VERSION ""

NS_ :

BS_:

BU_: Turbocharger OnBoardDataLogger OffBoardDiagnosticTool2 OffBoardDiagnosticTool1 FileServer ParkingBrakeController SeatControl2 FanDriveController SteeringColumnUnit CommunicationUnitRadio CommunicationUnitSatellite CommunicationUnitCellular PropulsionBatteryCharger ChassisController2 ChassisController1 EngineValveControl AuxiliaryHeater2 AuxiliaryHeater1 ClutchUnit RampControl InformationSystem1 SuspensionSystemController2 OilSensor VehicleDynamicStability ExhaustEmissionController TransmissionDisplay2 TransmissionDisplay1 ClimateControl2 WaterPumpController RearAxleSteeringController LightingOperatorControl SeatController1 IgnitionController2 IgnitionController1 TirePressureController CabController2 CabController1 PneumaticSystemController SuspensionSystemController1 HydraulicPumpController EnduranceBrakingSystem RetarderExhaustEngine2 OnBoardDiagnosticUnit HeadwayController RetarderExhaustEngine1 CabDisplay1 ManagementComputer VirtualTerminal OffVehicleGateway PowerTakeOffFront HitchControl AuxiliaryValveControl BodyController TractorTrailerBridge1 StarterSystem ElectricalSystem VehicleSecurity VehicleNavigation AerodynamicControl ElectricalChargingSystem ClimateControl1 TripRecorder InstrumentCluster SuspensionDriveAxle2 SuspensionDriveAxle1 SuspensionSteerAxle SteeringController FuelSystem CruiseControl RetarderDriveline RetarderEngine BrakesDriveAxle2 BrakesDriveAxle1 BrakesSystemController BrakesSteerAxle AxleDrive2 AxleDrive1 AxleSteering PowerTakeOff ShiftConsoleSecondary ShiftConsolePrimary Transmission2 Transmission1 Engine2 Engine1

BO_ 3221225472 VECTOR__INDEPENDENT_SIG_MSG: 0 Vector__XXX
 SG_ EngIntakeManifold2Press : 24|8@1+ (2,0) [0|500] "kPa" Vector__XXX
 SG_ EngIntakeManifold1AbsPressHiRes : 40|16@1+ (0.1,0) [0|6425.5] "kPa" Vector__XXX
 SG_ RearWasherFunction : 53|3@1+ (1,0) [0|7] "" Vector__XXX
 SG_ FrontOperatorWasherSwitch : 45|3@1+ (1,0) [0|7] "" Vector__XXX
 SG_ FrontNonoperatorWasherSwitch : 42|3@1+ (1,0) [0|7] "" Vector__XXX
 SG_ RearWiperDelayCtrl : 32|8@1+ (0.4,0) [0|100] "%" Vector__XXX
 SG_ FrontNonoperatorWiperDelayCtrl : 24|8@1+ (0.4,0) [0|100] "%" Vector__XXX
 SG_ FrontOperatorWiperDelayCtrl : 16|8@1+ (0.4,0) [0|100] "%" Vector__XXX
 SG_ RearWiperSwitch : 12|4@1+ (1,0) [0|15] "" Vector__XXX
 SG_ FrontOperatorWiperSwitch : 4|4@1+ (1,0) [0|15] "" Vector__XXX
 SG_ FrontNonoperatorWiperSwitch : 0|4@1+ (1,0) [0|15] "" Vector__XXX
 SG_ OprtrsDesiredDelayedLampOffTime : 24|16@1+ (1,0) [0|64255] "s" Vector__XXX
 SG_ OperatorsDesiredBacklight : 16|8@1+ (0.4,0) [0|100] "%" Vector__XXX
 SG_ HighLowBeamSwitch : 14|2@1+ (1,0) [0|3] "" Vector__XXX
 SG_ HazardLightSwitch : 12|2@1+ (1,0) [0|3] "" Vector__XXX
 SG_ TurnSignalSwitch : 8|4@1+ (1,0) [0|15] "" Vector__XXX
 SG_ MainLightSwitch : 4|4@1+ (1,0) [0|15] "" Vector__XXX
 SG_ WorkLightSwitch : 0|4@1+ (1,0) [0|15] "" Vector__XXX
 SG_ EngAltDroopAuxInputSelect : 28|4@1+ (1,0) [0|15] "" Vector__XXX
 SG_ EngAltDroopRemoteAccelSelect : 24|4@1+ (1,0) [0|15] "" Vector__XXX
 SG_ EngAltDroopAccel2Select : 20|4@1+ (1,0) [0|15] "" Vector__XXX
 SG_ EngAltDroopAccel1Select : 16|4@1+ (1,0) [0|15] "" Vector__XXX
 SG_ EngAltRatingSelect : 8|8@1+ (1,0) [0|255] "" Vector__XXX
 SG_ EngAltLowIdleSwitch : 4|2@1+ (1,0) [0|3] "" Vector__XXX
 SG_ EngSynchronizationSwitch : 2|2@1+ (1,0) [0|3] "" Vector__XXX
 SG_ EngAuxGovernorSwitch : 0|2@1+ (1,0) [0|3] "" Vector__XXX
 SG_ EngOprtrPrmryIntrmdtSpeedSelect : 0|4@1+ (1,0) [0|15] "" Vector__XXX
 SG_ TotalCountOfConfigChangesMade : 0|16@1+ (1,0) [0|64255] "counts" Vector__XXX
 SG_ EngOprtrPrmryIntrmdtSpdSlctStte : 0|4@1+ (1,0) [0|15] "" Vector__XXX
 SG_ EngAltDroopAuxInputSelectState : 28|4@1+ (1,0) [0|15] "" Vector__XXX
 SG_ EngAltDrpRemoteAccelSelectState : 24|4@1+ (1,0) [0|15] "" Vector__XXX
 SG_ EngAltDroopAccel2SelectState : 20|4@1+ (1,0) [0|15] "" Vector__XXX
 SG_ EngAltDroopAccel1SelectState : 16|4@1+ (1,0) [0|15] "" Vector__XXX
 SG_ EngAltRatingSelectState : 8|8@1+ (1,0) [0|255] "" Vector__XXX
 SG_ EngAltLowIdleSelectState : 4|2@1+ (1,0) [0|3] "" Vector__XXX
 SG_ EngMultiUnitSyncState : 2|2@1+ (1,0) [0|3] "" Vector__XXX
 SG_ EngAuxGovernorState : 0|2@1+ (1,0) [0|3] "" Vector__XXX
 SG_ EngStartEnableDevice2Config : 12|4@1+ (1,0) [0|15] "" Vector__XXX
 SG_ EngStartEnableDevice1Config : 8|4@1+ (1,0) [0|15] "" Vector__XXX
 SG_ EngStartEnableDevice2 : 2|2@1+ (1,0) [0|3] "" Vector__XXX
 SG_ EngStartEnableDevice1 : 0|2@1+ (1,0) [0|3] "" Vector__XXX
 SG_ ECUType : 24|8@1+ (1,0) [0|255] "" Vector__XXX
 SG_ ECULocation : 16|8@1+ (1,0) [0|255] "" Vector__XXX
 SG_ ECUSerialNumber : 8|8@1+ (1,0) [0|255] "" Vector__XXX
 SG_ ECUPartNumber : 0|8@1+ (1,0) [0|255] "" Vector__XXX
 SG_ BrakeTempWarning : 0|2@1+ (1,0) [0|3] "" Vector__XXX
 SG_ PrkngBrkeActuatorFullyActivated : 24|2@1+ (1,0) [0|3] "" Vector__XXX
 SG_ XBRAccelerationLimit : 16|8@1+ (0.1,-12.5) [-12.5|12.5] "m/s²" Vector__XXX
 SG_ XBRActiveCtrlMode : 12|4@1+ (1,0) [0|15] "" Vector__XXX
 SG_ XBRSystemState : 10|2@1+ (1,0) [0|3] "" Vector__XXX
 SG_ FoundationBrakeUse : 8|2@1+ (1,0) [0|3] "" Vector__XXX
 SG_ HillHolderMode : 5|3@1+ (1,0) [0|7] "" Vector__XXX
 SG_ HaltBrakeMode : 2|3@1+ (1,0) [0|7] "" Vector__XXX
 SG_ EngExhstVlvActtonSystemOilPress : 24|16@1+ (0.00390625,0) [0|251] "MPa" Vector__XXX
 SG_ EngExhstGsRcrcltion1OutletPress : 40|8@1+ (2,0) [0|500] "kPa" Vector__XXX
 SG_ EngExhstGsRcrcltion1IntakePress : 16|8@1+ (2,0) [0|500] "kPa" Vector__XXX
 SG_ EngIntkVlvActtionSystemOilPress : 0|16@1+ (0.00390625,0) [0|251] "MPa" Vector__XXX
 SG_ TransitRunStatus : 20|2@1+ (1,0) [0|3] "" Vector__XXX
 SG_ VehicleUseStatus : 18|2@1+ (1,0) [0|3] "" Vector__XXX
 SG_ SilentAlarmStatus : 16|2@1+ (1,0) [0|3] "" Vector__XXX
 SG_ PatronCount : 8|8@1+ (1,0) [0|250] "" Vector__XXX
 SG_ TypeOfPassengerCount : 0|8@1+ (1,0) [0|255] "" Vector__XXX
 SG_ NmbrOfBytsInMlpstIdentification : 0|8@1+ (1,0) [0|250] "" Vector__XXX
 SG_ Agency : 0|8@1+ (1,0) [0|255] "" Vector__XXX
 SG_ NmbrOfBytsInTrnstAssgndBlckIdntt : 24|8@1+ (1,0) [0|250] "" Vector__XXX
 SG_ NmbrOfBytsInTrnstAssgndRnIdntty : 16|8@1+ (1,0) [0|250] "" Vector__XXX
 SG_ NmbrOfBytsInTrnstAssgndRtIdntty : 8|8@1+ (1,0) [0|250] "" Vector__XXX
 SG_ VehicleID : 16|16@1+ (1,0) [0|65535] "counts" Vector__XXX
 SG_ StrobeActivationCtrlStatus : 14|2@1+ (1,0) [0|3] "" Vector__XXX
 SG_ TransitDoorEnable : 12|2@1+ (1,0) [0|3] "" Vector__XXX
 SG_ PriorityOfRespSentByEmitter : 8|4@1+ (1,0) [0|15] "" Vector__XXX
 SG_ IntersectionPreemptionRq_Resp : 6|2@1+ (1,0) [0|3] "" Vector__XXX
 SG_ TransitRouteIDUsage : 4|2@1+ (1,0) [0|3] "" Vector__XXX
 SG_ RangeCodeEnable : 2|2@1+ (1,0) [0|3] "" Vector__XXX
 SG_ DriversFareboxSecurityCode : 104|16@1+ (1,0) [0|65535] "counts" Vector__XXX
 SG_ AssignedBlock : 88|16@1+ (1,0) [0|65535] "counts" Vector__XXX
 SG_ AssignedRun : 72|16@1+ (1,0) [0|65535] "counts" Vector__XXX
 SG_ AssignedRoute : 56|16@1+ (1,0) [0|65535] "counts" Vector__XXX
 SG_ PatternNumber : 40|16@1+ (1,0) [0|65535] "counts" Vector__XXX
 SG_ TripNumber : 24|16@1+ (1,0) [0|65535] "counts" Vector__XXX
 SG_ FarePresets : 16|8@1+ (1,0) [0|255] "" Vector__XXX
 SG_ TripDirection : 8|4@1+ (1,0) [0|15] "" Vector__XXX
 SG_ TripStatus : 2|3@1+ (1,0) [0|7] "" Vector__XXX
 SG_ FareboxServiceStatus : 0|2@1+ (1,0) [0|3] "" Vector__XXX
 SG_ TransferSold : 56|8@1+ (1,0) [0|255] "" Vector__XXX
 SG_ RouteNumber : 40|12@1+ (1,0) [0|4095] "" Vector__XXX
 SG_ TransferType : 35|5@1+ (1,0) [0|31] "" Vector__XXX
 SG_ TypeOfService : 32|3@1+ (1,0) [0|7] "" Vector__XXX
 SG_ InitialFareAgency : 24|5@1+ (1,0) [0|31] "" Vector__XXX
 SG_ PassCategory : 20|4@1+ (1,0) [0|15] "" Vector__XXX
 SG_ FareValidity : 16|4@1+ (1,0) [0|15] "" Vector__XXX
 SG_ PaymentDetails : 12|4@1+ (1,0) [0|15] "" Vector__XXX
 SG_ TypeOfFare : 8|4@1+ (1,0) [0|15] "" Vector__XXX
 SG_ PassengerType : 4|4@1+ (1,0) [0|15] "" Vector__XXX
 SG_ TransactionType : 0|4@1+ (1,0) [0|15] "" Vector__XXX
 SG_ FareboxAlarmIdentifier : 8|7@1+ (1,0) [0|127] "" Vector__XXX
 SG_ FareboxEmergencyStatus : 0|2@1+ (1,0) [0|3] "" Vector__XXX
 SG_ ReferenceTirePress_33 m51 : 8|8@1+ (8,0) [0|2000] "kPa" Vector__XXX
 SG_ ReferenceTirePress_32 m50 : 8|8@1+ (8,0) [0|2000] "kPa" Vector__XXX
 SG_ ReferenceTirePress_31 m49 : 8|8@1+ (8,0) [0|2000] "kPa" Vector__XXX
 SG_ ReferenceTirePress_30 m48 : 8|8@1+ (8,0) [0|2000] "kPa" Vector__XXX
 SG_ ReferenceTirePress_23 m35 : 8|8@1+ (8,0) [0|2000] "kPa" Vector__XXX
 SG_ ReferenceTirePress_22 m34 : 8|8@1+ (8,0) [0|2000] "kPa" Vector__XXX
 SG_ ReferenceTirePress_21 m33 : 8|8@1+ (8,0) [0|2000] "kPa" Vector__XXX
 SG_ ReferenceTirePress_20 m32 : 8|8@1+ (8,0) [0|2000] "kPa" Vector__XXX
 SG_ ReferenceTirePress_13 m19 : 8|8@1+ (8,0) [0|2000] "kPa" Vector__XXX
 SG_ ReferenceTirePress_12 m18 : 8|8@1+ (8,0) [0|2000] "kPa" Vector__XXX
 SG_ ReferenceTirePress_11 m17 : 8|8@1+ (8,0) [0|2000] "kPa" Vector__XXX
 SG_ ReferenceTirePress_10 m16 : 8|8@1+ (8,0) [0|2000] "kPa" Vector__XXX
 SG_ ReferenceTirePress_01 m1 : 8|8@1+ (8,0) [0|2000] "kPa" Vector__XXX
 SG_ ReferenceTirePress_00 m0 : 8|8@1+ (8,0) [0|2000] "kPa" Vector__XXX
 SG_ NMHCConvertingCatalystCompleted : 60|1@1+ (1,0) [0|1] "" Vector__XXX
 SG_ NMHCConvertingCatalystEnabled : 44|1@1+ (1,0) [0|1] "" Vector__XXX
 SG_ NOxConvertingCatalystAdsorberCom : 59|1@1+ (1,0) [0|1] "" Vector__XXX
 SG_ NOxConvertingCatalystAdsorberEna : 43|1@1+ (1,0) [0|1] "" Vector__XXX
 SG_ DieselParticulateFilterCompleted : 58|1@1+ (1,0) [0|1] "" Vector__XXX
 SG_ DieselParticulateFilterEnabled : 42|1@1+ (1,0) [0|1] "" Vector__XXX
 SG_ BoostPressureControlSystemComple : 57|1@1+ (1,0) [0|1] "" Vector__XXX
 SG_ BoostPressureCtrlSystemEnabled : 41|1@1+ (1,0) [0|1] "" Vector__XXX
 SG_ MisfireMonitoringComplete : 28|1@1+ (1,0) [0|1] "" Vector__XXX
 SG_ MisfireMonitoringEnabled : 24|1@1+ (1,0) [0|0] "" Vector__XXX
 SG_ FuelSystemMonitoringEnabled : 25|1@1+ (1,0) [0|1] "" Vector__XXX
 SG_ ComprehensiveComptMonComplete : 30|1@1+ (1,0) [0|1] "" Vector__XXX
 SG_ ComprehensiveCompMonEnabled : 26|1@1+ (1,0) [0|1] "" Vector__XXX
 SG_ SecondAirSystemMonComplete : 51|1@1+ (1,0) [0|1] "" Vector__XXX
 SG_ SecondAirSystemMonEnabled : 35|1@1+ (1,0) [0|1] "" Vector__XXX
 SG_ OxygenSensorMonComplete : 53|1@1+ (1,0) [0|1] "" Vector__XXX
 SG_ OxygenSensorMonEnabled : 37|1@1+ (1,0) [0|1] "" Vector__XXX
 SG_ OxygenSensorHeaterMonComplete : 54|1@1+ (1,0) [0|1] "" Vector__XXX
 SG_ OxygenSensorHeaterMonEnabled : 38|1@1+ (1,0) [0|1] "" Vector__XXX
 SG_ HeatedCatalystMonComplete : 49|1@1+ (1,0) [0|1] "" Vector__XXX
 SG_ HeatedCatalystMonEnabled : 33|1@1+ (1,0) [0|1] "" Vector__XXX
 SG_ EvaporativeSystemMonComplete : 50|1@1+ (1,0) [0|1] "" Vector__XXX
 SG_ EvaporativeSystemMonEnabled : 34|1@1+ (1,0) [0|1] "" Vector__XXX
 SG_ EGRSystemMonitoringComplete : 55|1@1+ (1,0) [0|1] "" Vector__XXX
 SG_ EGRSystemMonitoringEnabled : 39|1@1+ (1,0) [0|1] "" Vector__XXX
 SG_ ColdStartAidSystemMonComplete : 56|1@1+ (1,0) [0|1] "" Vector__XXX
 SG_ ColdStartAidSystemMonEnabled : 40|1@1+ (1,0) [0|1] "" Vector__XXX
 SG_ CatalystMonComplete : 48|1@1+ (1,0) [0|1] "" Vector__XXX
 SG_ CatalystMonEnabled : 32|1@1+ (1,0) [0|1] "" Vector__XXX
 SG_ ACSystemRefrigerantMonComplete : 52|1@1+ (1,0) [0|1] "" Vector__XXX
 SG_ ACSystemRefrigerantMonEnabled : 36|1@1+ (1,0) [0|1] "" Vector__XXX
 SG_ FuelSystemMonitoringComplete : 29|1@1+ (1,0) [0|1] "" Vector__XXX
 SG_ NumOfWarmUpsSinceDTCsCleared : 16|8@1+ (1,0) [0|250] "" Vector__XXX
 SG_ TimeSinceEngineStart : 0|16@1+ (1,0) [0|64255] "sec" Vector__XXX
 SG_ ExpandedFreezeFrameLength : 0|8@1+ (1,0) [0|255] "Byte" Vector__XXX
 SG_ SPNSupported1High : 21|3@1+ (1,0) [0|7] "" Vector__XXX
 SG_ SPNSupportTypeSTR3 : 82|1@1+ (1,0) [0|1] "" Vector__XXX
 SG_ SPNSupportTypeSTR2 : 81|1@1+ (1,0) [0|1] "" Vector__XXX
 SG_ SPNSupportTypeEFF3 : 80|1@1+ (1,0) [0|1] "" Vector__XXX
 SG_ SPNSupportTypeEFF2 : 48|1@1+ (1,0) [0|1] "" Vector__XXX
 SG_ SPNSupportTypeDS3 : 50|1@1+ (1,0) [0|1] "" Vector__XXX
 SG_ SPNSupportTypeDS2 : 49|1@1+ (1,0) [0|1] "" Vector__XXX
 SG_ SPNSupported3High : 85|3@1+ (1,0) [0|7] "" Vector__XXX
 SG_ SPNSupported2High : 53|3@1+ (1,0) [0|7] "" Vector__XXX
 SG_ SPNSupported3 : 64|16@1+ (1,0) [0|65535] "" Vector__XXX
 SG_ SPNSupported2 : 32|16@1+ (1,0) [0|65535] "" Vector__XXX
 SG_ SPNDataLength3 : 88|8@1+ (1,0) [0|240] "" Vector__XXX
 SG_ SPNSupportTypeSTR1 : 18|1@1+ (1,0) [0|1] "" Vector__XXX
 SG_ SPNSupportTypeDS1 : 17|1@1+ (1,0) [0|1] "" Vector__XXX
 SG_ SPNSupportTypeEFF1 : 16|1@1+ (1,0) [0|1] "" Vector__XXX
 SG_ SPNDataLength2 : 56|8@1+ (1,0) [0|240] "" Vector__XXX
 SG_ SPNDataLength1 : 24|8@1+ (1,0) [0|240] "" Vector__XXX
 SG_ SPNSupported1 : 0|16@1+ (1,0) [0|65535] "" Vector__XXX
 SG_ EngAirStartPress : 0|8@1+ (4,0) [0|1000] "kPa" Vector__XXX
 SG_ EngTurboOilLevelSwitch : 30|2@1+ (1,0) [0|3] "" Vector__XXX
 SG_ EngTurbo1Speed : 8|16@1+ (4,0) [0|257020] "rpm" Vector__XXX
 SG_ EngTurboLubeOilPress1 : 0|8@1+ (4,0) [0|1000] "kPa" Vector__XXX
 SG_ EngTotalIdleHours : 32|32@1+ (0.05,0) [0|210554060.75] "hr" Vector__XXX
 SG_ EngTotalIdleFuelUsed : 0|32@1+ (0.5,0) [0|2105540607.5] "L" Vector__XXX
 SG_ EngInjectorMeteringRail2Press : 48|16@1+ (0.00390625,0) [0|251] "MPa" Vector__XXX
 SG_ EngInjectorTimingRail1Press : 32|16@1+ (0.00390625,0) [0|251] "MPa" Vector__XXX
 SG_ EngInjectorMeteringRail1Press : 16|16@1+ (0.00390625,0) [0|251] "MPa" Vector__XXX
 SG_ EngInjectionCtrlPress : 0|16@1+ (0.00390625,0) [0|251] "MPa" Vector__XXX
 SG_ NmbrOfSftwrIdentificationFields : 0|8@1+ (1,0) [0|250] "steps" Vector__XXX
 SG_ SoftwareID3 : 24|8@1+ (1,0) [0|255] "" Vector__XXX
 SG_ SoftwareID2 : 16|8@1+ (1,0) [0|255] "" Vector__XXX
 SG_ SoftwareID1 : 8|8@1+ (1,0) [0|255] "" Vector__XXX
 SG_ AuxI_O16 : 24|2@1+ (1,0) [0|3] "" Vector__XXX
 SG_ AuxI_O15 : 26|2@1+ (1,0) [0|3] "" Vector__XXX
 SG_ AuxI_O14 : 28|2@1+ (1,0) [0|3] "" Vector__XXX
 SG_ AuxI_O13 : 30|2@1+ (1,0) [0|3] "" Vector__XXX
 SG_ AuxI_O12 : 16|2@1+ (1,0) [0|3] "" Vector__XXX
 SG_ AuxI_O11 : 18|2@1+ (1,0) [0|3] "" Vector__XXX
 SG_ AuxI_O10 : 20|2@1+ (1,0) [0|3] "" Vector__XXX
 SG_ AuxI_O09 : 22|2@1+ (1,0) [0|3] "" Vector__XXX
 SG_ AuxI_O08 : 8|2@1+ (1,0) [0|3] "" Vector__XXX
 SG_ AuxI_O07 : 10|2@1+ (1,0) [0|3] "" Vector__XXX
 SG_ AuxI_O06 : 12|2@1+ (1,0) [0|3] "" Vector__XXX
 SG_ AuxI_O05 : 14|2@1+ (1,0) [0|3] "" Vector__XXX
 SG_ AuxI_O04 : 0|2@1+ (1,0) [0|3] "" Vector__XXX
 SG_ AuxI_O03 : 2|2@1+ (1,0) [0|3] "" Vector__XXX
 SG_ AuxI_O02 : 4|2@1+ (1,0) [0|3] "" Vector__XXX
 SG_ AuxI_O01 : 6|2@1+ (1,0) [0|3] "" Vector__XXX
 SG_ AuxI_OChannel2 : 48|16@1+ (1,0) [0|64255] "counts" Vector__XXX
 SG_ AuxI_OChannel1 : 32|16@1+ (1,0) [0|64255] "counts" Vector__XXX
 SG_ AddressAssignment : 64|8@1+ (1,0) [0|255] "" Vector__XXX
 SG_ Alt4Status : 22|2@1+ (1,0) [0|3] "" Vector__XXX
 SG_ Alt3Status : 20|2@1+ (1,0) [0|3] "" Vector__XXX
 SG_ Alt2Status : 18|2@1+ (1,0) [0|3] "" Vector__XXX
 SG_ Alt1Status : 16|2@1+ (1,0) [0|3] "" Vector__XXX
 SG_ AltSpeed : 0|16@1+ (0.5,0) [0|32127.5] "rpm" Vector__XXX
 SG_ TestIdentifierSupported : 0|64@1+ (1,0) [1|1.8446744074e+19] "" Vector__XXX
 SG_ TestType : 8|8@1+ (1,0) [1|64] "" Vector__XXX
 SG_ BoostPressureControlSystemStatus : 57|1@1- (1,0) [0|0] "" Vector__XXX
 SG_ DieselParticulateFilterStatus : 58|1@1- (1,0) [0|0] "" Vector__XXX
 SG_ NOxConvertingCatalystAdsorberSta : 59|1@1- (1,0) [0|0] "" Vector__XXX
 SG_ NMHCConvertingCatalystStatus : 60|1@1- (1,0) [0|0] "" Vector__XXX
 SG_ BoostPressureControlSystemSuppor : 41|1@1- (1,0) [0|0] "" Vector__XXX
 SG_ DieselParticulateFilterSupport : 42|1@1- (1,0) [0|0] "" Vector__XXX
 SG_ NOxConvertingCatalystAdsorberSup : 43|1@1- (1,0) [0|0] "" Vector__XXX
 SG_ NMHCConvertingCatalystSupport : 44|1@1- (1,0) [0|0] "" Vector__XXX
 SG_ MisfireMonitoringSupport : 24|1@1+ (1,0) [0|0] "" Vector__XXX
 SG_ OBDCompliance : 16|8@1+ (1,0) [0|240] "" Vector__XXX
 SG_ PreviouslyActiveTroubleCodes : 8|8@1+ (1,0) [0|240] "" Vector__XXX
 SG_ ActiveTroubleCodes : 0|8@1+ (1,0) [0|240] "" Vector__XXX
 SG_ SecondAirSystemMonStatus : 51|1@1+ (1,0) [0|1] "" Vector__XXX
 SG_ EvaporativeSystemMonStatus : 50|1@1+ (1,0) [0|1] "" Vector__XXX
 SG_ ACSystemRefrigerantMonStatus : 52|1@1+ (1,0) [0|1] "" Vector__XXX
 SG_ OxygenSensorHeaterMonStatus : 54|1@1+ (1,0) [0|1] "" Vector__XXX
 SG_ OxygenSensorMonStatus : 53|1@1+ (1,0) [0|1] "" Vector__XXX
 SG_ EGRSystemMonitoringStatus : 55|1@1+ (1,0) [0|1] "" Vector__XXX
 SG_ CatalystMonStatus : 48|1@1+ (1,0) [0|1] "" Vector__XXX
 SG_ ColdStartAidSystemMonStatus : 56|1@1+ (1,0) [0|1] "" Vector__XXX
 SG_ HeatedCatalystMonStatus : 49|1@1+ (1,0) [0|0] "" Vector__XXX
 SG_ CatalystMonSupp : 32|1@1+ (1,0) [0|1] "" Vector__XXX
 SG_ ColdStartAidSystemMonSupp : 40|1@1+ (1,0) [0|1] "" Vector__XXX
 SG_ HeatedCatalystMonSupp : 33|1@1+ (1,0) [0|0] "" Vector__XXX
 SG_ EvaporativeSystemMonSupp : 34|1@1+ (1,0) [0|1] "" Vector__XXX
 SG_ SecondAirSystemMonSupp : 35|1@1+ (1,0) [0|1] "" Vector__XXX
 SG_ ACSystemRefrigerantMonSupp : 36|1@1+ (1,0) [0|1] "" Vector__XXX
 SG_ OxygenSensorMonSupp : 37|1@1+ (1,0) [0|1] "" Vector__XXX
 SG_ OxygenSensorHeaterMonSupp : 38|1@1+ (1,0) [0|1] "" Vector__XXX
 SG_ EGRSystemMonitoringSupp : 39|1@1+ (1,0) [0|1] "" Vector__XXX
 SG_ MisfireMonitoringStatus : 28|1@1+ (1,0) [0|0] "" Vector__XXX
 SG_ ComprehensiveCompMonStatus : 30|1@1+ (1,0) [0|1] "" Vector__XXX
 SG_ FuelSystemMonitoringStatus : 29|1@1+ (1,0) [0|1] "" Vector__XXX
 SG_ ComprehensiveComponentMonSupp : 26|1@1+ (1,0) [0|0] "" Vector__XXX
 SG_ FuelSystemMonitoringSupport : 25|1@1+ (1,0) [0|1] "" Vector__XXX
 SG_ EngIntakeManifold1Press : 48|8@1+ (2,0) [0|500] "kPa" Vector__XXX
 SG_ FreezeFrameLength : 0|8@1+ (1,0) [0|255] "Byte" Vector__XXX
 SG_ EngSpeed : 56|16@1+ (0.125,0) [0|8031.875] "rpm" Vector__XXX
 SG_ EngTorqueMode : 40|4@1+ (1,0) [0|15] "" Vector__XXX
 SG_ WheelBasedVehicleSpeed : 88|16@1+ (0.00390625,0) [0|250.996] "km/h" Vector__XXX
 SG_ EngPercentLoadAtCurrentSpeed : 72|8@1+ (1,0) [0|250] "%" Vector__XXX
 SG_ PneumaticControlLine : 20|2@1+ (1,0) [0|1] "" Vector__XXX
 SG_ ABSOffroadRequest : 18|2@1+ (1,0) [0|1] "" Vector__XXX
 SG_ TwoElCircuitsBrakeDemand : 16|2@1+ (1,0) [0|1] "" Vector__XXX
 SG_ BodyPressure : 48|8@1+ (0.1,0) [0|25] "bar" Vector__XXX
 SG_ BodyFluidLevel : 32|16@1+ (2,0) [0|128510] "L" Vector__XXX
 SG_ ThermalBodyTemperature : 24|8@1+ (1,-125) [-125|125] "°C" Vector__XXX
 SG_ RearObstacleDistance : 16|8@1+ (2,0) [0|500] "cm" Vector__XXX
 SG_ AntiTheftDeviceStatus : 2|2@1+ (1,0) [0|1] "" Vector__XXX
 SG_ ODDStatus : 0|2@1+ (1,0) [0|1] "" Vector__XXX
 SG_ TransInertiaBrakeActuator : 46|2@1+ (1,0) [0|3] "" Vector__XXX
 SG_ TransDefuelActuator : 44|2@1+ (1,0) [0|3] "" Vector__XXX
 SG_ TransLockupClutchActuator : 42|2@1+ (1,0) [0|3] "" Vector__XXX
 SG_ TransClutchActuator : 40|2@1+ (1,0) [0|3] "" Vector__XXX
 SG_ TransSplitterIndirectActuator : 38|2@1+ (1,0) [0|3] "" Vector__XXX
 SG_ TransSplitterDirectActuator : 36|2@1+ (1,0) [0|3] "" Vector__XXX
 SG_ TransRangeLowActuator : 34|2@1+ (1,0) [0|3] "" Vector__XXX
 SG_ TransRangeHighActuator : 32|2@1+ (1,0) [0|3] "" Vector__XXX
 SG_ TransShiftFingerGearActuator2 : 30|2@1+ (1,0) [0|3] "" Vector__XXX
 SG_ TransShiftFingerRailActuator2 : 28|2@1+ (1,0) [0|3] "" Vector__XXX
 SG_ TransShiftFingerGearActuator1 : 26|2@1+ (1,0) [0|3] "" Vector__XXX
 SG_ TransShiftFingerRailActuator1 : 24|2@1+ (1,0) [0|3] "" Vector__XXX
 SG_ TrnsShftFngrCenterRailIndicator : 20|2@1+ (1,0) [0|3] "" Vector__XXX
 SG_ TrnsShftFngrEngagementIndicator : 18|2@1+ (1,0) [0|3] "" Vector__XXX
 SG_ TrnsShiftFingerNeutralIndicator : 16|2@1+ (1,0) [0|3] "" Vector__XXX
 SG_ TransShiftFingerRailPos : 8|8@1+ (0.4,0) [0|100] "%" Vector__XXX
 SG_ TransShiftFingerGearPos : 0|8@1+ (0.4,0) [0|100] "%" Vector__XXX
 SG_ PneumaticSupplyPressure : 56|8@1+ (5,0) [0|1250] "kPa" Vector__XXX
 SG_ BrakeTemperature : 48|8@1+ (10,0) [0|2500] "°C" Vector__XXX
 SG_ BrakeLining : 40|8@1+ (0.4,0) [0|100] "%" Vector__XXX
 SG_ TyrePressure : 32|8@1+ (10,0) [0|2500] "kPa" Vector__XXX
 SG_ TyreWheelIdentTemp2 : 28|4@1+ (1,0) [0|15] "" Vector__XXX
 SG_ TyreWheelIdentTemp1 : 24|4@1+ (1,0) [0|15] "" Vector__XXX
 SG_ TyreWheelIdentPressure2 : 12|4@1+ (1,0) [0|15] "" Vector__XXX
 SG_ TyreWheelIdentPressure1 : 8|4@1+ (1,0) [0|15] "" Vector__XXX
 SG_ TyreWheelIdentLining2 : 20|4@1+ (1,0) [0|15] "" Vector__XXX
 SG_ TyreWheelIdentLining1 : 16|4@1+ (1,0) [0|15] "" Vector__XXX
 SG_ VehiclePneumSupplySuff : 6|2@1+ (1,0) [0|1] "" Vector__XXX
 SG_ BrakeTemperatureStatus : 4|2@1+ (1,0) [0|1] "" Vector__XXX
 SG_ BrakeLiningSufficient : 2|2@1+ (1,0) [0|1] "" Vector__XXX
 SG_ TyrePressureSufficient : 0|2@1+ (1,0) [0|1] "" Vector__XXX
 SG_ TransSynchronizerBrakeValue : 8|8@1+ (0.4,0) [0|100] "%" Vector__XXX
 SG_ TransSynchronizerClutchValue : 0|8@1+ (0.4,0) [0|100] "%" Vector__XXX
 SG_ ReferenceRetarderTorque : 48|16@1+ (1,0) [0|64255] "Nm" Vector__XXX
 SG_ AxleLoadSum : 32|16@1+ (2,0) [0|128510] "kg" Vector__XXX
 SG_ LoadingRampApproachAssist : 24|2@1+ (1,0) [0|1] "" Vector__XXX
 SG_ SpringBrakeEngaged : 22|2@1+ (1,0) [0|1] "" Vector__XXX
 SG_ ElectrLoadPropFunc : 18|2@1+ (1,0) [0|1] "" Vector__XXX
 SG_ SpringBrakeInstalled : 16|2@1+ (1,0) [0|1] "" Vector__XXX
 SG_ ElecSupplyOfNonBrakingSys : 14|2@1+ (1,0) [0|1] "" Vector__XXX
 SG_ AmberWarningSignalReq : 12|2@1+ (1,0) [0|1] "" Vector__XXX
 SG_ RedWarningSignalRequest : 10|2@1+ (1,0) [0|1] "" Vector__XXX
 SG_ VehicleElectrSupplySuff : 8|2@1+ (1,0) [0|1] "" Vector__XXX
 SG_ TransForwardDirectionSwitch : 12|2@1+ (1,0) [0|3] "" Vector__XXX
 SG_ TransNeutralSwitch : 10|2@1+ (1,0) [0|3] "" Vector__XXX
 SG_ TransReverseDirectionSwitch : 8|2@1+ (1,0) [0|3] "" Vector__XXX
 SG_ TransLowRangeSenseSwitch : 2|2@1+ (1,0) [0|3] "" Vector__XXX
 SG_ TransHighRangeSenseSwitch : 0|2@1+ (1,0) [0|3] "" Vector__XXX
 SG_ TransOutputRetarder : 0|2@1+ (1,0) [0|3] "" Vector__XXX
 SG_ HighResolutionTripDistance : 32|32@1+ (5,0) [0|21055406] "km" Vector__XXX
 SG_ HghRslutionTotalVehicleDistance : 0|32@1+ (5,0) [0|21055406] "km" Vector__XXX
 SG_ ServiceComponentIdentificationB : 24|8@1+ (1,0) [0|250] "ID" Vector__XXX
 SG_ ServiceComponentIdentificationA : 0|8@1+ (1,0) [0|250] "ID" Vector__XXX
 SG_ SrvceDelay_OperationalTimeBased : 48|16@1+ (1,-32127) [-32127|32128] "hr" Vector__XXX
 SG_ ServiceDelay_CalendarTimeBased : 32|8@1+ (1,-125) [-125|125] "weeks" Vector__XXX
 SG_ ServiceDistance : 8|16@1+ (5,-160635) [-160635|160640] "km" Vector__XXX
 SG_ RlativeSpeedRearAxle2RightWheel : 56|8@1+ (0.0625,-7.8125) [-7.8125|7.8125] "km/h" Vector__XXX
 SG_ RelativeSpeedRearAxle2LeftWheel : 48|8@1+ (0.0625,-7.8125) [-7.8125|7.8125] "km/h" Vector__XXX
 SG_ RlativeSpeedRearAxle1RightWheel : 40|8@1+ (0.0625,-7.8125) [-7.8125|7.8125] "km/h" Vector__XXX
 SG_ RelativeSpeedRearAxle1LeftWheel : 32|8@1+ (0.0625,-7.8125) [-7.8125|7.8125] "km/h" Vector__XXX
 SG_ RlativeSpeedFrontAxleRightWheel : 24|8@1+ (0.0625,-7.8125) [-7.8125|7.8125] "km/h" Vector__XXX
 SG_ RelativeSpeedFrontAxleLeftWheel : 16|8@1+ (0.0625,-7.8125) [-7.8125|7.8125] "km/h" Vector__XXX
 SG_ FrontAxleSpeed : 0|16@1+ (0.00390625,0) [0|250.996] "km/h" Vector__XXX
 SG_ EngRotationDirection : 32|2@1+ (1,0) [0|3] "" Vector__XXX
 SG_ CrnkAttmptCntOnPrsntStrtAttempt : 40|8@1+ (1,0) [0|250] "" Vector__XXX
 SG_ EngIntakeManifoldPressCtrlMode : 34|2@1+ (1,0) [0|3] "" Vector__XXX
 SG_ EngRatedSpeed : 16|16@1+ (0.125,0) [0|8031.875] "rpm" Vector__XXX
 SG_ EngRatedPower : 0|16@1+ (0.5,0) [0|32127.5] "kW" Vector__XXX
 SG_ FanSpeed : 16|16@1+ (0.125,0) [0|8031.875] "rpm" Vector__XXX
 SG_ FanDriveState : 8|4@1+ (1,0) [0|15] "" Vector__XXX
 SG_ EstPercentFanSpeed : 0|8@1+ (0.4,0) [0|100] "%" Vector__XXX
 SG_ HydFanMotorPress : 32|16@1+ (0.5,0) [0|32127.5] "kPa" Vector__XXX
 SG_ FanDriveBypassCmdStatus : 48|8@1+ (0.4,0) [0|100] "%" Vector__XXX
 SG_ TripServiceBrakeApps : 96|32@1+ (1,0) [0|4227858431] "appl" Vector__XXX
 SG_ TripServiceBrakeDistance : 64|32@1+ (0.125,0) [0|526385151.9] "km" Vector__XXX
 SG_ TripCompressionBrakeDistance : 32|32@1+ (0.125,0) [0|526385151.9] "km" Vector__XXX
 SG_ TotalCompressionBrakeDistance : 0|32@1+ (0.125,0) [0|526385151.9] "km" Vector__XXX
 SG_ TripFanOnTimeDueToAManualSwitch : 64|32@1+ (0.05,0) [0|210554060.75] "hr" Vector__XXX
 SG_ TripFanOnTime : 0|32@1+ (0.05,0) [0|210554060.75] "hr" Vector__XXX
 SG_ TripFanOnTimeDueToA_CSystem : 96|32@1+ (0.05,0) [0|210554060.75] "hr" Vector__XXX
 SG_ TripFanOnTimeDueToEngSystem : 32|32@1+ (0.05,0) [0|210554060.75] "hr" Vector__XXX
 SG_ TripDistanceInTopGear : 64|32@1+ (0.125,0) [0|526385151.9] "km" Vector__XXX
 SG_ TripGearDownDistance : 32|32@1+ (0.125,0) [0|526385151.9] "km" Vector__XXX
 SG_ TripDistanceOnVSL : 0|32@1+ (0.125,0) [0|526385151.9] "km" Vector__XXX
 SG_ TripCruiseFuelUsed : 128|32@1+ (0.5,0) [0|2105540607.5] "L" Vector__XXX
 SG_ TripVehicleIdleFuelUsed : 96|32@1+ (0.5,0) [0|2105540607.5] "L" Vector__XXX
 SG_ TripDriveFuelUsed : 0|32@1+ (0.5,0) [0|2105540607.5] "L" Vector__XXX
 SG_ TrpPTOGovernorNonmovingFuelUsed : 64|32@1+ (0.5,0) [0|2105540607.5] "L" Vector__XXX
 SG_ TripPTOGovernorMovingFuelUsed : 32|32@1+ (0.5,0) [0|2105540607.5] "L" Vector__XXX
 SG_ TripDriveFuelEconomy : 160|16@1+ (0.001953125,0) [0|125.5] "km/L" Vector__XXX
 SG_ TripDriveFuelEconomy : 160|16@1+ (0.001953125,0) [0|125.5] "km/kg" Vector__XXX
 SG_ TrpPTOGovernorNonmovingFuelUsed : 64|32@1+ (0.5,0) [0|2105540607.5] "kg" Vector__XXX
 SG_ TripVehicleIdleFuelUsed : 96|32@1+ (0.5,0) [0|2105540607.5] "kg" Vector__XXX
 SG_ TripCruiseFuelUsed : 128|32@1+ (0.5,0) [0|2105540607.5] "kg" Vector__XXX
 SG_ TripDriveFuelUsed : 0|32@1+ (0.5,0) [0|2105540607.5] "kg" Vector__XXX
 SG_ TripPTOGovernorMovingFuelUsed : 32|32@1+ (0.5,0) [0|2105540607.5] "kg" Vector__XXX
 SG_ TotalEngCruiseTime : 48|32@1+ (0.05,0) [0|210554060.75] "hr" Vector__XXX
 SG_ TotalDriveAverageLoadFactor : 40|8@1+ (0.4,0) [0|100] "%" Vector__XXX
 SG_ TripDriveAverageLoadFactor : 32|8@1+ (0.4,0) [0|100] "%" Vector__XXX
 SG_ TripAverageEngSpeed : 16|16@1+ (0.125,0) [0|8031.875] "rpm" Vector__XXX
 SG_ TripMaxEngSpeed : 0|16@1+ (0.125,0) [0|8031.875] "rpm" Vector__XXX
 SG_ TripCruiseDistance : 16|32@1+ (0.125,0) [0|526385151.9] "km" Vector__XXX
 SG_ TripMaxVehicleSpeed : 0|16@1+ (0.00390625,0) [0|250.996] "km/h" Vector__XXX
 SG_ TripSuddenDecelerations : 48|16@1+ (1,0) [0|64255] "counts" Vector__XXX
 SG_ TrpNmberOfIdleShutdownOverrides : 32|16@1+ (1,0) [0|64255] "counts" Vector__XXX
 SG_ TripNumberOfIdleShutdowns : 16|16@1+ (1,0) [0|64255] "counts" Vector__XXX
 SG_ TripNumberOfHotShutdowns : 0|16@1+ (1,0) [0|64255] "counts" Vector__XXX
 SG_ TripTimeInDerateByEng : 96|32@1+ (0.05,0) [0|210554060.75] "hr" Vector__XXX
 SG_ TripTimeInGearDown : 64|32@1+ (0.05,0) [0|210554060.75] "hr" Vector__XXX
 SG_ TripTimeInTopGear : 32|32@1+ (0.05,0) [0|210554060.75] "hr" Vector__XXX
 SG_ TripTimeInVSL : 0|32@1+ (0.05,0) [0|210554060.75] "hr" Vector__XXX
 SG_ TotalEngPTOGovernorFuelUsed : 0|32@1+ (0.5,0) [0|2105540607.5] "L" Vector__XXX
 SG_ TripAverageFuelRate : 32|16@1+ (0.05,0) [0|3212.75] "L/h" Vector__XXX
 SG_ FlexibleFuelPercentage : 48|10@1+ (0.1,0) [0|102] "%" Vector__XXX
 SG_ TotalEngPTOGovernorFuelUsed : 0|32@1+ (0.5,0) [0|2105540607.5] "kg" Vector__XXX
 SG_ TripAverageFuelRate : 32|16@1+ (0.05,0) [0|3212.75] "kg/h" Vector__XXX
 SG_ EngFuelSpecificGravity : 48|16@1+ (0.0001,0) [0|6.4255] "" Vector__XXX
 SG_ TotalECURunTime : 32|32@1+ (0.05,0) [0|210554060.75] "hr" Vector__XXX
 SG_ TotalECUDistance : 0|32@1+ (0.125,0) [0|526385151.9] "km" Vector__XXX
 SG_ TripAirCompressorOnTime : 128|32@1+ (0.05,0) [0|210554060.75] "hr" Vector__XXX
 SG_ TripIdleTime : 96|32@1+ (0.05,0) [0|210554060.75] "hr" Vector__XXX
 SG_ TripEngRunningTime : 64|32@1+ (0.05,0) [0|210554060.75] "hr" Vector__XXX
 SG_ TripCruiseTime : 0|32@1+ (0.05,0) [0|210554060.75] "hr" Vector__XXX
 SG_ TripPTOGovernorTime : 32|32@1+ (0.05,0) [0|210554060.75] "hr" Vector__XXX
 SG_ TotalFuelUsed : 32|32@1+ (0.5,0) [0|2105540607.5] "kg" Vector__XXX
 SG_ TripFuel : 0|32@1+ (0.5,0) [0|2105540607.5] "kg" Vector__XXX
 SG_ ServiceBrakeCircuit2AirPress : 24|8@1+ (8,0) [0|2000] "kPa" Vector__XXX
 SG_ ServiceBrakeCircuit1AirPress : 16|8@1+ (8,0) [0|2000] "kPa" Vector__XXX
 SG_ AirCompressorStatus : 48|2@1+ (1,0) [0|3] "" Vector__XXX
 SG_ AirSuspensionSupplyPress : 40|8@1+ (8,0) [0|2000] "kPa" Vector__XXX
 SG_ AuxEquipmentSupplyPress : 32|8@1+ (8,0) [0|2000] "kPa" Vector__XXX
 SG_ ParkingAnd_OrTrailerAirPress : 8|8@1+ (8,0) [0|2000] "kPa" Vector__XXX
 SG_ PneumaticSupplyPress : 0|8@1+ (8,0) [0|2000] "kPa" Vector__XXX
 SG_ BrkAppPrssHghRngRrAxl3RghtWheel : 56|8@1+ (5,0) [0|1250] "kPa" Vector__XXX
 SG_ BrkAppPrssHghRngRrAxl3LeftWheel : 48|8@1+ (5,0) [0|1250] "kPa" Vector__XXX
 SG_ BrkAppPrssHghRngRrAxl2RghtWheel : 40|8@1+ (5,0) [0|1250] "kPa" Vector__XXX
 SG_ BrkAppPrssHghRngRrAxl2LeftWheel : 32|8@1+ (5,0) [0|1250] "kPa" Vector__XXX
 SG_ BrkAppPrssHghRngRrAxl1RghtWheel : 24|8@1+ (5,0) [0|1250] "kPa" Vector__XXX
 SG_ BrkAppPrssHghRngRrAxl1LeftWheel : 16|8@1+ (5,0) [0|1250] "kPa" Vector__XXX
 SG_ BrkAppPrssHghRngFrntAxlRghtWhel : 8|8@1+ (5,0) [0|1250] "kPa" Vector__XXX
 SG_ BrkAppPrssHghRngFrntAxlLftWheel : 0|8@1+ (5,0) [0|1250] "kPa" Vector__XXX
 SG_ BrkLnngRmnngRearAxle3RightWheel : 56|8@1+ (0.4,0) [0|100] "%" Vector__XXX
 SG_ BrkLnngRmningRearAxle3LeftWheel : 48|8@1+ (0.4,0) [0|100] "%" Vector__XXX
 SG_ BrkLnngRmnngRearAxle2RightWheel : 40|8@1+ (0.4,0) [0|100] "%" Vector__XXX
 SG_ BrkLnngRmningRearAxle2LeftWheel : 32|8@1+ (0.4,0) [0|100] "%" Vector__XXX
 SG_ BrkLnngRmnngRearAxle1RightWheel : 24|8@1+ (0.4,0) [0|100] "%" Vector__XXX
 SG_ BrkLnngRmningRearAxle1LeftWheel : 16|8@1+ (0.4,0) [0|100] "%" Vector__XXX
 SG_ BrkLnngRmnngFrontAxleRightWheel : 8|8@1+ (0.4,0) [0|100] "%" Vector__XXX
 SG_ BrkLnngRmningFrontAxleLeftWheel : 0|8@1+ (0.4,0) [0|100] "%" Vector__XXX
 SG_ ClutchLifeRemaining : 24|8@1+ (0.4,0) [0|100] "%" Vector__XXX
 SG_ LowestPossibleGear : 16|8@1+ (1,-125) [-125|125] "" Vector__XXX
 SG_ HighestPossibleGear : 8|8@1+ (1,-125) [-125|125] "" Vector__XXX
 SG_ RecommendedGear : 0|8@1+ (1,-125) [-125|125] "" Vector__XXX
 SG_ EngTurboWastegateValvePos : 24|8@1+ (0.4,0) [0|100] "%" Vector__XXX
 SG_ EngGsMssFlwSnsrFelingCorrection : 32|8@1+ (1,-125) [-125|125] "%" Vector__XXX
 SG_ EngDsiredAbsIntakeManifoldPress : 8|16@1+ (0.1,0) [0|6425.5] "kPa" Vector__XXX
 SG_ EngGasFuelCorrectionFactor : 0|8@1+ (1,0) [0|250] "%" Vector__XXX
 SG_ EngExhstGsOxygnSnsrClsdLpOprton : 62|2@1+ (1,0) [0|3] "" Vector__XXX
 SG_ EngExhstGsOxygnSnsrFlngCrrction : 48|8@1+ (1,-125) [-125|125] "%" Vector__XXX
 SG_ EngActualExhaustOxygen : 32|16@1+ (0.0025,0) [0|160.6375] "%" Vector__XXX
 SG_ EngDesiredExhaustOxygen : 16|16@1+ (0.0025,0) [0|160.6375] "%" Vector__XXX
 SG_ EngDesiredRatedExhaustOxygen : 0|16@1+ (0.0025,0) [0|160.6375] "%" Vector__XXX
 SG_ ArticulationAngle : 0|8@1+ (1,-125) [-125|125] "deg" Vector__XXX
 SG_ EngAltWinding3Temp : 32|8@1+ (1,-40) [-40|210] "deg C" Vector__XXX
 SG_ EngAltWinding2Temp : 24|8@1+ (1,-40) [-40|210] "deg C" Vector__XXX
 SG_ EngAltWinding1Temp : 16|8@1+ (1,-40) [-40|210] "deg C" Vector__XXX
 SG_ EngAltBearing2Temp : 8|8@1+ (1,-40) [-40|210] "deg C" Vector__XXX
 SG_ EngAltBearing1Temp : 0|8@1+ (1,-40) [-40|210] "deg C" Vector__XXX
 SG_ EngTurbo4BoostPress : 48|16@1+ (0.125,0) [0|8031.875] "kPa" Vector__XXX
 SG_ EngTurbo3BoostPress : 32|16@1+ (0.125,0) [0|8031.875] "kPa" Vector__XXX
 SG_ EngTurbo2BoostPress : 16|16@1+ (0.125,0) [0|8031.875] "kPa" Vector__XXX
 SG_ EngTurbo1BoostPress : 0|16@1+ (0.125,0) [0|8031.875] "kPa" Vector__XXX
 SG_ EngIntakeManifold6Temp : 32|8@1+ (1,-40) [-40|210] "deg C" Vector__XXX
 SG_ EngIntakeManifold5Temp : 24|8@1+ (1,-40) [-40|210] "deg C" Vector__XXX
 SG_ EngIntakeManifold4Temp : 16|8@1+ (1,-40) [-40|210] "deg C" Vector__XXX
 SG_ EngIntakeManifold3Temp : 8|8@1+ (1,-40) [-40|210] "deg C" Vector__XXX
 SG_ EngIntakeManifold2Temp : 0|8@1+ (1,-40) [-40|210] "deg C" Vector__XXX
 SG_ EngExhstGsRcrculation1DiffPress : 32|16@1+ (0.0078125,-250) [-250|251.99] "kPa" Vector__XXX
 SG_ EngExhaustGasRecirculation1Temp : 48|16@1+ (0.03125,-273) [-273|1734.96875] "deg C" Vector__XXX
 SG_ EngECUTemp : 16|16@1+ (0.03125,-273) [-273|1734.96875] "deg C" Vector__XXX
 SG_ EngOilTemp2 : 0|16@1+ (0.03125,-273) [-273|1734.96875] "deg C" Vector__XXX
 SG_ EngExhaustGasPort4Temp : 48|16@1+ (0.03125,-273) [-273|1734.96875] "deg C" Vector__XXX
 SG_ EngExhaustGasPort3Temp : 32|16@1+ (0.03125,-273) [-273|1734.96875] "deg C" Vector__XXX
 SG_ EngExhaustGasPort2Temp : 16|16@1+ (0.03125,-273) [-273|1734.96875] "deg C" Vector__XXX
 SG_ EngExhaustGasPort1Temp : 0|16@1+ (0.03125,-273) [-273|1734.96875] "deg C" Vector__XXX
 SG_ EngExhaustGasPort8Temp : 48|16@1+ (0.03125,-273) [-273|1734.96875] "deg C" Vector__XXX
 SG_ EngExhaustGasPort7Temp : 32|16@1+ (0.03125,-273) [-273|1734.96875] "deg C" Vector__XXX
 SG_ EngExhaustGasPort6Temp : 16|16@1+ (0.03125,-273) [-273|1734.96875] "deg C" Vector__XXX
 SG_ EngExhaustGasPort5Temp : 0|16@1+ (0.03125,-273) [-273|1734.96875] "deg C" Vector__XXX
 SG_ EngExhaustGasPort12Temp : 48|16@1+ (0.03125,-273) [-273|1734.96875] "deg C" Vector__XXX
 SG_ EngExhaustGasPort11Temp : 32|16@1+ (0.03125,-273) [-273|1734.96875] "deg C" Vector__XXX
 SG_ EngExhaustGasPort10Temp : 16|16@1+ (0.03125,-273) [-273|1734.96875] "deg C" Vector__XXX
 SG_ EngExhaustGasPort9Temp : 0|16@1+ (0.03125,-273) [-273|1734.96875] "deg C" Vector__XXX
 SG_ EngExhaustGasPort16Temp : 48|16@1+ (0.03125,-273) [-273|1734.96875] "deg C" Vector__XXX
 SG_ EngExhaustGasPort15Temp : 32|16@1+ (0.03125,-273) [-273|1734.96875] "deg C" Vector__XXX
 SG_ EngExhaustGasPort14Temp : 16|16@1+ (0.03125,-273) [-273|1734.96875] "deg C" Vector__XXX
 SG_ EngExhaustGasPort13Temp : 0|16@1+ (0.03125,-273) [-273|1734.96875] "deg C" Vector__XXX
 SG_ EngExhaustGasPort20Temp : 48|16@1+ (0.03125,-273) [-273|1734.96875] "deg C" Vector__XXX
 SG_ EngExhaustGasPort19Temp : 32|16@1+ (0.03125,-273) [-273|1734.96875] "deg C" Vector__XXX
 SG_ EngExhaustGasPort18Temp : 16|16@1+ (0.03125,-273) [-273|1734.96875] "deg C" Vector__XXX
 SG_ EngExhaustGasPort17Temp : 0|16@1+ (0.03125,-273) [-273|1734.96875] "deg C" Vector__XXX
 SG_ EngMainBearing4Temp : 48|16@1+ (0.03125,-273) [-273|1734.96875] "deg C" Vector__XXX
 SG_ EngMainBearing3Temp : 32|16@1+ (0.03125,-273) [-273|1734.96875] "deg C" Vector__XXX
 SG_ EngMainBearing2Temp : 16|16@1+ (0.03125,-273) [-273|1734.96875] "deg C" Vector__XXX
 SG_ EngMainBearing1Temp : 0|16@1+ (0.03125,-273) [-273|1734.96875] "deg C" Vector__XXX
 SG_ EngMainBearing8Temp : 48|16@1+ (0.03125,-273) [-273|1734.96875] "deg C" Vector__XXX
 SG_ EngMainBearing7Temp : 32|16@1+ (0.03125,-273) [-273|1734.96875] "deg C" Vector__XXX
 SG_ EngMainBearing6Temp : 16|16@1+ (0.03125,-273) [-273|1734.96875] "deg C" Vector__XXX
 SG_ EngMainBearing5Temp : 0|16@1+ (0.03125,-273) [-273|1734.96875] "deg C" Vector__XXX
 SG_ EngMainBearing11Temp : 32|16@1+ (0.03125,-273) [-273|1734.96875] "deg C" Vector__XXX
 SG_ EngMainBearing10Temp : 16|16@1+ (0.03125,-273) [-273|1734.96875] "deg C" Vector__XXX
 SG_ EngMainBearing9Temp : 0|16@1+ (0.03125,-273) [-273|1734.96875] "deg C" Vector__XXX
 SG_ EngTurbo4Speed : 40|16@1+ (4,0) [0|257020] "rpm" Vector__XXX
 SG_ EngTurbo3Speed : 24|16@1+ (4,0) [0|257020] "rpm" Vector__XXX
 SG_ EngTurbo2Speed : 8|16@1+ (4,0) [0|257020] "rpm" Vector__XXX
 SG_ EngTurboLubeOilPress2 : 0|8@1+ (4,0) [0|1000] "kPa" Vector__XXX
 SG_ EngTurbo4CompressorIntakeTemp : 48|16@1+ (0.03125,-273) [-273|1734.96875] "deg C" Vector__XXX
 SG_ EngTurbo3CompressorIntakeTemp : 32|16@1+ (0.03125,-273) [-273|1734.96875] "deg C" Vector__XXX
 SG_ EngTurbo2CompressorIntakeTemp : 16|16@1+ (0.03125,-273) [-273|1734.96875] "deg C" Vector__XXX
 SG_ EngTurbo1CompressorIntakeTemp : 0|16@1+ (0.03125,-273) [-273|1734.96875] "deg C" Vector__XXX
 SG_ EngTurbo4CompressorIntakePress : 48|16@1+ (0.0078125,-250) [-250|251.99] "kPa" Vector__XXX
 SG_ EngTurbo3CompressorIntakePress : 32|16@1+ (0.0078125,-250) [-250|251.99] "kPa" Vector__XXX
 SG_ EngTurbo2CompressorIntakePress : 16|16@1+ (0.0078125,-250) [-250|251.99] "kPa" Vector__XXX
 SG_ EngTurbo1CompressorIntakePress : 0|16@1+ (0.0078125,-250) [-250|251.99] "kPa" Vector__XXX
 SG_ EngTurbo4TurbineIntakeTemp : 48|16@1+ (0.03125,-273) [-273|1734.96875] "deg C" Vector__XXX
 SG_ EngTurbo3TurbineIntakeTemp : 32|16@1+ (0.03125,-273) [-273|1734.96875] "deg C" Vector__XXX
 SG_ EngTurbo2TurbineIntakeTemp : 16|16@1+ (0.03125,-273) [-273|1734.96875] "deg C" Vector__XXX
 SG_ EngTurbo1TurbineIntakeTemp : 0|16@1+ (0.03125,-273) [-273|1734.96875] "deg C" Vector__XXX
 SG_ EngTurbo4TurbineOutletTemp : 48|16@1+ (0.03125,-273) [-273|1734.96875] "deg C" Vector__XXX
 SG_ EngTurbo3TurbineOutletTemp : 32|16@1+ (0.03125,-273) [-273|1734.96875] "deg C" Vector__XXX
 SG_ EngTurbo2TurbineOutletTemp : 16|16@1+ (0.03125,-273) [-273|1734.96875] "deg C" Vector__XXX
 SG_ EngTurbo1TurbineOutletTemp : 0|16@1+ (0.03125,-273) [-273|1734.96875] "deg C" Vector__XXX
 SG_ EngTrbWstgteActuator1TempStatus : 53|3@1+ (1,0) [0|7] "" Vector__XXX
 SG_ EngTrbWstgtActtr1PreliminaryFMI : 48|5@1+ (1,0) [0|31] "" Vector__XXX
 SG_ EngDsrdTrbWastegateActuator2Pos : 56|8@1+ (0.4,0) [0|100] "%" Vector__XXX
 SG_ EngDsrdTrbWastegateActuator1Pos : 40|8@1+ (0.4,0) [0|100] "%" Vector__XXX
 SG_ EngTurboWastegateActuator4Pos : 24|8@1+ (0.4,0) [0|100] "%" Vector__XXX
 SG_ EngTurboWastegateActuator3Pos : 16|8@1+ (0.4,0) [0|100] "%" Vector__XXX
 SG_ EngTurboWastegateActuator2Pos : 8|8@1+ (0.4,0) [0|100] "%" Vector__XXX
 SG_ EngTurboWastegateActuator1Pos : 0|8@1+ (0.4,0) [0|100] "%" Vector__XXX
 SG_ EngTrbWstgtActuatorCtrlAirPress : 32|8@1+ (4,0) [0|1000] "kPa" Vector__XXX
 SG_ EngOperationTimeSinceRebuild : 0|32@1+ (1,0) [0|4211081215] "s" Vector__XXX
 SG_ SeaWaterPumpOutletPress : 16|8@1+ (2,0) [0|500] "kPa" Vector__XXX
 SG_ EngAuxCoolantTemp : 8|8@1+ (1,-40) [-40|210] "deg C" Vector__XXX
 SG_ EngAuxCoolantPress : 0|8@1+ (4,0) [0|1000] "kPa" Vector__XXX
 SG_ TurningGearEngaged : 18|2@1+ (1,0) [0|3] "" Vector__XXX
 SG_ SafetyWireStatus : 16|2@1+ (1,0) [0|3] "" Vector__XXX
 SG_ ElectricalLoad : 0|16@1+ (0.5,0) [0|32127.5] "kW" Vector__XXX
 SG_ TransGearRatio : 16|16@1+ (0.001,0) [0|64.255] "" Vector__XXX
 SG_ NumberOfForwardGearRatios : 8|8@1+ (1,0) [0|250] "" Vector__XXX
 SG_ NumberOfReverseGearRatios : 0|8@1+ (1,0) [0|250] "" Vector__XXX
 SG_ PercentTorqueAtPeakTorquePoint5 : 144|8@1+ (1,-125) [-125|125] "%" Vector__XXX
 SG_ ReferenceRetarderTorque : 128|16@1+ (1,0) [0|64255] "Nm" Vector__XXX
 SG_ RetarderSpeedAtPeakTorquePoint5 : 112|16@1+ (0.125,0) [0|8031.875] "rpm" Vector__XXX
 SG_ PercentTorqueAtPoint4 : 104|8@1+ (1,-125) [-125|125] "%" Vector__XXX
 SG_ RetarderSpeedAtPoint4 : 88|16@1+ (0.125,0) [0|8031.875] "rpm" Vector__XXX
 SG_ PercentTorqueAtPoint3 : 80|8@1+ (1,-125) [-125|125] "%" Vector__XXX
 SG_ RetarderSpeedAtPoint3 : 64|16@1+ (0.125,0) [0|8031.875] "rpm" Vector__XXX
 SG_ PercentTorqueAtMaxSpeedPoint2 : 56|8@1+ (1,-125) [-125|125] "%" Vector__XXX
 SG_ MaxRetarderSpeedPoint2 : 40|16@1+ (0.125,0) [0|8031.875] "rpm" Vector__XXX
 SG_ PercentTorqueAtIdlePoint1 : 32|8@1+ (1,-125) [-125|125] "%" Vector__XXX
 SG_ RetarderSpeedAtIdlePoint1 : 16|16@1+ (0.125,0) [0|8031.875] "rpm" Vector__XXX
 SG_ RetarderCtrlMethod : 8|8@1+ (1,0) [0|250] "steps" Vector__XXX
 SG_ RetarderLocation : 4|4@1+ (1,0) [0|15] "" Vector__XXX
 SG_ RetarderType : 0|4@1+ (1,0) [0|15] "" Vector__XXX
 SG_ TotalVehicleDistance : 32|32@1+ (0.125,0) [0|526385151.9] "km" Vector__XXX
 SG_ TripDistance : 0|32@1+ (0.125,0) [0|526385151.9] "km" Vector__XXX
 SG_ PowerTakeoffSetSpeed : 24|16@1+ (0.125,0) [0|8031.875] "rpm" Vector__XXX
 SG_ PowerTakeoffSpeed : 8|16@1+ (0.125,0) [0|8031.875] "rpm" Vector__XXX
 SG_ PowerTakeoffOilTemp : 0|8@1+ (1,-40) [-40|210] "deg C" Vector__XXX
 SG_ OprtrEngPTOGvrnrMmrySlectSwitch : 56|2@1+ (1,0) [0|3] "" Vector__XXX
 SG_ EngRmtPTOGvrnrVrblSpdCtrlSwitch : 44|2@1+ (1,0) [0|3] "" Vector__XXX
 SG_ EngRmtPTOGvrnrPrprgrmmdSpdCtrlSw : 42|2@1+ (1,0) [0|3] "" Vector__XXX
 SG_ EngPTOGvrnrCst_DecelerateSwitch : 50|2@1+ (1,0) [0|3] "" Vector__XXX
 SG_ EngPTOGovernorSetSwitch : 48|2@1+ (1,0) [0|3] "" Vector__XXX
 SG_ EngPTOGovernorResumeSwitch : 52|2@1+ (1,0) [0|3] "" Vector__XXX
 SG_ EngPTOGovernorEnableSwitch : 40|2@1+ (1,0) [0|3] "" Vector__XXX
 SG_ EngPTOGovernorAccelerateSwitch : 54|2@1+ (1,0) [0|3] "" Vector__XXX
 SG_ RmtPTOPrprgrmmdSpeedCtrlSwitch2 : 58|2@1+ (1,0) [0|3] "" Vector__XXX
 SG_ AuxInputIgnoreSwitch : 60|2@1+ (1,0) [0|3] "" Vector__XXX
 SG_ EngCoolantLevel : 56|8@1+ (0.4,0) [0|100] "%" Vector__XXX
 SG_ EngCoolantPress : 48|8@1+ (2,0) [0|500] "kPa" Vector__XXX
 SG_ EngCrankcasePress : 32|16@1+ (0.0078125,-250) [-250|251.99] "kPa" Vector__XXX
 SG_ EngOilPress : 24|8@1+ (4,0) [0|1000] "kPa" Vector__XXX
 SG_ EngOilLevel : 16|8@1+ (0.4,0) [0|100] "%" Vector__XXX
 SG_ EngExCrankcaseBlowbyPress : 8|8@1+ (0.05,0) [0|12.5] "kPa" Vector__XXX
 SG_ EngFuelDeliveryPress : 0|8@1+ (4,0) [0|1000] "kPa" Vector__XXX
 SG_ EngFuelTemp1 : 8|8@1+ (1,-40) [-40|210] "deg C" Vector__XXX
 SG_ EngIntercoolerThermostatOpening : 56|8@1+ (0.4,0) [0|100] "%" Vector__XXX
 SG_ EngIntercoolerTemp : 48|8@1+ (1,-40) [-40|210] "deg C" Vector__XXX
 SG_ EngTurboOilTemp : 32|16@1+ (0.03125,-273) [-273|1734.96875] "deg C" Vector__XXX
 SG_ EngOilTemp1 : 16|16@1+ (0.03125,-273) [-273|1734.96875] "deg C" Vector__XXX
 SG_ EngCoolantTemp : 0|8@1+ (0.03125,-273) [-273|-265.03125] "deg C" Vector__XXX
 SG_ CruiseCtrlLowSetLimitSpeed : 16|8@1+ (1,0) [0|250] "km/h" Vector__XXX
 SG_ CruiseCtrlHighSetLimitSpeed : 8|8@1+ (1,0) [0|250] "km/h" Vector__XXX
 SG_ VehicleIdentificationNumber : 0|8@1+ (1,0) [0|255] "" Vector__XXX
 SG_ UnitNumber : 24|8@1+ (1,0) [0|255] "" Vector__XXX
 SG_ SerialNumber : 16|8@1+ (1,0) [0|255] "" Vector__XXX
 SG_ Model : 8|8@1+ (1,0) [0|255] "" Vector__XXX
 SG_ Make : 0|8@1+ (1,0) [0|255] "" Vector__XXX
 SG_ CargoWeight_30 m48 : 40|16@1+ (2,0) [0|128510] "kg" Vector__XXX
 SG_ CargoWeight_20 m32 : 40|16@1+ (2,0) [0|128510] "kg" Vector__XXX
 SG_ CargoWeight_10 m16 : 40|16@1+ (2,0) [0|128510] "kg" Vector__XXX
 SG_ CargoWeight_00 m0 : 40|16@1+ (2,0) [0|128510] "kg" Vector__XXX
 SG_ TrailerWeight_30 m48 : 24|16@1+ (2,0) [0|128510] "kg" Vector__XXX
 SG_ TrailerWeight_20 m32 : 24|16@1+ (2,0) [0|128510] "kg" Vector__XXX
 SG_ TrailerWeight_10 m16 : 24|16@1+ (2,0) [0|128510] "kg" Vector__XXX
 SG_ TrailerWeight_00 m0 : 24|16@1+ (2,0) [0|128510] "kg" Vector__XXX
 SG_ AxleWeight_30 m48 : 8|16@1+ (0.5,0) [0|32127.5] "kg" Vector__XXX
 SG_ AxleWeight_20 m32 : 8|16@1+ (0.5,0) [0|32127.5] "kg" Vector__XXX
 SG_ AxleWeight_10 m16 : 8|16@1+ (0.5,0) [0|32127.5] "kg" Vector__XXX
 SG_ AxleWeight_00 m0 : 8|16@1+ (0.5,0) [0|32127.5] "kg" Vector__XXX
 SG_ EngTotalFuelUsed : 32|32@1+ (0.5,0) [0|2105540607.5] "L" Vector__XXX
 SG_ EngTripFuel : 0|32@1+ (0.5,0) [0|2105540607.5] "L" Vector__XXX
 SG_ Altitude : 48|16@1+ (0.125,-2500) [-2500|5531.875] "m" Vector__XXX
 SG_ Pitch : 32|16@1+ (0.0078125,-200) [-200|301.99] "deg" Vector__XXX
 SG_ NavigationBasedVehicleSpeed : 16|16@1+ (0.00390625,0) [0|250.996] "km/h" Vector__XXX
 SG_ CompassBearing : 0|16@1+ (0.0078125,0) [0|501.99] "deg" Vector__XXX
 SG_ TotalPowerTakeoffHours : 32|32@1+ (0.05,0) [0|210554060.75] "hr" Vector__XXX
 SG_ TotalVehicleHours : 0|32@1+ (0.05,0) [0|210554060.75] "hr" Vector__XXX
 SG_ LocalHourOffset : 56|8@1+ (1,-125) [-125|125] "hr" Vector__XXX
 SG_ LocalMinuteOffset : 48|8@1+ (1,-125) [-125|125] "mins" Vector__XXX
 SG_ Year : 40|8@1+ (1,1985) [1985|2235] "years" Vector__XXX
 SG_ Day : 32|8@1+ (0.25,0) [0|62.5] "days" Vector__XXX
 SG_ Month : 24|8@1+ (1,0) [0|250] "months" Vector__XXX
 SG_ Hours : 16|8@1+ (1,0) [0|250] "hr" Vector__XXX
 SG_ Minutes : 8|8@1+ (1,0) [0|250] "mins" Vector__XXX
 SG_ Seconds : 0|8@1+ (0.25,0) [0|62.5] "s" Vector__XXX
 SG_ EngTotalRevolutions : 32|32@1+ (1000,0) [0|2013264920] "r" Vector__XXX
 SG_ EngTotalHoursOfOperation : 0|32@1+ (0.05,0) [0|210554060.75] "hr" Vector__XXX
 SG_ EngOverspeedTest : 54|2@1+ (1,0) [0|3] "" Vector__XXX
 SG_ EngAirShutoffCmdStatus : 52|2@1+ (1,0) [0|3] "" Vector__XXX
 SG_ EngAlarmOutputCmdStatus : 50|2@1+ (1,0) [0|3] "" Vector__XXX
 SG_ EngAlarmAcknowledge : 48|2@1+ (1,0) [0|3] "" Vector__XXX
 SG_ EngProtectionSystemConfig : 46|2@1+ (1,0) [0|3] "" Vector__XXX
 SG_ EngProtectionSystemTimerState : 38|2@1+ (1,0) [0|3] "" Vector__XXX
 SG_ EngPrtectionSystemTimerOverride : 36|2@1+ (1,0) [0|3] "" Vector__XXX
 SG_ EngPrtctnSystmApprchingShutdown : 34|2@1+ (1,0) [0|3] "" Vector__XXX
 SG_ EngWaitToStartLamp : 24|2@1+ (1,0) [0|3] "" Vector__XXX
 SG_ RefrigerantHighPressSwitch : 20|2@1+ (1,0) [0|3] "" Vector__XXX
 SG_ RefrigerantLowPressSwitch : 18|2@1+ (1,0) [0|3] "" Vector__XXX
 SG_ A_CHighPressFanSwitch : 16|2@1+ (1,0) [0|3] "" Vector__XXX
 SG_ EngIdleShutdownTimerFunction : 14|2@1+ (1,0) [0|3] "" Vector__XXX
 SG_ EngIdleShutdownTimerState : 6|2@1+ (1,0) [0|3] "" Vector__XXX
 SG_ EngIdleShutdownTimerOverride : 4|2@1+ (1,0) [0|3] "" Vector__XXX
 SG_ EngIdleShutdownDriverAlertMode : 2|2@1+ (1,0) [0|3] "" Vector__XXX
 SG_ PTOShutdownHasShutdownEng : 58|2@1+ (1,0) [0|3] "" Vector__XXX
 SG_ EngPrtctnSystmHasShutdownEngine : 32|2@1+ (1,0) [0|3] "" Vector__XXX
 SG_ EngIdlShutdownHasShutdownEngine : 0|2@1+ (1,0) [0|3] "" Vector__XXX
 SG_ EngAirShutoffStatus : 56|2@1+ (1,0) [0|3] "" Vector__XXX
 SG_ EngAirIntakeTemp : 40|8@1+ (1,-40) [-40|210] "deg C" Vector__XXX
 SG_ RoadSurfaceTemp : 48|16@1+ (0.03125,-273) [-273|1734.96875] "deg C" Vector__XXX
 SG_ AmbientAirTemp : 24|16@1+ (0.03125,-273) [-273|1734.96875] "deg C" Vector__XXX
 SG_ CabInteriorTemp : 8|16@1+ (0.03125,-273) [-273|1734.96875] "deg C" Vector__XXX
 SG_ BarometricPress : 0|8@1+ (0.5,0) [0|125] "kPa" Vector__XXX
 SG_ TirePressThresholdDetection_13 m19 : 61|3@1+ (1,0) [0|7] "" Vector__XXX
 SG_ TirePressThresholdDetection_12 m18 : 61|3@1+ (1,0) [0|7] "" Vector__XXX
 SG_ TirePressThresholdDetection_11 m17 : 61|3@1+ (1,0) [0|7] "" Vector__XXX
 SG_ TirePressThresholdDetection_10 m16 : 61|3@1+ (1,0) [0|7] "" Vector__XXX
 SG_ TirePressThresholdDetection_01 m1 : 61|3@1+ (1,0) [0|7] "" Vector__XXX
 SG_ TirePress_33 m51 : 8|8@1+ (4,0) [0|1000] "kPa" Vector__XXX
 SG_ TirePress_32 m50 : 8|8@1+ (4,0) [0|1000] "kPa" Vector__XXX
 SG_ TirePress_31 m49 : 8|8@1+ (4,0) [0|1000] "kPa" Vector__XXX
 SG_ TirePress_30 m48 : 8|8@1+ (4,0) [0|1000] "kPa" Vector__XXX
 SG_ TirePress_23 m35 : 8|8@1+ (4,0) [0|1000] "kPa" Vector__XXX
 SG_ TirePress_22 m34 : 8|8@1+ (4,0) [0|1000] "kPa" Vector__XXX
 SG_ TirePress_21 m33 : 8|8@1+ (4,0) [0|1000] "kPa" Vector__XXX
 SG_ TirePress_20 m32 : 8|8@1+ (4,0) [0|1000] "kPa" Vector__XXX
 SG_ TirePress_13 m19 : 8|8@1+ (4,0) [0|1000] "kPa" Vector__XXX
 SG_ TirePress_12 m18 : 8|8@1+ (4,0) [0|1000] "kPa" Vector__XXX
 SG_ TirePress_11 m17 : 8|8@1+ (4,0) [0|1000] "kPa" Vector__XXX
 SG_ TirePress_10 m16 : 8|8@1+ (4,0) [0|1000] "kPa" Vector__XXX
 SG_ TireAirLeakageRate_33 m51 : 40|16@1+ (0.1,0) [0|6425.5] "Pa/s" Vector__XXX
 SG_ TireAirLeakageRate_32 m50 : 40|16@1+ (0.1,0) [0|6425.5] "Pa/s" Vector__XXX
 SG_ TireAirLeakageRate_31 m49 : 40|16@1+ (0.1,0) [0|6425.5] "Pa/s" Vector__XXX
 SG_ TireAirLeakageRate_30 m48 : 40|16@1+ (0.1,0) [0|6425.5] "Pa/s" Vector__XXX
 SG_ TireAirLeakageRate_23 m35 : 40|16@1+ (0.1,0) [0|6425.5] "Pa/s" Vector__XXX
 SG_ TireAirLeakageRate_22 m34 : 40|16@1+ (0.1,0) [0|6425.5] "Pa/s" Vector__XXX
 SG_ TireAirLeakageRate_21 m33 : 40|16@1+ (0.1,0) [0|6425.5] "Pa/s" Vector__XXX
 SG_ TireAirLeakageRate_20 m32 : 40|16@1+ (0.1,0) [0|6425.5] "Pa/s" Vector__XXX
 SG_ TireAirLeakageRate_13 m19 : 40|16@1+ (0.1,0) [0|6425.5] "Pa/s" Vector__XXX
 SG_ TireAirLeakageRate_12 m18 : 40|16@1+ (0.1,0) [0|6425.5] "Pa/s" Vector__XXX
 SG_ TireAirLeakageRate_11 m17 : 40|16@1+ (0.1,0) [0|6425.5] "Pa/s" Vector__XXX
 SG_ TireAirLeakageRate_10 m16 : 40|16@1+ (0.1,0) [0|6425.5] "Pa/s" Vector__XXX
 SG_ TireAirLeakageRate_01 m1 : 40|16@1+ (0.1,0) [0|6425.5] "Pa/s" Vector__XXX
 SG_ TireAirLeakageRate_00 m0 : 40|16@1+ (0.1,0) [0|6425.5] "Pa/s" Vector__XXX
 SG_ CTIWheelSensorStatus_33 m51 : 32|2@1+ (1,0) [0|3] "" Vector__XXX
 SG_ CTIWheelSensorStatus_32 m50 : 32|2@1+ (1,0) [0|3] "" Vector__XXX
 SG_ CTIWheelSensorStatus_31 m49 : 32|2@1+ (1,0) [0|3] "" Vector__XXX
 SG_ CTIWheelSensorStatus_30 m48 : 32|2@1+ (1,0) [0|3] "" Vector__XXX
 SG_ CTIWheelSensorStatus_23 m35 : 32|2@1+ (1,0) [0|3] "" Vector__XXX
 SG_ CTIWheelSensorStatus_22 m34 : 32|2@1+ (1,0) [0|3] "" Vector__XXX
 SG_ CTIWheelSensorStatus_21 m33 : 32|2@1+ (1,0) [0|3] "" Vector__XXX
 SG_ CTIWheelSensorStatus_20 m32 : 32|2@1+ (1,0) [0|3] "" Vector__XXX
 SG_ CTIWheelSensorStatus_13 m19 : 32|2@1+ (1,0) [0|3] "" Vector__XXX
 SG_ CTIWheelSensorStatus_12 m18 : 32|2@1+ (1,0) [0|3] "" Vector__XXX
 SG_ CTIWheelSensorStatus_11 m17 : 32|2@1+ (1,0) [0|3] "" Vector__XXX
 SG_ CTIWheelSensorStatus_10 m16 : 32|2@1+ (1,0) [0|3] "" Vector__XXX
 SG_ CTIWheelSensorStatus_01 m1 : 32|2@1+ (1,0) [0|3] "" Vector__XXX
 SG_ CTIWheelEndElectricalFault_33 m51 : 36|2@1+ (1,0) [0|3] "" Vector__XXX
 SG_ CTIWheelEndElectricalFault_32 m50 : 36|2@1+ (1,0) [0|3] "" Vector__XXX
 SG_ CTIWheelEndElectricalFault_31 m49 : 36|2@1+ (1,0) [0|3] "" Vector__XXX
 SG_ CTIWheelEndElectricalFault_30 m48 : 36|2@1+ (1,0) [0|3] "" Vector__XXX
 SG_ CTIWheelEndElectricalFault_23 m35 : 36|2@1+ (1,0) [0|3] "" Vector__XXX
 SG_ CTIWheelEndElectricalFault_22 m34 : 36|2@1+ (1,0) [0|3] "" Vector__XXX
 SG_ CTIWheelEndElectricalFault_21 m33 : 36|2@1+ (1,0) [0|3] "" Vector__XXX
 SG_ CTIWheelEndElectricalFault_20 m32 : 36|2@1+ (1,0) [0|3] "" Vector__XXX
 SG_ CTIWheelEndElectricalFault_13 m19 : 36|2@1+ (1,0) [0|3] "" Vector__XXX
 SG_ CTIWheelEndElectricalFault_12 m18 : 36|2@1+ (1,0) [0|3] "" Vector__XXX
 SG_ CTIWheelEndElectricalFault_11 m17 : 36|2@1+ (1,0) [0|3] "" Vector__XXX
 SG_ CTIWheelEndElectricalFault_10 m16 : 36|2@1+ (1,0) [0|3] "" Vector__XXX
 SG_ CTIWheelEndElectricalFault_01 m1 : 36|2@1+ (1,0) [0|3] "" Vector__XXX
 SG_ CTITireStatus_33 m51 : 34|2@1+ (1,0) [0|3] "" Vector__XXX
 SG_ CTITireStatus_32 m50 : 34|2@1+ (1,0) [0|3] "" Vector__XXX
 SG_ CTITireStatus_31 m49 : 34|2@1+ (1,0) [0|3] "" Vector__XXX
 SG_ CTITireStatus_30 m48 : 34|2@1+ (1,0) [0|3] "" Vector__XXX
 SG_ CTITireStatus_23 m35 : 34|2@1+ (1,0) [0|3] "" Vector__XXX
 SG_ CTITireStatus_22 m34 : 34|2@1+ (1,0) [0|3] "" Vector__XXX
 SG_ CTITireStatus_21 m33 : 34|2@1+ (1,0) [0|3] "" Vector__XXX
 SG_ CTITireStatus_20 m32 : 34|2@1+ (1,0) [0|3] "" Vector__XXX
 SG_ CTITireStatus_13 m19 : 34|2@1+ (1,0) [0|3] "" Vector__XXX
 SG_ CTITireStatus_12 m18 : 34|2@1+ (1,0) [0|3] "" Vector__XXX
 SG_ CTITireStatus_11 m17 : 34|2@1+ (1,0) [0|3] "" Vector__XXX
 SG_ CTITireStatus_10 m16 : 34|2@1+ (1,0) [0|3] "" Vector__XXX
 SG_ CTITireStatus_01 m1 : 34|2@1+ (1,0) [0|3] "" Vector__XXX
 SG_ TireTemp_11 m17 : 16|16@1+ (0.03125,-273) [-273|1735] "°C" Vector__XXX
 SG_ TireTemp_33 m51 : 16|16@1+ (0.03125,-273) [-273|1735] "°C" Vector__XXX
 SG_ TireTemp_32 m50 : 16|16@1+ (0.03125,-273) [-273|1735] "°C" Vector__XXX
 SG_ TireTemp_31 m49 : 16|16@1+ (0.03125,-273) [-273|1735] "°C" Vector__XXX
 SG_ TireTemp_30 m48 : 16|16@1+ (0.03125,-273) [-273|1735] "°C" Vector__XXX
 SG_ TireTemp_23 m35 : 16|16@1+ (0.03125,-273) [-273|1735] "°C" Vector__XXX
 SG_ TireTemp_22 m34 : 16|16@1+ (0.03125,-273) [-273|1735] "°C" Vector__XXX
 SG_ TireTemp_21 m33 : 16|16@1+ (0.03125,-273) [-273|1735] "°C" Vector__XXX
 SG_ TireTemp_20 m32 : 16|16@1+ (0.03125,-273) [-273|1735] "°C" Vector__XXX
 SG_ TireTemp_13 m19 : 16|16@1+ (0.03125,-273) [-273|1735] "°C" Vector__XXX
 SG_ TireTemp_12 m18 : 16|16@1+ (0.03125,-273) [-273|1735] "°C" Vector__XXX
 SG_ TireTemp_10 m16 : 16|16@1+ (0.03125,-273) [-273|1735] "°C" Vector__XXX
 SG_ TireTemp_01 m1 : 16|16@1+ (0.03125,-273) [-273|1735] "°C" Vector__XXX
 SG_ TireTemp_00 m0 : 16|16@1+ (0.03125,-273) [-273|1735] "°C" Vector__XXX
 SG_ TirePressThresholdDetection_33 m51 : 61|3@1+ (1,0) [0|7] "" Vector__XXX
 SG_ TirePressThresholdDetection_32 m50 : 61|3@1+ (1,0) [0|7] "" Vector__XXX
 SG_ TirePressThresholdDetection_31 m49 : 61|3@1+ (1,0) [0|7] "" Vector__XXX
 SG_ TirePressThresholdDetection_30 m48 : 61|3@1+ (1,0) [0|7] "" Vector__XXX
 SG_ TirePressThresholdDetection_23 m35 : 61|3@1+ (1,0) [0|7] "" Vector__XXX
 SG_ TirePressThresholdDetection_22 m34 : 61|3@1+ (1,0) [0|7] "" Vector__XXX
 SG_ TirePressThresholdDetection_21 m33 : 61|3@1+ (1,0) [0|7] "" Vector__XXX
 SG_ TirePressThresholdDetection_20 m32 : 61|3@1+ (1,0) [0|7] "" Vector__XXX
 SG_ TirePressThresholdDetection_00 m0 : 61|3@1+ (1,0) [0|7] "" Vector__XXX
 SG_ TirePress_01 m1 : 8|8@1+ (4,0) [0|1000] "kPa" Vector__XXX
 SG_ TirePress_00 m0 : 8|8@1+ (4,0) [0|1000] "kPa" Vector__XXX
 SG_ CTIWheelSensorStatus_00 m0 : 32|2@1+ (1,0) [0|3] "" Vector__XXX
 SG_ CTIWheelEndElectricalFault_00 m0 : 36|2@1+ (1,0) [0|3] "" Vector__XXX
 SG_ CTITireStatus_00 m0 : 34|2@1+ (1,0) [0|3] "" Vector__XXX
 SG_ Longitude : 32|32@1+ (10,-210) [-210|211.1008122] "deg" Vector__XXX
 SG_ Latitude : 0|32@1+ (10,-210) [-210|211.1008122] "deg" Vector__XXX
 SG_ WaterInFuelIndicator : 0|2@1+ (1,0) [0|3] "" Vector__XXX
 SG_ AuxPumpPress : 0|8@1+ (16,0) [0|4000] "kPa" Vector__XXX
 SG_ EngBlowerBypassValvePos : 0|8@1+ (0.4,0) [0|100] "%" Vector__XXX
 SG_ EngGasSupplyPress : 8|16@1+ (0.5,0) [0|32127.5] "kPa" Vector__XXX
 SG_ FuelLevel2 : 48|8@1+ (0.4,0) [0|100] "%" Vector__XXX
 SG_ FuelLevel1 : 8|8@1+ (0.4,0) [0|100] "%" Vector__XXX
 SG_ CargoAmbientTemp : 32|16@1+ (0.03125,-273) [-273|1734.96875] "deg C" Vector__XXX
 SG_ EngOilFilterDiffPress : 24|8@1+ (0.5,0) [0|125] "kPa" Vector__XXX
 SG_ WasherFluidLevel : 0|8@1+ (0.4,0) [0|100] "%" Vector__XXX
 SG_ DrvlneRetarderOverheatIndicator : 16|2@1+ (1,0) [0|3] "" Vector__XXX
 SG_ HydRetarderOilTemp : 8|8@1+ (1,-40) [-40|210] "deg C" Vector__XXX
 SG_ HydRetarderPress : 0|8@1+ (16,0) [0|4000] "kPa" Vector__XXX
 SG_ ParkingBrakeRedWarningSignal : 26|2@1+ (1,0) [0|3] "" Vector__XXX
 SG_ ParkBrakeReleaseInhibitStatus : 28|2@1+ (1,0) [0|3] "" Vector__XXX
 SG_ ParkingBrakeActuator : 24|2@1+ (1,0) [0|3] "" Vector__XXX
 SG_ BrakeSecondPress : 16|8@1+ (4,0) [0|1000] "kPa" Vector__XXX
 SG_ BrakePrimaryPress : 8|8@1+ (4,0) [0|1000] "kPa" Vector__XXX
 SG_ BrakeAppPress : 0|8@1+ (4,0) [0|1000] "kPa" Vector__XXX
 SG_ SteerAxleLubePress : 56|8@1+ (4,0) [0|1000] "kPa" Vector__XXX
 SG_ SteerAxleTemp : 0|8@1+ (1,-40) [-40|210] "deg C" Vector__XXX
 SG_ DriveAxleLubePress : 32|8@1+ (4,0) [0|1000] "kPa" Vector__XXX
 SG_ DriveAxleTemp : 24|8@1+ (1,-40) [-40|210] "deg C" Vector__XXX
 SG_ DriveAxleLiftAirPress : 16|8@1+ (4,0) [0|1000] "kPa" Vector__XXX
 SG_ DriveAxleLocation : 8|8@1+ (1,0) [0|255] "" Vector__XXX
 SG_ TransOilLevelMeasurementStatus : 60|4@1+ (1,0) [0|15] "" Vector__XXX
 SG_ TransOilLevelCountdownTimer : 56|4@1+ (1,0) [0|15] "" Vector__XXX
 SG_ TransOilLevelHigh_Low : 48|8@1+ (0.5,-62.5) [-62.5|62.5] "L" Vector__XXX
 SG_ TransOilTemp : 32|16@1+ (0.03125,-273) [-273|1734.96875] "deg C" Vector__XXX
 SG_ TransOilPress : 24|8@1+ (16,0) [0|4000] "kPa" Vector__XXX
 SG_ TransFilterDiffPress : 16|8@1+ (2,0) [0|500] "kPa" Vector__XXX
 SG_ TransOilLevel : 8|8@1+ (0.4,0) [0|100] "%" Vector__XXX
 SG_ ClutchPress : 0|8@1+ (16,0) [0|4000] "kPa" Vector__XXX
 SG_ ChargingSystemPotential : 16|16@1+ (0.05,0) [0|3212.75] "V" Vector__XXX
 SG_ AltCurrent : 8|8@1+ (1,0) [0|250] "A" Vector__XXX
 SG_ NetBatteryCurrent : 0|8@1+ (1,-125) [-125|125] "A" Vector__XXX
 SG_ KeyswitchBatteryPotential : 48|16@1+ (0.05,0) [0|3212.75] "V" Vector__XXX
 SG_ BatteryPotential_PowerInput1 : 32|16@1+ (0.05,0) [0|3212.75] "V" Vector__XXX

BO_ 2566749438 DPFC1: 8 Vector__XXX
 SG_ DslPrtcltFltrActvRgnrtnFrcdStts : 53|3@1+ (1,0) [0|7] "" Vector__XXX
 SG_ ExhaustSystemHighTempLampCmd : 50|3@1+ (1,0) [0|7] "" Vector__XXX
 SG_ DslPrtcltFltrAtmtcActvRgnrtnIntt : 48|2@1+ (1,0) [0|3] "" Vector__XXX
 SG_ DslPrtcltFltrActvRgnrtnInhbtdDTV : 46|2@1+ (1,0) [0|3] "" Vector__XXX
 SG_ DslPrtcltFltrActvRgnrtnInhbtdDTE : 44|2@1+ (1,0) [0|3] "" Vector__XXX
 SG_ DslPrtcltFltrActvRgnrtnInhbtdDTP : 42|2@1+ (1,0) [0|3] "" Vector__XXX
 SG_ DslPrtcltFltrActvRgnrtnInhbtdDTT : 40|2@1+ (1,0) [0|3] "" Vector__XXX
 SG_ DslPrtcltFltrActvRgnrtnInhbtdDTS : 38|2@1+ (1,0) [0|3] "" Vector__XXX
 SG_ DslPrtcltFltrActvRgnrtnInhb_0000 : 36|2@1+ (1,0) [0|3] "" Vector__XXX
 SG_ DslPrtcltFltrActvRgnrtnInhbtdDTL : 34|2@1+ (1,0) [0|3] "" Vector__XXX
 SG_ DslPrtcltFltrActvRgnrtnInhb_0001 : 32|2@1+ (1,0) [0|3] "" Vector__XXX
 SG_ DslPrtcltFltrActvRgnrtnInhb_0002 : 30|2@1+ (1,0) [0|3] "" Vector__XXX
 SG_ DslPrtcltFltrActvRgnrtnInhbtdDTO : 28|2@1+ (1,0) [0|3] "" Vector__XXX
 SG_ DslPrtcltFltrActvRgnrtnInhbtdDTA : 26|2@1+ (1,0) [0|3] "" Vector__XXX
 SG_ DslPrtcltFltrActvRgnrtnInhb_0003 : 24|2@1+ (1,0) [0|3] "" Vector__XXX
 SG_ DslPrtcltFltrActvRgnrtnInhb_0004 : 22|2@1+ (1,0) [0|3] "" Vector__XXX
 SG_ DslPrtcltFltrActvRgnrtnInhbtdDTC : 20|2@1+ (1,0) [0|3] "" Vector__XXX
 SG_ DslPrtcltFltrActvRgnrtnInhbtdDTI : 18|2@1+ (1,0) [0|3] "" Vector__XXX
 SG_ DslPrtcltFltrActvRgnrtnInhbtdStt : 16|2@1+ (1,0) [0|3] "" Vector__XXX
 SG_ DieselParticulateFilterStatus : 12|3@1+ (1,0) [0|7] "" Vector__XXX
 SG_ DslPrtcltFltrActvRgnrtionStatus : 10|2@1+ (1,0) [0|3] "" Vector__XXX
 SG_ DslPrtcltFltrPssvRgnrtionStatus : 8|2@1+ (1,0) [0|3] "" Vector__XXX
 SG_ DieselParticulateFilterLampCmd : 0|3@1+ (1,0) [0|7] "" Vector__XXX

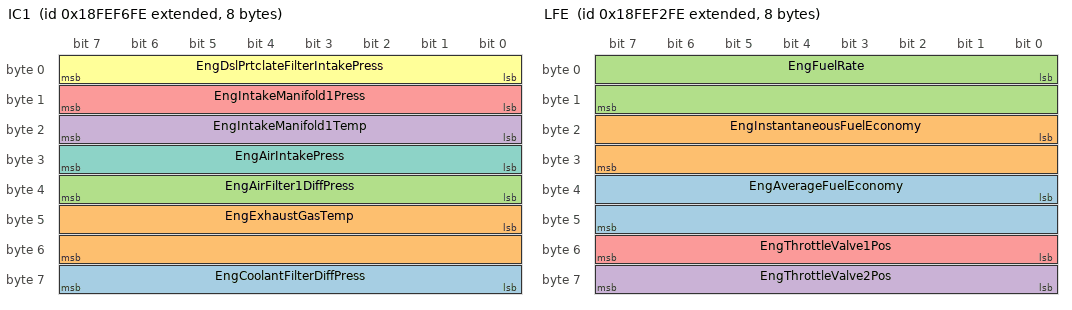
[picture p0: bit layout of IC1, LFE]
BO_ 2566846206 IC1: 8 Vector__XXX
 SG_ EngCoolantFilterDiffPress : 56|8@1+ (0.5,0) [0|125] "kPa" Vector__XXX
 SG_ EngExhaustGasTemp : 40|16@1+ (0.03125,-273) [-273|1734.96875] "deg C" Vector__XXX
 SG_ EngAirFilter1DiffPress : 32|8@1+ (0.05,0) [0|12.5] "kPa" Vector__XXX
 SG_ EngIntakeManifold1Temp : 16|8@1+ (1,-40) [-40|210] "deg C" Vector__XXX
 SG_ EngIntakeManifold1Press : 8|8@1+ (2,0) [0|500] "kPa" Vector__XXX
 SG_ EngDslPrtclateFilterIntakePress : 0|8@1+ (0.5,0) [0|125] "kPa" Vector__XXX
 SG_ EngAirIntakePress : 24|8@1+ (2,0) [0|500] "kPa" Vector__XXX

BO_ 2566845182 LFE: 8 Vector__XXX
 SG_ EngAverageFuelEconomy : 32|16@1+ (0.001953125,0) [0|125.5] "km/L" Vector__XXX
 SG_ EngInstantaneousFuelEconomy : 16|16@1+ (0.001953125,0) [0|125.5] "km/L" Vector__XXX
 SG_ EngFuelRate : 0|16@1+ (0.05,0) [0|3212.75] "L/h" Vector__XXX
 SG_ EngThrottleValve2Pos : 56|8@1+ (0.4,0) [0|100] "%" Vector__XXX
 SG_ EngThrottleValve1Pos : 48|8@1+ (0.4,0) [0|100] "%" Vector__XXX

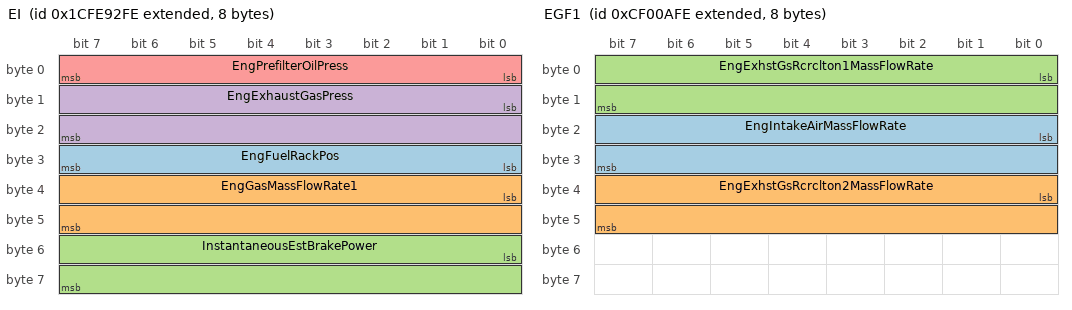
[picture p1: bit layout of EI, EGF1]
BO_ 2633929470 EI: 8 Vector__XXX
 SG_ EngFuelRackPos : 24|8@1+ (0.4,0) [0|100] "%" Vector__XXX
 SG_ EngGasMassFlowRate1 : 32|16@1+ (0.05,0) [0|3212.75] "kg/h" Vector__XXX
 SG_ InstantaneousEstBrakePower : 48|16@1+ (0.5,0) [0|32127.5] "kW" Vector__XXX
 SG_ EngExhaustGasPress : 8|16@1+ (0.0078125,-250) [-250|251.99] "kPa" Vector__XXX
 SG_ EngPrefilterOilPress : 0|8@1+ (4,0) [0|1000] "kPa" Vector__XXX

BO_ 2364541694 EGF1: 8 Vector__XXX
 SG_ EngIntakeAirMassFlowRate : 16|16@1+ (0.05,0) [0|3212.75] "kg/h" Vector__XXX
 SG_ EngExhstGsRcrclton2MassFlowRate : 32|16@1+ (0.05,0) [0|3212.75] "kg/h" Vector__XXX
 SG_ EngExhstGsRcrclton1MassFlowRate : 0|16@1+ (0.05,0) [0|3212.75] "kg/h" Vector__XXX

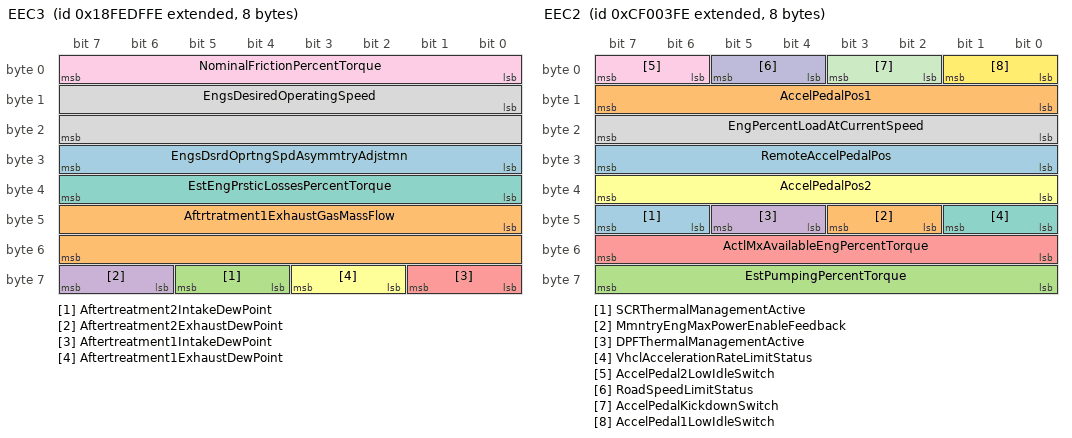
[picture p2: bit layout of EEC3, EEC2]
BO_ 2566840318 EEC3: 8 Vector__XXX
 SG_ EngsDsrdOprtngSpdAsymmtryAdjstmn : 24|8@1+ (1,0) [0|250] "" Vector__XXX
 SG_ Aftrtratment1ExhaustGasMassFlow : 40|16@1+ (0.2,0) [0|12851] "kg/h" Vector__XXX
 SG_ Aftertreatment2IntakeDewPoint : 60|2@1+ (1,0) [0|3] "" Vector__XXX
 SG_ Aftertreatment2ExhaustDewPoint : 62|2@1+ (1,0) [0|3] "" Vector__XXX
 SG_ Aftertreatment1IntakeDewPoint : 56|2@1+ (1,0) [0|3] "" Vector__XXX
 SG_ Aftertreatment1ExhaustDewPoint : 58|2@1+ (1,0) [0|3] "" Vector__XXX
 SG_ EstEngPrsticLossesPercentTorque : 32|8@1+ (1,-125) [-125|125] "%" Vector__XXX
 SG_ EngsDesiredOperatingSpeed : 8|16@1+ (0.125,0) [0|8031.875] "rpm" Vector__XXX
 SG_ NominalFrictionPercentTorque : 0|8@1+ (1,-125) [-125|125] "%" Vector__XXX

BO_ 2364539902 EEC2: 8 Vector__XXX
 SG_ SCRThermalManagementActive : 46|2@1+ (1,0) [0|3] "" Vector__XXX
 SG_ MmntryEngMaxPowerEnableFeedback : 42|2@1+ (1,0) [0|3] "" Vector__XXX
 SG_ EstPumpingPercentTorque : 56|8@1+ (1,-125) [-125|125] "%" Vector__XXX
 SG_ DPFThermalManagementActive : 44|2@1+ (1,0) [0|3] "" Vector__XXX
 SG_ ActlMxAvailableEngPercentTorque : 48|8@1+ (0.4,0) [0|100] "%" Vector__XXX
 SG_ AccelPedalPos2 : 32|8@1+ (0.4,0) [0|100] "%" Vector__XXX
 SG_ VhclAccelerationRateLimitStatus : 40|2@1+ (1,0) [0|3] "" Vector__XXX
 SG_ EngPercentLoadAtCurrentSpeed : 16|8@1+ (1,0) [0|250] "%" Vector__XXX
 SG_ AccelPedal2LowIdleSwitch : 6|2@1+ (1,0) [0|3] "" Vector__XXX
 SG_ RoadSpeedLimitStatus : 4|2@1+ (1,0) [0|3] "" Vector__XXX
 SG_ AccelPedalKickdownSwitch : 2|2@1+ (1,0) [0|3] "" Vector__XXX
 SG_ AccelPedal1LowIdleSwitch : 0|2@1+ (1,0) [0|3] "" Vector__XXX
 SG_ RemoteAccelPedalPos : 24|8@1+ (0.4,0) [0|100] "%" Vector__XXX
 SG_ AccelPedalPos1 : 8|8@1+ (0.4,0) [0|100] "%" Vector__XXX

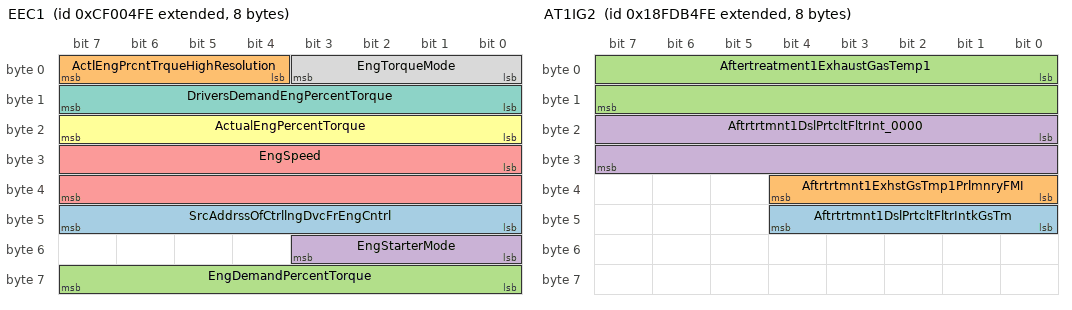
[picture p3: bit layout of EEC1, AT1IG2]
BO_ 2364540158 EEC1: 8 Vector__XXX
 SG_ SrcAddrssOfCtrllngDvcFrEngCntrl : 40|8@1+ (1,0) [0|255] "" Vector__XXX
 SG_ ActlEngPrcntTrqueHighResolution : 4|4@1+ (0.125,0) [0|0.875] "%" Vector__XXX
 SG_ EngDemandPercentTorque : 56|8@1+ (1,-125) [-125|125] "%" Vector__XXX
 SG_ EngStarterMode : 48|4@1+ (1,0) [0|15] "" Vector__XXX
 SG_ EngSpeed : 24|16@1+ (0.125,0) [0|8031.875] "rpm" Vector__XXX
 SG_ ActualEngPercentTorque : 16|8@1+ (1,-125) [-125|125] "%" Vector__XXX
 SG_ DriversDemandEngPercentTorque : 8|8@1+ (1,-125) [-125|125] "%" Vector__XXX
 SG_ EngTorqueMode : 0|4@1+ (1,0) [0|15] "" Vector__XXX

BO_ 2566841342 EC1: 39 Vector__XXX
 SG_ SupportTSC1CtrlPurposeGroup4 : 304|8@1+ (1,0) [0|255] "" Vector__XXX
 SG_ SupportTSC1CtrlPurposeGroup3 : 296|8@1+ (1,0) [0|255] "" Vector__XXX
 SG_ SupportTSC1CtrlPurposeGroup2 : 288|8@1+ (1,0) [0|255] "" Vector__XXX
 SG_ SupportTSC1CtrlPurposeGroup1 : 280|8@1+ (1,0) [0|255] "" Vector__XXX
 SG_ SupportVariableRateTSC1Message : 272|8@1+ (1,0) [0|255] "" Vector__XXX
 SG_ EngDefaultTorqueLimit : 256|16@1+ (1,0) [0|64255] "Nm" Vector__XXX
 SG_ EngMomentOfInertia : 240|16@1+ (0.004,0) [0|257.02] "kg-m²" Vector__XXX
 SG_ EngExRngRqdSpdCtrlRngUpperLimit : 224|16@1+ (0.125,0) [0|8031.875] "rpm" Vector__XXX
 SG_ EngRqdTorqueCtrlRangeUpperLimit : 216|8@1+ (1,-125) [-125|125] "%" Vector__XXX
 SG_ EngRqdTorqueCtrlRangeLowerLimit : 208|8@1+ (1,-125) [-125|125] "%" Vector__XXX
 SG_ EngRqedSpeedCtrlRangeUpperLimit : 200|8@1+ (10,0) [0|2500] "rpm" Vector__XXX
 SG_ EngRqedSpeedCtrlRangeLowerLimit : 192|8@1+ (10,0) [0|2500] "rpm" Vector__XXX
 SG_ EngMxMomentaryOverrideTimeLimit : 184|8@1+ (0.1,0) [0|25] "s" Vector__XXX
 SG_ EngMxMmntaryOverrideSpeedPoint7 : 168|16@1+ (0.125,0) [0|8031.875] "rpm" Vector__XXX
 SG_ EngReferenceTorque : 152|16@1+ (1,0) [0|64255] "Nm" Vector__XXX
 SG_ EngSpeedAtHighIdlePoint6 : 120|16@1+ (0.125,0) [0|8031.875] "rpm" Vector__XXX
 SG_ EngGainOfEndspeedGovernor : 136|16@1+ (0.00078125,0) [0|50.2] "%/rpm" Vector__XXX
 SG_ EngPercentTorqueAtPoint5 : 112|8@1+ (1,-125) [-125|125] "%" Vector__XXX
 SG_ EngSpeedAtPoint5 : 96|16@1+ (0.125,0) [0|8031.875] "rpm" Vector__XXX
 SG_ EngPercentTorqueAtPoint4 : 88|8@1+ (1,-125) [-125|125] "%" Vector__XXX
 SG_ EngSpeedAtPoint4 : 72|16@1+ (0.125,0) [0|8031.875] "rpm" Vector__XXX
 SG_ EngPercentTorqueAtPoint3 : 64|8@1+ (1,-125) [-125|125] "%" Vector__XXX
 SG_ EngSpeedAtPoint3 : 48|16@1+ (0.125,0) [0|8031.875] "rpm" Vector__XXX
 SG_ EngPercentTorqueAtPoint2 : 40|8@1+ (1,-125) [-125|125] "%" Vector__XXX
 SG_ EngSpeedAtPoint2 : 24|16@1+ (0.125,0) [0|8031.875] "rpm" Vector__XXX
 SG_ EngPercentTorqueAtIdlePoint1 : 16|8@1+ (1,-125) [-125|125] "%" Vector__XXX
 SG_ EngSpeedAtIdlePoint1 : 0|16@1+ (0.125,0) [0|8031.875] "rpm" Vector__XXX

BO_ 2566844926 CCVS: 8 Vector__XXX
 SG_ ParkBrakeReleaseInhibitRq : 6|2@1+ (1,0) [0|3] "" Vector__XXX
 SG_ PTOGovernorState : 48|5@1+ (1,0) [0|31] "" Vector__XXX
 SG_ EngShutdownOverrideSwitch : 62|2@1+ (1,0) [0|3] "" Vector__XXX
 SG_ EngTestModeSwitch : 60|2@1+ (1,0) [0|3] "" Vector__XXX
 SG_ EngIdleDecrementSwitch : 58|2@1+ (1,0) [0|3] "" Vector__XXX
 SG_ EngIdleIncrementSwitch : 56|2@1+ (1,0) [0|3] "" Vector__XXX
 SG_ CruiseCtrlStates : 53|3@1+ (1,0) [0|7] "" Vector__XXX
 SG_ CruiseCtrlSetSpeed : 40|8@1+ (1,0) [0|250] "km/h" Vector__XXX
 SG_ CruiseCtrlAccelerateSwitch : 38|2@1+ (1,0) [0|3] "" Vector__XXX
 SG_ CruiseCtrlResumeSwitch : 36|2@1+ (1,0) [0|3] "" Vector__XXX
 SG_ CruiseCtrlCoastSwitch : 34|2@1+ (1,0) [0|3] "" Vector__XXX
 SG_ CruiseCtrlSetSwitch : 32|2@1+ (1,0) [0|3] "" Vector__XXX
 SG_ ClutchSwitch : 30|2@1+ (1,0) [0|3] "" Vector__XXX
 SG_ BrakeSwitch : 28|2@1+ (1,0) [0|3] "" Vector__XXX
 SG_ CruiseCtrlEnableSwitch : 26|2@1+ (1,0) [0|3] "" Vector__XXX
 SG_ CruiseCtrlActive : 24|2@1+ (1,0) [0|3] "" Vector__XXX
 SG_ WheelBasedVehicleSpeed : 8|16@1+ (0.00390625,0) [0|250.996] "km/h" Vector__XXX
 SG_ CruiseCtrlPauseSwitch : 4|2@1+ (1,0) [0|3] "" Vector__XXX
 SG_ ParkingBrakeSwitch : 2|2@1+ (1,0) [0|3] "" Vector__XXX
 SG_ TwoSpeedAxleSwitch : 0|2@1+ (1,0) [0|3] "" Vector__XXX

BO_ 2566763774 AT1IG2: 8 Vector__XXX
 SG_ Aftrtrtmnt1DslPrtcltFltrIntkGsTm : 40|5@1+ (1,0) [0|31] "" Vector__XXX
 SG_ Aftrtrtmnt1ExhstGsTmp1PrlmnryFMI : 32|5@1+ (1,0) [0|31] "" Vector__XXX
 SG_ Aftertreatment1ExhaustGasTemp1 : 0|16@1+ (0.03125,-273) [-273|1734.96875] "deg C" Vector__XXX
 SG_ Aftrtrtmnt1DslPrtcltFltrInt_0000 : 16|16@1+ (0.03125,-273) [-273|1734.96875] "deg C" Vector__XXX

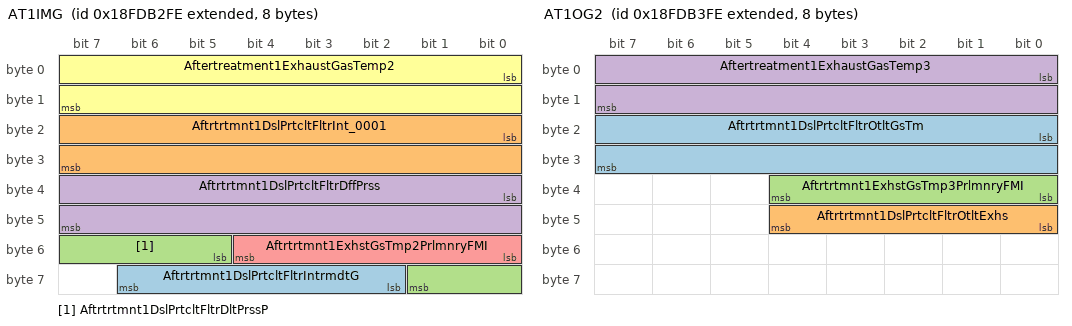
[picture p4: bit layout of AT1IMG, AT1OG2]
BO_ 2566763262 AT1IMG: 8 Vector__XXX
 SG_ Aftrtrtmnt1DslPrtcltFltrIntrmdtG : 58|5@1+ (1,0) [0|31] "" Vector__XXX
 SG_ Aftrtrtmnt1DslPrtcltFltrInt_0001 : 16|16@1+ (0.03125,-273) [-273|1734.96875] "deg C" Vector__XXX
 SG_ Aftrtrtmnt1DslPrtcltFltrDltPrssP : 53|5@1+ (1,0) [0|31] "" Vector__XXX
 SG_ Aftrtrtmnt1DslPrtcltFltrDffPrss : 32|16@1+ (0.1,0) [0|6425.5] "kPa" Vector__XXX
 SG_ Aftrtrtmnt1ExhstGsTmp2PrlmnryFMI : 48|5@1+ (1,0) [0|31] "" Vector__XXX
 SG_ Aftertreatment1ExhaustGasTemp2 : 0|16@1+ (0.03125,-273) [-273|1734.96875] "deg C" Vector__XXX

BO_ 2566763518 AT1OG2: 8 Vector__XXX
 SG_ Aftrtrtmnt1DslPrtcltFltrOtltGsTm : 16|16@1+ (0.03125,-273) [-273|1734.96875] "deg C" Vector__XXX
 SG_ Aftrtrtmnt1DslPrtcltFltrOtltExhs : 40|5@1+ (1,0) [0|31] "" Vector__XXX
 SG_ Aftrtrtmnt1ExhstGsTmp3PrlmnryFMI : 32|5@1+ (1,0) [0|31] "" Vector__XXX
 SG_ Aftertreatment1ExhaustGasTemp3 : 0|16@1+ (0.03125,-273) [-273|1734.96875] "deg C" Vector__XXX

BO_ 256 TMPBB1: 8 Vector__XXX
 SG_ Themocouple1Temperature : 23|16@0+ (0.01,0) [0|0] "C" Vector__XXX
 SG_ Themocouple2Temperature : 55|16@0+ (0.01,0) [0|0] "C" Vector__XXX

CM_ SG_ 3221225472 EngIntakeManifold2Press "The gage pressure measurement of the air intake manifold for bank #2 or the second air intake manifold.";
CM_ SG_ 3221225472 EngIntakeManifold1AbsPressHiRes "The absolute pressure measurement of the air intake manifold.The absolute pressure measurement of the air intake manifold.";
CM_ SG_ 3221225472 RearWasherFunction "State of operation selected by operator switch for the rear washer.";
CM_ SG_ 3221225472 FrontOperatorWasherSwitch "State of operation selected by operator switch for the washer in front of the operator position.";
CM_ SG_ 3221225472 FrontNonoperatorWasherSwitch "State of operation selected by operator switch for the front washer not in front of the operator position.";
CM_ SG_ 3221225472 RearWiperDelayCtrl "Time between cycles of the rear wiper (i.";
CM_ SG_ 3221225472 FrontNonoperatorWiperDelayCtrl "Time between cycles of the front non-operator side wiper (i.";
CM_ SG_ 3221225472 FrontOperatorWiperDelayCtrl "Time between cycles of the front operator side wiper (i.";
CM_ SG_ 3221225472 RearWiperSwitch "State of operation selected by operator switch for the rear wiper.";
CM_ SG_ 3221225472 FrontOperatorWiperSwitch "State of operation selected by operator switch for the Wiper in front of the operator position.";
CM_ SG_ 3221225472 FrontNonoperatorWiperSwitch "State of operation selected by operator switch for the front wiper not in front of the operator position.";
CM_ SG_ 3221225472 OprtrsDesiredDelayedLampOffTime "A 16 bit parameter to be associated with Delayed Off position (1000 binary) of the Main Light Switch.";
CM_ SG_ 3221225472 OperatorsDesiredBacklight "A 8 bit parameter to indicate the level of back lighting the operator has selected for displays.";
CM_ SG_ 3221225472 HighLowBeamSwitch "A 2 bit parameter to indicate the selected position of the operator's high/low beam select switch.";
CM_ SG_ 3221225472 HazardLightSwitch "A 2 bit parameter to indicate the selected position of the operator's hazard light switch.";
CM_ SG_ 3221225472 TurnSignalSwitch "A 4 bit parameter to indicate the selected position of the operator's turn signal switch.";
CM_ SG_ 3221225472 MainLightSwitch "A 4 bit parameter to indicate the selected position of the operator's main light switch.";
CM_ SG_ 3221225472 WorkLightSwitch "A 4 bit parameter to indicate the selected position of the operator's work light switch.";
CM_ SG_ 3221225472 EngAltDroopAuxInputSelect "In some off-highway applications it may be desirable to have multiple droop settings available across the range of engine";
CM_ SG_ 3221225472 EngAltDroopRemoteAccelSelect "In some off-highway applications it may be desirable to have multiple droop settings available across the range of engine";
CM_ SG_ 3221225472 EngAltDroopAccel2Select "Same description as Engine Alternate Droop Accelerator 1 Select (SPN 2881) except that the selections may apply to";
CM_ SG_ 3221225472 EngAltDroopAccel1Select "In some off-highway applications it may be desirable to have multiple droop settings available across the range of engine";
CM_ SG_ 3221225472 EngAltRatingSelect "In some off-highway applications it may be desirable to have multiple engine ratings available for selection by the operator.";
CM_ SG_ 3221225472 EngAltLowIdleSwitch "Operator switch which selects between two low idle speeds, default and alternate.";
CM_ SG_ 3221225472 EngSynchronizationSwitch "This is the On/Off operation of the Multiple Unit Synchronization functionality.";
CM_ SG_ 3221225472 EngAuxGovernorSwitch "This is the On/Off operation of the Auxiliary Governor feature switch.";
CM_ SG_ 3221225472 EngOprtrPrmryIntrmdtSpeedSelect "Allows the operator to select one of 13 preprogrammed Intermediate Speed Control settings.";
CM_ SG_ 3221225472 TotalCountOfConfigChangesMade "Total number of times changes have been made to any of the configurable parameters.";
CM_ SG_ 3221225472 EngOprtrPrmryIntrmdtSpdSlctStte "13 preprogrammed intermediate speed control settings are available for the controlling ECM to select.";
CM_ SG_ 3221225472 EngAltDroopAuxInputSelectState "In some off-highway applications it may be desirable to have multiple droop settings available across the range of engine";
CM_ SG_ 3221225472 EngAltDrpRemoteAccelSelectState "In some off-highway applications it may be desirable to have multiple droop settings available across the range of engine";
CM_ SG_ 3221225472 EngAltDroopAccel2SelectState "In some off-highway applications it may be desirable to have multiple droop settings available across the range of engine";
CM_ SG_ 3221225472 EngAltDroopAccel1SelectState "In some off-highway applications it may be desirable to have multiple droop settings available across the range of engine";
CM_ SG_ 3221225472 EngAltRatingSelectState "In some off-highway applications it may be desirable to have multiple engine ratings available for selection by the operator.";
CM_ SG_ 3221225472 EngAltLowIdleSelectState "In many applications, it is desirable that an alternate low idle speed setting be made available via switch input.";
CM_ SG_ 3221225472 EngMultiUnitSyncState "This feature is widely used in Industry to operate multiple engines from a single command source.";
CM_ SG_ 3221225472 EngAuxGovernorState "This is the Engine Auxiliary Governor feature.";
CM_ SG_ 3221225472 EngStartEnableDevice2Config "The start enable device installed for start enable device 2.";
CM_ SG_ 3221225472 EngStartEnableDevice1Config "The start enable device installed for start enable device 1.";
CM_ SG_ 3221225472 EngStartEnableDevice2 "Devices that assist an engine in starting, e.";
CM_ SG_ 3221225472 EngStartEnableDevice1 "Devices that assist an Engine in starting, e.";
CM_ SG_ 3221225472 BrakeTempWarning "This parameter indicates if the temperature in the service brakes exceeds a certain value.";
CM_ SG_ 3221225472 PrkngBrkeActuatorFullyActivated "Signal which indicates when the parking brake actuator is fully activated.";
CM_ SG_ 3221225472 XBRAccelerationLimit "The brake system may temporarily or generally limit the maximum brake performance available for external systems.";
CM_ SG_ 3221225472 XBRActiveCtrlMode "This parameter indicates which XBR Control Mode is executed by the brake system.";
CM_ SG_ 3221225472 XBRSystemState "This parameter indicates which external brake control is allowed.";
CM_ SG_ 3221225472 FoundationBrakeUse "This parameter indicates if the brake system presently uses the foundation brakes.";
CM_ SG_ 3221225472 HillHolderMode "Signal which indicates the current mode of the hill holder function.";
CM_ SG_ 3221225472 HaltBrakeMode "Signal which indicates the current mode of the halt brake function.";
CM_ SG_ 3221225472 EngExhstVlvActtonSystemOilPress "The absolute pressure of the oil in the hydraulic system that powers the engine exhaust valve actuation system";
CM_ SG_ 3221225472 EngExhstGsRcrcltion1OutletPress "EGR outlet pressure is measured immediately after the EGR valve.";
CM_ SG_ 3221225472 EngExhstGsRcrcltion1IntakePress "EGR intake gage pressure is measured after the EGR cooler and before the EGR valve.";
CM_ SG_ 3221225472 EngIntkVlvActtionSystemOilPress "The gage pressure of the oil in the hydraulic system that powers the engine intake valve actuation system";
CM_ SG_ 3221225472 TransitRunStatus "Status of the run switch for the vehicle.";
CM_ SG_ 3221225472 VehicleUseStatus "Used to indicate the proper or unauthorized use of the vehicle.";
CM_ SG_ 3221225472 SilentAlarmStatus "Used to report silent alarm push button status.";
CM_ SG_ 3221225472 PatronCount "Count of the number of passengers on a transit vehicle.";
CM_ SG_ 3221225472 TypeOfPassengerCount "Used to notify transit link devices of the type of passenger counting system used in the vehicle.";
CM_ SG_ 3221225472 NmbrOfBytsInMlpstIdentification "Number of bytes in the Milepost Identification.";
CM_ SG_ 3221225472 Agency "The identity of the agency involved in this transaction";
CM_ SG_ 3221225472 NmbrOfBytsInTrnstAssgndBlckIdntt "Number of bytes in the Transit Assigned Block Identity.";
CM_ SG_ 3221225472 NmbrOfBytsInTrnstAssgndRnIdntty "Number of bytes in the Transit Assigned Run Identity.";
CM_ SG_ 3221225472 NmbrOfBytsInTrnstAssgndRtIdntty "Number of bytes in the Transit Assigned Route Identity.";
CM_ SG_ 3221225472 VehicleID "Numerical designation of the vehicle.";
CM_ SG_ 3221225472 StrobeActivationCtrlStatus "Strobe activation control status";
CM_ SG_ 3221225472 TransitDoorEnable "Transit door enable";
CM_ SG_ 3221225472 PriorityOfRespSentByEmitter "Priority of response sent by emitter";
CM_ SG_ 3221225472 IntersectionPreemptionRq_Resp "Status of the intersection signal preemption";
CM_ SG_ 3221225472 TransitRouteIDUsage "Transit route ID usage";
CM_ SG_ 3221225472 RangeCodeEnable "Range code enable";
CM_ SG_ 3221225472 DriversFareboxSecurityCode "Security code for the farebox, numerical only.";
CM_ SG_ 3221225472 AssignedBlock "The agency defined block number for this trip";
CM_ SG_ 3221225472 AssignedRun "The agency defined run number for this trip";
CM_ SG_ 3221225472 AssignedRoute "The identity number assigned to this route.";
CM_ SG_ 3221225472 PatternNumber "The agency defined pattern number for this trip";
CM_ SG_ 3221225472 TripNumber "The identity number assigned to this trip.";
CM_ SG_ 3221225472 FarePresets "Fare Presets";
CM_ SG_ 3221225472 TripDirection "The general direction of travel for this trip.";
CM_ SG_ 3221225472 TripStatus "Trip Status";
CM_ SG_ 3221225472 FareboxServiceStatus "Indicates if the farebox is in or out of service.";
CM_ SG_ 3221225472 TransferSold "Indicates that a transfer was sold or issued on this transaction including its type and/or restrictions.";
CM_ SG_ 3221225472 RouteNumber "The route number issuing the transfer.";
CM_ SG_ 3221225472 TransferType "The kind of transfer used";
CM_ SG_ 3221225472 TypeOfService "The type of service provided";
CM_ SG_ 3221225472 InitialFareAgency "Identifies where the initial fare is paid";
CM_ SG_ 3221225472 PassCategory "Agency defined value indicating the category of the passenger associated with this fare";
CM_ SG_ 3221225472 FareValidity "Agency defined value indicating validity of this fare";
CM_ SG_ 3221225472 PaymentDetails "Payment details.";
CM_ SG_ 3221225472 TypeOfFare "Type of Fare";
CM_ SG_ 3221225472 PassengerType "Enumerated value representing the type/class of passenger, as defined by the agency.";
CM_ SG_ 3221225472 TransactionType "Enumerated value representing the type of transaction completed";
CM_ SG_ 3221225472 FareboxAlarmIdentifier "Indicates the nature of the farebox alarm condition.";
CM_ SG_ 3221225472 FareboxEmergencyStatus "Indicates if a farebox emergency condition exists.";
CM_ SG_ 3221225472 ExpandedFreezeFrameLength "The freeze frame length shall be equal to the number of bytes in the required parameters plus the number of bytes in the
manufacturer specific parameters.";
CM_ SG_ 3221225472 SPNSupported1High "This parameter defines the SPN(s) that is/are supported for the freeze frame and/or data stream information.";
CM_ SG_ 3221225472 SPNSupportTypeSTR3 "This parameter defines whether the applicable parameter (that is the SPN) is supported in the freeze frame, the data stream or both the freeze frame and data stream.";
CM_ SG_ 3221225472 SPNSupportTypeSTR2 "This parameter defines whether the applicable parameter (that is the SPN) is supported in the freeze frame, the data stream or both the freeze frame and data stream.";
CM_ SG_ 3221225472 SPNSupportTypeEFF3 "This parameter defines whether the applicable parameter (that is the SPN) is supported in the freeze frame, the data stream or both the freeze frame and data stream.";
CM_ SG_ 3221225472 SPNSupportTypeEFF2 "This parameter defines whether the applicable parameter (that is the SPN) is supported in the freeze frame, the data stream or both the freeze frame and data stream.";
CM_ SG_ 3221225472 SPNSupportTypeDS3 "This parameter defines whether the applicable parameter (that is the SPN) is supported in the freeze frame, the data stream or both the freeze frame and data stream.";
CM_ SG_ 3221225472 SPNSupportTypeDS2 "This parameter defines whether the applicable parameter (that is the SPN) is supported in the freeze frame, the data stream or both the freeze frame and data stream.";
CM_ SG_ 3221225472 SPNSupported3High "This parameter defines the SPN(s) that is/are supported for the freeze frame and/or data stream information.";
CM_ SG_ 3221225472 SPNSupported2High "This parameter defines the SPN(s) that is/are supported for the freeze frame and/or data stream information.";
CM_ SG_ 3221225472 SPNSupported3 "This parameter defines the SPN(s) that is/are supported for the freeze frame and/or data stream information.";
CM_ SG_ 3221225472 SPNSupported2 "This parameter defines the SPN(s) that is/are supported for the freeze frame and/or data stream information.";
CM_ SG_ 3221225472 SPNDataLength3 "The number of data bytes associated with the SPN in the Freeze Frame.";
CM_ SG_ 3221225472 SPNSupportTypeSTR1 "This parameter defines whether the applicable parameter (that is the SPN) is supported in the freeze frame, the data stream or both the freeze frame and data stream.";
CM_ SG_ 3221225472 SPNSupportTypeDS1 "This parameter defines whether the applicable parameter (that is the SPN) is supported in the freeze frame, the data stream or both the freeze frame and data stream.";
CM_ SG_ 3221225472 SPNSupportTypeEFF1 "This parameter defines whether the applicable parameter (that is the SPN) is supported in the freeze frame, the data stream or both the freeze frame and data stream.";
CM_ SG_ 3221225472 SPNDataLength2 "The number of data bytes associated with the SPN in the Freeze Frame.";
CM_ SG_ 3221225472 SPNDataLength1 "The number of data bytes associated with the SPN in the Freeze Frame.";
CM_ SG_ 3221225472 SPNSupported1 "This parameter defines the SPN(s) that is/are supported for the freeze frame and/or data stream information.";
CM_ SG_ 3221225472 EngAirStartPress "Gage pressure of air in an engine starting system that utilizes compressed air to provide the force required to rotate the";
CM_ SG_ 3221225472 EngTurboOilLevelSwitch "Switch signal which indicates the presence of oil at the turbocharger";
CM_ SG_ 3221225472 EngTurbo1Speed "Rotational velocity of rotor in the turbocharger.";
CM_ SG_ 3221225472 EngTurboLubeOilPress1 "Gage pressure of oil in turbocharger lubrication system.";
CM_ SG_ 3221225472 EngTotalIdleHours "Accumulated time of operation of the engine while under idle conditions.";
CM_ SG_ 3221225472 EngTotalIdleFuelUsed "Accumulated amount of fuel used during vehicle operation while under idle conditions.";
CM_ SG_ 3221225472 EngInjectorMeteringRail2Press "The gage pressure of fuel in the metering rail #2 as delivered from the supply pump to the injector metering intake.";
CM_ SG_ 3221225472 EngInjectorTimingRail1Press "The gage pressure of fuel in the timing rail delivered from the supply pump to the injector timing intake.";
CM_ SG_ 3221225472 EngInjectorMeteringRail1Press "The gage pressure of fuel in the primary, or first, metering rail as delivered from the supply pump to the injector metering";
CM_ SG_ 3221225472 EngInjectionCtrlPress "The gage pressure of the engine oil in the hydraulic accumulator that powers an intensifier used for fuel injection.";
CM_ SG_ 3221225472 NmbrOfSftwrIdentificationFields "Number of software identification designators represented in the software identification parameter group.";
CM_ SG_ 3221225472 SoftwareID3 "Software ID";
CM_ SG_ 3221225472 SoftwareID2 "Software ID";
CM_ SG_ 3221225472 SoftwareID1 "Software ID";
CM_ SG_ 3221225472 AuxI_O16 "Identifies the current status of auxiliary input/output functions that are configured uniquely per application.";
CM_ SG_ 3221225472 AuxI_O15 "Identifies the current status of auxiliary input/output functions that are configured uniquely per application.";
CM_ SG_ 3221225472 AuxI_O14 "Identifies the current status of auxiliary input/output functions that are configured uniquely per application.";
CM_ SG_ 3221225472 AuxI_O13 "Identifies the current status of auxiliary input/output functions that are configured uniquely per application.";
CM_ SG_ 3221225472 AuxI_O12 "Identifies the current status of auxiliary input/output functions that are configured uniquely per application.";
CM_ SG_ 3221225472 AuxI_O11 "Identifies the current status of auxiliary input/output functions that are configured uniquely per application.";
CM_ SG_ 3221225472 AuxI_O10 "Identifies the current status of auxiliary input/output functions that are configured uniquely per application.";
CM_ SG_ 3221225472 AuxI_O09 "Identifies the current status of auxiliary input/output functions that are configured uniquely per application.";
CM_ SG_ 3221225472 AuxI_O08 "Identifies the current status of auxiliary input/output functions that are configured uniquely per application.";
CM_ SG_ 3221225472 AuxI_O07 "Identifies the current status of auxiliary input/output functions that are configured uniquely per application.";
CM_ SG_ 3221225472 AuxI_O06 "Identifies the current status of auxiliary input/output functions that are configured uniquely per application.";
CM_ SG_ 3221225472 AuxI_O05 "Identifies the current status of auxiliary input/output functions that are configured uniquely per application.";
CM_ SG_ 3221225472 AuxI_O04 "Identifies the current status of auxiliary input/output functions that are configured uniquely per application.";
CM_ SG_ 3221225472 AuxI_O03 "Identifies the current status of auxiliary input/output functions that are configured uniquely per application.";
CM_ SG_ 3221225472 AuxI_O02 "Identifies the current status of auxiliary input/output functions that are configured uniquely per application.";
CM_ SG_ 3221225472 AuxI_O01 "Identifies the current status of auxiliary input/output functions that are configured uniquely per application.";
CM_ SG_ 3221225472 AuxI_OChannel2 "Auxiliary channel of data (16 bit) read by the ECU.";
CM_ SG_ 3221225472 AuxI_OChannel1 "Auxiliary channel of data (16 bit) read by the ECU.";
CM_ SG_ 3221225472 AddressAssignment "The source address that is to be assigned to the CA that has the NAME corresponding to the one conveyed in the first eight bytes of this Commanded Address message.";
CM_ SG_ 3221225472 Alt4Status "Alternator 4 operating status.";
CM_ SG_ 3221225472 Alt3Status "Alternator 3 operating status.";
CM_ SG_ 3221225472 Alt2Status "Alternator 2 operating status.";
CM_ SG_ 3221225472 Alt1Status "Alternator 1 operating status.";
CM_ SG_ 3221225472 AltSpeed "Actual rotation speed of the alternator.";
CM_ SG_ 3221225472 TestIdentifierSupported "Indicates the test identifiers that the controller supports.";
CM_ SG_ 3221225472 TestType "Identifies the non-continously monitored component identifier that was tested.";
CM_ SG_ 3221225472 OBDCompliance "Identifies the OBD compliance capabilityof the responding controller.";
CM_ SG_ 3221225472 PreviouslyActiveTroubleCodes "Identifies the number of previously active trouble codes that are present in a specific controller.";
CM_ SG_ 3221225472 ActiveTroubleCodes "Identifies the number of active trouble codes that are present in a specific controller.";
CM_ SG_ 3221225472 EngIntakeManifold1Press "The gage pressure measurement of the air intake manifold.";
CM_ SG_ 3221225472 FreezeFrameLength "The freeze frame length shall be equal to the number of bytes in the required parameters plus the number of bytes in the
manufacturer specific parameters.";
CM_ SG_ 3221225472 EngSpeed "Actual engine speed which is calculated over a minimum crankshaft angle of 720 degrees divided by the number of cylinders.";
CM_ SG_ 3221225472 EngTorqueMode "State signal which indicates which engine torque mode is currently generating, limiting, or controlling the torque.";
CM_ SG_ 3221225472 WheelBasedVehicleSpeed "Speed of the vehicle as calculated from wheel or tailshaft speed.";
CM_ SG_ 3221225472 EngPercentLoadAtCurrentSpeed "The ratio of actual engine percent torque (indicated) to maximum indicated torque available at the current engine speed,";
CM_ SG_ 3221225472 PneumaticControlLine "Signal which indicates that the towing vehicle has a pneumatic control line for the towed vehicle service braking system";
CM_ SG_ 3221225472 ABSOffroadRequest "Request to activate the ABS off-road function. The switch signal is independent of an actual ABS control situation.";
CM_ SG_ 3221225472 TwoElCircuitsBrakeDemand "Signal which indicates that the service brake demand value sent by the towing vehicle can be generated by one or two independent electrical braking circuit(s).";
CM_ SG_ 3221225472 BodyPressure "The actual pressure in a body on the towed vehicle.";
CM_ SG_ 3221225472 BodyFluidLevel "The actual fluid level in a body on the towed vehicle.";
CM_ SG_ 3221225472 ThermalBodyTemperature "The actual temperature in a thermal body on the towed vehicle.";
CM_ SG_ 3221225472 RearObstacleDistance "The actual distance between the back of the towed vehicle and any obstacle.";
CM_ SG_ 3221225472 AntiTheftDeviceStatus "Signal which indicates that the anti-theft device is switched on or off.";
CM_ SG_ 3221225472 ODDStatus "Signal which indicates that an obstacle detection device (ODD) is active/inactive.";
CM_ SG_ 3221225472 TransInertiaBrakeActuator "Identifies the status of the actuator that controls the inertia brake.";
CM_ SG_ 3221225472 TransDefuelActuator "Identifies the status of the actuator that controls the engine defuel mechanism.";
CM_ SG_ 3221225472 TransLockupClutchActuator "Identifies the status of the actuator that controls the lockup clutch.";
CM_ SG_ 3221225472 TransClutchActuator "Identifies the status of the actuator that controls the clutch.";
CM_ SG_ 3221225472 TransSplitterIndirectActuator "Identifies the status of the splitter indirect actuator in the auxiliary unit.";
CM_ SG_ 3221225472 TransSplitterDirectActuator "Identifies the status of the splitter direct actuator in the auxiliary unit.";
CM_ SG_ 3221225472 TransRangeLowActuator "Identifies the status of the range low actuator in the auxiliary unit.";
CM_ SG_ 3221225472 TransRangeHighActuator "Identifies the status of the range high actuator in the auxiliary unit.";
CM_ SG_ 3221225472 TransShiftFingerGearActuator2 "Identifies the status of the actuator that moves the shift finger identified as gear actuator #2.";
CM_ SG_ 3221225472 TransShiftFingerRailActuator2 "Identifies the status of the actuator that moves the shift finger identified as rail actuator #2.";
CM_ SG_ 3221225472 TransShiftFingerGearActuator1 "Identifies the status of the actuator that moves the shift finger identified as gear actuator #1.";
CM_ SG_ 3221225472 TransShiftFingerRailActuator1 "Identifies the status of the actuator that moves the shift finger identified as rail actuator #1.";
CM_ SG_ 3221225472 TrnsShftFngrCenterRailIndicator "Identifies the status of the shift finger in the center rail position.";
CM_ SG_ 3221225472 TrnsShftFngrEngagementIndicator "Identifies the status of the shift finger in the engagement position.";
CM_ SG_ 3221225472 TrnsShiftFingerNeutralIndicator "Indicates the status of the shift finger in the neutral position.";
CM_ SG_ 3221225472 TransShiftFingerRailPos "The current position of the shift finger in the rail direction.";
CM_ SG_ 3221225472 TransShiftFingerGearPos "The current position of the shift finger in the gear direction.";
CM_ SG_ 3221225472 PneumaticSupplyPressure "Actual supply pressure of the reservoir of the braking system.";
CM_ SG_ 3221225472 BrakeTemperature "Actual brake temperature.";
CM_ SG_ 3221225472 BrakeLining "Actual relative value of brake lining of a specific brake.";
CM_ SG_ 3221225472 TyrePressure "Actual tyre pressure without corrections.";
CM_ SG_ 3221225472 TyreWheelIdentTemp2 "Second part of identification number of the tyre or wheel (the number of axles).";
CM_ SG_ 3221225472 TyreWheelIdentTemp1 "First part of identification number of the tyre or wheel (position on each axle).";
CM_ SG_ 3221225472 TyreWheelIdentPressure2 "Second part of identification number of the tyre or wheel (the number of axles).";
CM_ SG_ 3221225472 TyreWheelIdentPressure1 "First part of identification number of the tyre or wheel (position on each axle).";
CM_ SG_ 3221225472 TyreWheelIdentLining2 "Second part of identification number of the tyre or wheel (the number of axles).";
CM_ SG_ 3221225472 TyreWheelIdentLining1 "First part of identification number of the tyre or wheel (position on each axle).";
CM_ SG_ 3221225472 VehiclePneumSupplySuff "Signal indicating the actual supply pressure of the reservoir of the braking system is insufficient or sufficient.";
CM_ SG_ 3221225472 BrakeTemperatureStatus "Signal which indicates that the brake temperature is higher than a specific level.";
CM_ SG_ 3221225472 BrakeLiningSufficient "Signal which indicates that the brake lining is sufficient/insufficient.";
CM_ SG_ 3221225472 TyrePressureSufficient "Signal which indicates that the tyre pressure is insufficient";
CM_ SG_ 3221225472 TransSynchronizerBrakeValue "The current modulated value for the air supply to the synchronizer brake.";
CM_ SG_ 3221225472 TransSynchronizerClutchValue "The current modulated value for the air supply to the synchronizer clutch.";
CM_ SG_ 3221225472 ReferenceRetarderTorque "This parameter is the 100% reference value for all defined indicated retarder torque parameters.";
CM_ SG_ 3221225472 AxleLoadSum "Sum of the static vertical loads of the vehicle axles.";
CM_ SG_ 3221225472 LoadingRampApproachAssist "The parameter indicates whether the loading ramp approach assistance is activated.";
CM_ SG_ 3221225472 SpringBrakeEngaged "Signal indicating the vehicle spring brake is engaged.";
CM_ SG_ 3221225472 ElectrLoadPropFunc "Signal indicating the vehicle is equipped with an electrical load proportional function.";
CM_ SG_ 3221225472 SpringBrakeInstalled "Signal indicating the vehicle has one or more axle(s) fitted with spring brakes.";
CM_ SG_ 3221225472 ElecSupplyOfNonBrakingSys "Signal which indicates the status of the supply of non-braking systems.";
CM_ SG_ 3221225472 AmberWarningSignalReq "Request from the towed vehicle to the commercial vehicle to activate the amber warning signal on the commercial vehicle.";
CM_ SG_ 3221225472 RedWarningSignalRequest "Request from the towed vehicle to the commercial vehicle to activate the red warning signal on the commercial vehicle, which indicates certain specified failures within the braking equipment of the towed vehicles.";
CM_ SG_ 3221225472 VehicleElectrSupplySuff "Signal indicating the actual supply voltage is sufficient/insufficient for proper brake function (including over voltage).";
CM_ SG_ 3221225472 TransForwardDirectionSwitch "Identifies the status of the switch that indicates forward direction.";
CM_ SG_ 3221225472 TransNeutralSwitch "Identifies the status of the switch that indicates neutral.";
CM_ SG_ 3221225472 TransReverseDirectionSwitch "Identifies the status of the switch that indicates reverse direction.";
CM_ SG_ 3221225472 TransLowRangeSenseSwitch "Identifies the status of the switch that represents low range.";
CM_ SG_ 3221225472 TransHighRangeSenseSwitch "Identifies the status of the switch that represents high range.";
CM_ SG_ 3221225472 TransOutputRetarder "Identifies the status of the transmission output retarder.";
CM_ SG_ 3221225472 HighResolutionTripDistance "Distance traveled during all or part of a journey.";
CM_ SG_ 3221225472 HghRslutionTotalVehicleDistance "Accumulated distance traveled by the vehicle during its operation.";
CM_ SG_ 3221225472 ServiceComponentIdentificationB "Identification of component needing service.";
CM_ SG_ 3221225472 ServiceComponentIdentificationA "Identification of component needing service.";
CM_ SG_ 3221225472 SrvceDelay_OperationalTimeBased "The time in vehicle operational time until the next vehicle service inspection is required.";
CM_ SG_ 3221225472 ServiceDelay_CalendarTimeBased "The time in weeks until the next vehicle service inspection is required.";
CM_ SG_ 3221225472 ServiceDistance "The distance which can be traveled by the vehicle before the next service inspection is required.";
CM_ SG_ 3221225472 RlativeSpeedRearAxle2RightWheel "The speed of the rear axle #2, right wheel relative to the front axle speed, SPN 904.";
CM_ SG_ 3221225472 RelativeSpeedRearAxle2LeftWheel "The speed of the rear axle #2, left wheel relative to the front axle speed, SPN 904.";
CM_ SG_ 3221225472 RlativeSpeedRearAxle1RightWheel "The speed of the rear axle #1, right wheel relative to the front axle speed, SPN 904.";
CM_ SG_ 3221225472 RelativeSpeedRearAxle1LeftWheel "The speed of the rear axle #1, left wheel relative to the front axle speed, SPN 904.";
CM_ SG_ 3221225472 RlativeSpeedFrontAxleRightWheel "The speed of the front axle, right wheel relative to the front axle speed, SPN 904.";
CM_ SG_ 3221225472 RelativeSpeedFrontAxleLeftWheel "The speed of the front axle, left wheel relative to the front axle speed, SPN 904.";
CM_ SG_ 3221225472 FrontAxleSpeed "The average speed of the two front wheels.";
CM_ SG_ 3221225472 EngRotationDirection "Direction of engine rotation, as reported by the engine.";
CM_ SG_ 3221225472 CrnkAttmptCntOnPrsntStrtAttempt "Reports the number of cranking cycles undergone during the present start attempt.";
CM_ SG_ 3221225472 EngIntakeManifoldPressCtrlMode "Indicates that the Boost Pressure Closed Loop Control status either open loop or closed loop.";
CM_ SG_ 3221225472 EngRatedSpeed "The maximum governed rotational velocity of the engine crankshaft under full load conditions.";
CM_ SG_ 3221225472 EngRatedPower "Net brake power that the engine will deliver continuously, specified for a given application at a rated speed.";
CM_ SG_ 3221225472 FanSpeed "The speed of the fan associated with engine coolant system.";
CM_ SG_ 3221225472 FanDriveState "This parameter is used to indicate the current state or mode of operation by the fan drive.";
CM_ SG_ 3221225472 EstPercentFanSpeed "Estimated fan speed as a ratio of the fan drive (current speed) to the fully engaged fan drive (maximum fan speed).";
CM_ SG_ 3221225472 HydFanMotorPress "The hydraulic pressure used to drive the fan system, sensed before the hydraulic fan motor.";
CM_ SG_ 3221225472 FanDriveBypassCmdStatus "Status of the Fan Drive Bypass Command as being commanded by the ECU.";
CM_ SG_ 3221225472 TripServiceBrakeApps "Total number of times the service brakes have been activated since the last trip reset.";
CM_ SG_ 3221225472 TripServiceBrakeDistance "Total distance over which the service brakes have been active since the last trip reset.";
CM_ SG_ 3221225472 TripCompressionBrakeDistance "Total distance over which the compression brakes have been active since the last trip reset.";
CM_ SG_ 3221225472 TotalCompressionBrakeDistance "Total distance over which the compression brakes have been active for the life of the engine.";
CM_ SG_ 3221225472 TripFanOnTimeDueToAManualSwitch "Total time the fan has been on due to manual activation by the operator (i.";
CM_ SG_ 3221225472 TripFanOnTime "Total time the fan has been on (due to an automatic trigger or manual trigger) since the last trip reset.";
CM_ SG_ 3221225472 TripFanOnTimeDueToA_CSystem "Total time the fan has been on due to the A/C system since the last trip reset.";
CM_ SG_ 3221225472 TripFanOnTimeDueToEngSystem "Total time the fan has been on due to engine triggers (i.";
CM_ SG_ 3221225472 TripDistanceInTopGear "Total distance accumulated while the vehicle has operated in top gear for a calibrated minimum time since the last trip reset.";
CM_ SG_ 3221225472 TripGearDownDistance "Total distance accumulated while the vehicle has operated in the gear which is one gear down from top gear and exceeds";
CM_ SG_ 3221225472 TripDistanceOnVSL "Total distance accumulated while the engine torque mode is road speed governing since the last trip reset.";
CM_ SG_ 3221225472 TripCruiseFuelUsed "Total fuel consumed while the engine is in the cruise hold state since the last trip reset.";
CM_ SG_ 3221225472 TripVehicleIdleFuelUsed "Total fuel consumed while neither the PTO or remote PTO governor is in the hold state, the engine speed is greater than";
CM_ SG_ 3221225472 TripDriveFuelUsed "Total fuel consumed while the engine speed is greater than zero, vehicle speed is greater than or equal to 2 km/h, and";
CM_ SG_ 3221225472 TrpPTOGovernorNonmovingFuelUsed "Total fuel consumed while either the PTO or remote PTO governors are in the hold state, the engine speed is greater";
CM_ SG_ 3221225472 TripPTOGovernorMovingFuelUsed "Total fuel consumed while either the PTO or remote PTO governors are in the hold state, the engine speed is greater";
CM_ SG_ 3221225472 TripDriveFuelEconomy "Trip drive fuel economy is equal to the distance traveled by vehicle in the drive state (engine speed greater than zero,";
CM_ SG_ 3221225472 TripDriveFuelEconomy "Trip drive fuel economy is equal to the distance traveled by vehicle in the drive state (engine speed greater than zero,";
CM_ SG_ 3221225472 TrpPTOGovernorNonmovingFuelUsed "Total fuel consumed while the PTO or remote PTO governors are in the hold state, the engine speed is greater than zero,";
CM_ SG_ 3221225472 TripVehicleIdleFuelUsed "Total fuel consumed while neither the PTO or remote PTO governors are active, the engine speed is greater than zero,";
CM_ SG_ 3221225472 TripCruiseFuelUsed "Total fuel consumed while the engine is in the cruise hold state since the last trip reset.";
CM_ SG_ 3221225472 TripDriveFuelUsed "Total fuel consumed while the engine speed is greater than zero, vehicle speed is greater than or equal to 2 km/h, and";
CM_ SG_ 3221225472 TripPTOGovernorMovingFuelUsed "Total fuel consumed while either the PTO or remote PTO governors are in the hold state, the engine speed is greater";
CM_ SG_ 3221225472 TotalEngCruiseTime "Total time that the engine has operated in the cruise hold state, excluding time in accelerator override, over the life of the engine.";
CM_ SG_ 3221225472 TotalDriveAverageLoadFactor "Average engine load factor while engine speed is greater than zero, vehicle speed is greater than or equal to 2 km/h, and";
CM_ SG_ 3221225472 TripDriveAverageLoadFactor "Average engine load factor while engine speed is greater than zero, vehicle speed is greater than or equal to 2 km/h, and";
CM_ SG_ 3221225472 TripAverageEngSpeed "Average speed of the engine since the last trip reset.";
CM_ SG_ 3221225472 TripMaxEngSpeed "Maximum engine speed achieved since the last trip reset.";
CM_ SG_ 3221225472 TripCruiseDistance "Total distance that the engine has operated in the cruise hold state, excluding time in accelerator override, since the last";
CM_ SG_ 3221225472 TripMaxVehicleSpeed "Maximum vehicle speed achieved while the engine speed is greater than zero and the accelerator pedal position (APS) is";
CM_ SG_ 3221225472 TripSuddenDecelerations "Total number of decelerations whenever the vehicle deceleration is more than XYZ km/h/sec (where XYZ is a calibratible";
CM_ SG_ 3221225472 TrpNmberOfIdleShutdownOverrides "Total number of times an operator disables idle shutdown to prevent an engine shutdown, since the last trip reset.";
CM_ SG_ 3221225472 TripNumberOfIdleShutdowns "Total number of times the engine has been shutdown due to idling too long (at normal idle or fast idle) since the last trip reset.";
CM_ SG_ 3221225472 TripNumberOfHotShutdowns "Total number of hot shutdowns since the last trip reset.";
CM_ SG_ 3221225472 TripTimeInDerateByEng "Total time accumulated when the engine final fueling has been derated due to an engine protection algorithm, since the last reset.";
CM_ SG_ 3221225472 TripTimeInGearDown "Total time accumulated when the vehicle has operated in one gear down from the top gear for a calibrated minimum time,";
CM_ SG_ 3221225472 TripTimeInTopGear "Total time accumulated when the vehicle has operated in top gear for a calibrated minimum time, since the last trip reset.";
CM_ SG_ 3221225472 TripTimeInVSL "Total time accumulated when the engine has operated on the vehicle speed limiter (VSL) while not in the cruise hold";
CM_ SG_ 3221225472 TotalEngPTOGovernorFuelUsed "Total fuel used while the PTO or remote PTO governors are in the hold state and engine speed is above zero, over the";
CM_ SG_ 3221225472 TripAverageFuelRate "Average fuel rate, equal to trip fuel divided by trip time while the engine speed is above zero, since the last trip reset.";
CM_ SG_ 3221225472 FlexibleFuelPercentage "Measured signal that indicates the percentage of alcohol in the fuel currently being used.";
CM_ SG_ 3221225472 TotalEngPTOGovernorFuelUsed "Total fuel used while the PTO or remote PTO governors are in the hold state and engine speed is above zero, over the";
CM_ SG_ 3221225472 TripAverageFuelRate "Average fuel rate, equal to trip fuel divided by trip time while the engine speed is above zero, since the last trip reset.";
CM_ SG_ 3221225472 EngFuelSpecificGravity "This parameter conveys the specific gravity of the gaseous fuel being used by the engine.";
CM_ SG_ 3221225472 TotalECURunTime "Total time accumulated over the life of the ECU, from ignition switch ON to ignition switch OFF.";
CM_ SG_ 3221225472 TotalECUDistance "Total distance accumulated over the life of the ECU.";
CM_ SG_ 3221225472 TripAirCompressorOnTime "Total time that the air compressor is on and compressing air since the last trip reset.";
CM_ SG_ 3221225472 TripIdleTime "Total time accumulated while the engine speed is greater than zero, both the PTO and remote PTO governors are";
CM_ SG_ 3221225472 TripEngRunningTime "Total time accumulated while the engine speed is greater than zero since the last trip reset.";
CM_ SG_ 3221225472 TripCruiseTime "Total time accumulated while the engine is in the cruise hold state, excluding time in accelerator override, since the last trip reset.";
CM_ SG_ 3221225472 TripPTOGovernorTime "Total time accumulated while the engine is in the PTO or remote PTO governor hold state since the last trip reset.";
CM_ SG_ 3221225472 TotalFuelUsed "Total fuel consumed (trip drive fuel + trip PTO moving fuel + trip PTO non-moving fuel + trip idle fuel) over the life of the engine.";
CM_ SG_ 3221225472 TripFuel "Total fuel consumed (trip drive fuel + trip PTO moving fuel + trip PTO non-moving fuel + trip idle fuel) since the last trip reset.";
CM_ SG_ 3221225472 ServiceBrakeCircuit2AirPress "The pneumatic pressure in the secondary service brake circuit or reservoir, supplying the front axle.";
CM_ SG_ 3221225472 ServiceBrakeCircuit1AirPress "The pneumatic pressure in the primary service brake circuit or reservoir, supplying the rear axle.";
CM_ SG_ 3221225472 AirCompressorStatus "Indicates whether the air compressor is actively compressing air.";
CM_ SG_ 3221225472 AirSuspensionSupplyPress "The pneumatic pressure in the circuit for the electronically controlled air suspension system.";
CM_ SG_ 3221225472 AuxEquipmentSupplyPress "The pneumatic pressure in the auxiliary circuit.";
CM_ SG_ 3221225472 ParkingAnd_OrTrailerAirPress "The pneumatic pressure in the circuit or reservoir for the parking brake and/or the trailer supply.";
CM_ SG_ 3221225472 PneumaticSupplyPress "The pneumatic pressure in the main reservoir, sometimes referred to as the wet tank.";
CM_ SG_ 3221225472 BrkAppPrssHghRngRrAxl3RghtWheel "The brake application pressure for the right wheel on the rear axle #3.";
CM_ SG_ 3221225472 BrkAppPrssHghRngRrAxl3LeftWheel "The brake application pressure for the left wheel on the rear axle #3.";
CM_ SG_ 3221225472 BrkAppPrssHghRngRrAxl2RghtWheel "The brake application pressure for the right wheel on the rear axle #2.";
CM_ SG_ 3221225472 BrkAppPrssHghRngRrAxl2LeftWheel "The brake application pressure for the left wheel on the rear axle #2.";
CM_ SG_ 3221225472 BrkAppPrssHghRngRrAxl1RghtWheel "The brake application pressure for the right wheel on the rear axle #1.";
CM_ SG_ 3221225472 BrkAppPrssHghRngRrAxl1LeftWheel "The brake application pressure for the left wheel on the rear axle #1.";
CM_ SG_ 3221225472 BrkAppPrssHghRngFrntAxlRghtWhel "The brake application pressure for the right wheel on the front axle.";
CM_ SG_ 3221225472 BrkAppPrssHghRngFrntAxlLftWheel "The brake application pressure for the left wheel on the front axle.";
CM_ SG_ 3221225472 BrkLnngRmnngRearAxle3RightWheel "The percentage of brake lining which can still be measured for the right wheel on the rear axle #3.";
CM_ SG_ 3221225472 BrkLnngRmningRearAxle3LeftWheel "The percentage of brake lining which can still be measured for the left wheel on the rear axle #3.";
CM_ SG_ 3221225472 BrkLnngRmnngRearAxle2RightWheel "The percentage of brake lining which can still be measured for the right wheel on the rear axle #2.";
CM_ SG_ 3221225472 BrkLnngRmningRearAxle2LeftWheel "The percentage of brake lining which can still be measured for the left wheel on the rear axle #2.";
CM_ SG_ 3221225472 BrkLnngRmnngRearAxle1RightWheel "The percentage of brake lining which can still be measured for the right wheel on the rear axle #1.";
CM_ SG_ 3221225472 BrkLnngRmningRearAxle1LeftWheel "The percentage of brake lining which can still be measured for the left wheel on the rear axle #1.";
CM_ SG_ 3221225472 BrkLnngRmnngFrontAxleRightWheel "The percentage of brake lining which can still be measured for the right wheel on the front axle.";
CM_ SG_ 3221225472 BrkLnngRmningFrontAxleLeftWheel "The percentage of brake lining which can still be measured for the left wheel on the front axle.";
CM_ SG_ 3221225472 ClutchLifeRemaining "Signal which indicates the actual clutch life remaining in percent.";
CM_ SG_ 3221225472 LowestPossibleGear "The transmission calculates this gear continuously.";
CM_ SG_ 3221225472 HighestPossibleGear "The transmission calculates this gear continuously.";
CM_ SG_ 3221225472 RecommendedGear "The transmission calculates this gear continuously.";
CM_ SG_ 3221225472 EngTurboWastegateValvePos "The position of the turbocharger wastegate valve (not the electronic wastegate control valve).";
CM_ SG_ 3221225472 EngGsMssFlwSnsrFelingCorrection "The amount of fuel the Gas Mass Flow Sensor is sensing should be added or subtracted compared to the maximum";
CM_ SG_ 3221225472 EngDsiredAbsIntakeManifoldPress "The desired absolute intake manifold pressure of the engine.";
CM_ SG_ 3221225472 EngGasFuelCorrectionFactor "A correction to a predefined gaseous fuel energy (expressed in energy per unit volume) represented as a percentage.";
CM_ SG_ 3221225472 EngExhstGsOxygnSnsrClsdLpOprton "Indicates whether the engine is using the Exhaust Gas Oxygen sensor to control the air/fuel ratio.";
CM_ SG_ 3221225472 EngExhstGsOxygnSnsrFlngCrrction "The amount of fueling change required by the system based on the measured Exhaust Oxygen value compared to the";
CM_ SG_ 3221225472 EngActualExhaustOxygen "The actual amount of oxygen in the exhaust represented as a percentage by volume with respect to the total volume of";
CM_ SG_ 3221225472 EngDesiredExhaustOxygen "The desired amount of oxygen in the exhaust represented as a percentage by volume with respect to the total volume of";
CM_ SG_ 3221225472 EngDesiredRatedExhaustOxygen "The desired amount of oxygen in the exhaust at rated conditions represented as a percentage by volume with respect to";
CM_ SG_ 3221225472 ArticulationAngle "Angle of deflection of an articulated transit vehicle.";
CM_ SG_ 3221225472 EngAltWinding3Temp "Temperature of the windings inside the alternator.";
CM_ SG_ 3221225472 EngAltWinding2Temp "Temperature of the windings inside the alternator.";
CM_ SG_ 3221225472 EngAltWinding1Temp "Temperature of the windings inside the alternator.";
CM_ SG_ 3221225472 EngAltBearing2Temp "Temperature of the bearing inside the alternator.";
CM_ SG_ 3221225472 EngAltBearing1Temp "Temperature of the bearing inside the alternator.";
CM_ SG_ 3221225472 EngTurbo4BoostPress "Gage pressure of air measured downstream of the compressor discharge side of the turbocharger.";
CM_ SG_ 3221225472 EngTurbo3BoostPress "Gage pressure of air measured downstream of the compressor discharge side of the turbocharger.";
CM_ SG_ 3221225472 EngTurbo2BoostPress "Gage pressure of air measured downstream of the compressor discharge side of the turbocharger.";
CM_ SG_ 3221225472 EngTurbo1BoostPress "Gage pressure of air measured downstream of the compressor discharge side of the turbocharger.";
CM_ SG_ 3221225472 EngIntakeManifold6Temp "Temperature of pre-combustion air found in intake manifold number 6 of engine air supply system.";
CM_ SG_ 3221225472 EngIntakeManifold5Temp "Temperature of pre-combustion air found in intake manifold number 5 of engine air supply system.";
CM_ SG_ 3221225472 EngIntakeManifold4Temp "Temperature of pre-combustion air found in intake manifold of engine air supply system.";
CM_ SG_ 3221225472 EngIntakeManifold3Temp "Temperature of pre-combustion air found in intake manifold of engine air supply system.";
CM_ SG_ 3221225472 EngIntakeManifold2Temp "Temperature of pre-combustion air found in intake manifold of engine air supply system.";
CM_ SG_ 3221225472 EngExhstGsRcrculation1DiffPress "Differential pressure across the Exhaust Gas Recirculation (EGR) system";
CM_ SG_ 3221225472 EngExhaustGasRecirculation1Temp "Temperature of Recirculated Exhaust Gas.";
CM_ SG_ 3221225472 EngECUTemp "Temperature of the engine electronic control unit.";
CM_ SG_ 3221225472 EngOilTemp2 "Temperature of the engine lubricant.";
CM_ SG_ 3221225472 EngExhaustGasPort4Temp "Temperature at the cylinder exhaust port of the engine.";
CM_ SG_ 3221225472 EngExhaustGasPort3Temp "Temperature at the cylinder exhaust port of the engine.";
CM_ SG_ 3221225472 EngExhaustGasPort2Temp "Temperature at the cylinder exhaust port of the engine.";
CM_ SG_ 3221225472 EngExhaustGasPort1Temp "Temperature at the cylinder exhaust port of the engine.";
CM_ SG_ 3221225472 EngExhaustGasPort8Temp "Temperature at the cylinder exhaust port of the engine.";
CM_ SG_ 3221225472 EngExhaustGasPort7Temp "Temperature at the cylinder exhaust port of the engine.";
CM_ SG_ 3221225472 EngExhaustGasPort6Temp "Temperature at the cylinder exhaust port of the engine.";
CM_ SG_ 3221225472 EngExhaustGasPort5Temp "Temperature at the cylinder exhaust port of the engine.";
CM_ SG_ 3221225472 EngExhaustGasPort12Temp "Temperature at the cylinder exhaust port of the engine.";
CM_ SG_ 3221225472 EngExhaustGasPort11Temp "Temperature at the cylinder exhaust port of the engine.";
CM_ SG_ 3221225472 EngExhaustGasPort10Temp "Temperature at the cylinder exhaust port of the engine.";
CM_ SG_ 3221225472 EngExhaustGasPort9Temp "Temperature at the cylinder exhaust port of the engine.";
CM_ SG_ 3221225472 EngExhaustGasPort16Temp "Temperature at the cylinder exhaust port of the engine.";
CM_ SG_ 3221225472 EngExhaustGasPort15Temp "Temperature at the cylinder exhaust port of the engine.";
CM_ SG_ 3221225472 EngExhaustGasPort14Temp "Temperature at the cylinder exhaust port of the engine.";
CM_ SG_ 3221225472 EngExhaustGasPort13Temp "Temperature at the cylinder exhaust port of the engine.";
CM_ SG_ 3221225472 EngExhaustGasPort20Temp "Temperature at the cylinder exhaust port of the engine.";
CM_ SG_ 3221225472 EngExhaustGasPort19Temp "Temperature at the cylinder exhaust port of the engine.";
CM_ SG_ 3221225472 EngExhaustGasPort18Temp "Temperature at the cylinder exhaust port of the engine.";
CM_ SG_ 3221225472 EngExhaustGasPort17Temp "Temperature at the cylinder exhaust port of the engine.";
CM_ SG_ 3221225472 EngMainBearing4Temp "Temperature of the main bearing which supports the crankshaft of the engine.";
CM_ SG_ 3221225472 EngMainBearing3Temp "Temperature of the main bearing which supports the crankshaft of the engine.";
CM_ SG_ 3221225472 EngMainBearing2Temp "Temperature of the main bearing which supports the crankshaft of the engine.";
CM_ SG_ 3221225472 EngMainBearing1Temp "Temperature of the main bearing which supports the crankshaft of the engine.";
CM_ SG_ 3221225472 EngMainBearing8Temp "Temperature of the main bearing which supports the crankshaft of the engine.";
CM_ SG_ 3221225472 EngMainBearing7Temp "Temperature of the main bearing which supports the crankshaft of the engine.";
CM_ SG_ 3221225472 EngMainBearing6Temp "Temperature of the main bearing which supports the crankshaft of the engine.";
CM_ SG_ 3221225472 EngMainBearing5Temp "Temperature of the main bearing which supports the crankshaft of the engine.";
CM_ SG_ 3221225472 EngMainBearing11Temp "Temperature of the main bearing which supports the crankshaft of the engine.";
CM_ SG_ 3221225472 EngMainBearing10Temp "Temperature of the main bearing which supports the crankshaft of the engine.";
CM_ SG_ 3221225472 EngMainBearing9Temp "Temperature of the main bearing which supports the crankshaft of the engine.";
CM_ SG_ 3221225472 EngTurbo4Speed "Rotational velocity of rotor in the turbocharger.";
CM_ SG_ 3221225472 EngTurbo3Speed "Rotational velocity of rotor in the turbocharger.";
CM_ SG_ 3221225472 EngTurbo2Speed "Rotational velocity of rotor in the turbocharger.";
CM_ SG_ 3221225472 EngTurboLubeOilPress2 "Gage pressure of oil in turbocharger lubrication system.";
CM_ SG_ 3221225472 EngTurbo4CompressorIntakeTemp "Temperature of the air entering the compressor side of the turbocharger.";
CM_ SG_ 3221225472 EngTurbo3CompressorIntakeTemp "Temperature of the air entering the compressor side of the turbocharger.";
CM_ SG_ 3221225472 EngTurbo2CompressorIntakeTemp "Temperature of the air entering the compressor side of the turbocharger.";
CM_ SG_ 3221225472 EngTurbo1CompressorIntakeTemp "Temperature of the air entering the compressor side of the turbocharger.";
CM_ SG_ 3221225472 EngTurbo4CompressorIntakePress "Gage pressure of the air entering the compressor side of the turbocharger.";
CM_ SG_ 3221225472 EngTurbo3CompressorIntakePress "Gage pressure of the air entering the compressor side of the turbocharger.";
CM_ SG_ 3221225472 EngTurbo2CompressorIntakePress "Gage pressure of the air entering the compressor side of the turbocharger.";
CM_ SG_ 3221225472 EngTurbo1CompressorIntakePress "Gage pressure of the air entering the compressor side of the turbocharger.";
CM_ SG_ 3221225472 EngTurbo4TurbineIntakeTemp "Temperature of the combustion by-products entering the turbine side of the turbocharger.";
CM_ SG_ 3221225472 EngTurbo3TurbineIntakeTemp "Temperature of the combustion by-products entering the turbine side of the turbocharger.";
CM_ SG_ 3221225472 EngTurbo2TurbineIntakeTemp "Temperature of the combustion by-products entering the turbine side of the turbocharger.";
CM_ SG_ 3221225472 EngTurbo1TurbineIntakeTemp "Temperature of the combustion by-products entering the turbine side of the turbocharger.";
CM_ SG_ 3221225472 EngTurbo4TurbineOutletTemp "Temperature of the combustion by-products exiting the turbine side of the turbocharger.";
CM_ SG_ 3221225472 EngTurbo3TurbineOutletTemp "Temperature of the combustion by-products exiting the turbine side of the turbocharger.";
CM_ SG_ 3221225472 EngTurbo2TurbineOutletTemp "Temperature of the combustion by-products exiting the turbine side of the turbocharger.";
CM_ SG_ 3221225472 EngTurbo1TurbineOutletTemp "Temperature of the combustion by-products exiting the turbine side of the turbocharger.";
CM_ SG_ 3221225472 EngTrbWstgteActuator1TempStatus "Used to identify the status of the Engine Turbocharger Wastegate Actuator 1 drive circuitry temperature.";
CM_ SG_ 3221225472 EngTrbWstgtActtr1PreliminaryFMI "Used to identify the applicable J1939-73 FMI detected in the Engine Turbocharger Wastegate Actuator 1 by the";
CM_ SG_ 3221225472 EngDsrdTrbWastegateActuator2Pos "The Requested Valve position of the Turbocharger Wastegate Valve 2, commanded by the engine ECM.";
CM_ SG_ 3221225472 EngDsrdTrbWastegateActuator1Pos "The Requested Valve position of the Turbocharger Wastegate Valve 1, commanded by the engine ECM.";
CM_ SG_ 3221225472 EngTurboWastegateActuator4Pos "Position of the wastegate drive.";
CM_ SG_ 3221225472 EngTurboWastegateActuator3Pos "Position of the wastegate drive.";
CM_ SG_ 3221225472 EngTurboWastegateActuator2Pos "Position of the wastegate drive.";
CM_ SG_ 3221225472 EngTurboWastegateActuator1Pos "Position of the wastegate drive.";
CM_ SG_ 3221225472 EngTrbWstgtActuatorCtrlAirPress "Gage pressure of the air used to control the actuator which opens and closes the wastegate valve.";
CM_ SG_ 3221225472 EngOperationTimeSinceRebuild "The time in engine operation since the last engine rebuild.";
CM_ SG_ 3221225472 SeaWaterPumpOutletPress "Gauge pressure of liquid found at outlet of sea water pump in sea water cooling system.";
CM_ SG_ 3221225472 EngAuxCoolantTemp "Temperature of coolant found in the intercooler which is located after the turbocharger.";
CM_ SG_ 3221225472 EngAuxCoolantPress "Gage pressure of coolant found in the intercooler which is located after the turbocharger.";
CM_ SG_ 3221225472 TurningGearEngaged "Status signal which indicates that the turning gear is engaged.";
CM_ SG_ 3221225472 SafetyWireStatus "Status signal which indicates that the safety wire has been activated.";
CM_ SG_ 3221225472 ElectricalLoad "Electrical power delivered by the engine to the electrical system connected to the generator.";
CM_ SG_ 3221225472 TransGearRatio "The transmission configuration describes the number of forward gears, the number of reverse gears, and the ratio of each";
CM_ SG_ 3221225472 NumberOfForwardGearRatios "Number of forward gear ratios in the transmission, provided as part of the configuration.";
CM_ SG_ 3221225472 NumberOfReverseGearRatios "Number of reverse gear ratios in the transmission, provided as part of the transmission configuration.";
CM_ SG_ 3221225472 PercentTorqueAtPeakTorquePoint5 "The torque limit that indicates the available retarder torque which can be provided by the retarder at point 5 of the retarder";
CM_ SG_ 3221225472 ReferenceRetarderTorque "This parameter is the 100% reference value for all defined indicated retarder torque parameters.";
CM_ SG_ 3221225472 RetarderSpeedAtPeakTorquePoint5 "Please reference PGN 65249";
CM_ SG_ 3221225472 PercentTorqueAtPoint4 "The torque limit that indicates the available retarder torque which can be provided by the retarder at points 3 and 4 of the";
CM_ SG_ 3221225472 RetarderSpeedAtPoint4 "Retarder speed of point 4 of the engine retarder torque map.";
CM_ SG_ 3221225472 PercentTorqueAtPoint3 "The torque limit that indicates the available retarder torque which can be provided by the retarder at points 3 and 4 of the";
CM_ SG_ 3221225472 RetarderSpeedAtPoint3 "Retarder speed of point 3 of the engine retarder torque map.";
CM_ SG_ 3221225472 PercentTorqueAtMaxSpeedPoint2 "The torque limit that indicates the available retarder torque which can be provided by the retarder at its maximum speed.";
CM_ SG_ 3221225472 MaxRetarderSpeedPoint2 "Maximum speed of retarder (Please reference PGN 65249).";
CM_ SG_ 3221225472 PercentTorqueAtIdlePoint1 "The torque limit that indicates the available retarder torque which can be provided by the retarder at idle speed.";
CM_ SG_ 3221225472 RetarderSpeedAtIdlePoint1 "Please reference PGN 65249";
CM_ SG_ 3221225472 RetarderCtrlMethod "This parameter identifies the number of steps used by the retarder.";
CM_ SG_ 3221225472 RetarderLocation "This parameter defines whether the [torque/speed curve] defined by the retarder configuration message (PGN 65249) is";
CM_ SG_ 3221225472 RetarderType "A vehicle retarder is a supplementary device to the wheel brakes for the driver to better control the vehicle.";
CM_ SG_ 3221225472 TotalVehicleDistance "Accumulated distance traveled by vehicle during its operation.";
CM_ SG_ 3221225472 TripDistance "Distance traveled during all or part of a journey.";
CM_ SG_ 3221225472 PowerTakeoffSetSpeed "Rotational velocity selected by operator for device used to transmit engine power to auxiliary equipment.";
CM_ SG_ 3221225472 PowerTakeoffSpeed "Rotational velocity of device used to transmit engine power to auxiliary equipment.";
CM_ SG_ 3221225472 PowerTakeoffOilTemp "Temperature of lubricant in device used to transmit engine power to auxiliary equipment.";
CM_ SG_ 3221225472 OprtrEngPTOGvrnrMmrySlectSwitch "Measured state of the operator's engine PTO governor memory select switch.";
CM_ SG_ 3221225472 EngRmtPTOGvrnrVrblSpdCtrlSwitch "Switch signal which indicates that the remote PTO governor toggle switch is in the enabled (ON) position.";
CM_ SG_ 3221225472 EngRmtPTOGvrnrPrprgrmmdSpdCtrlSw "Switch signal which indicates that the remote PTO governor toggle switch is in the enabled (ON) position.";
CM_ SG_ 3221225472 EngPTOGvrnrCst_DecelerateSwitch "Switch signal of the PTO control activator which indicates that the activator is in the position to \"coast/decelerate\" the PTO";
CM_ SG_ 3221225472 EngPTOGovernorSetSwitch "Switch signal of the PTO control activator which indicates that the activator is in the position to \"set\" the engine PTO";
CM_ SG_ 3221225472 EngPTOGovernorResumeSwitch "Switch signal of the PTO control activator which indicates that the activator is in the position to \"resume\" a previously";
CM_ SG_ 3221225472 EngPTOGovernorEnableSwitch "Switch signal which indicates that the PTO governor toggle switch is in the enabled (ON) position and therefore it is";
CM_ SG_ 3221225472 EngPTOGovernorAccelerateSwitch "Switch signal of the PTO control activator which indicates that the activator is in the position to \"accelerate\" the PTO";
CM_ SG_ 3221225472 RmtPTOPrprgrmmdSpeedCtrlSwitch2 "Switch signal which indicates that the remote PTO toggle switch #2 is in the enabled (ON) position.";
CM_ SG_ 3221225472 AuxInputIgnoreSwitch "Switch signal which overrides other switch input's ability to kick out of an engine's operating condition.";
CM_ SG_ 3221225472 EngCoolantLevel "Ratio of volume of liquid found in engine cooling system to total cooling system volume.";
CM_ SG_ 3221225472 EngCoolantPress "Gage pressure of liquid found in engine cooling system.";
CM_ SG_ 3221225472 EngCrankcasePress "Gage pressure inside engine crankcase.";
CM_ SG_ 3221225472 EngOilPress "Gage pressure of oil in engine lubrication system as provided by oil pump.";
CM_ SG_ 3221225472 EngOilLevel "Ratio of current volume of engine sump oil to maximum required volume.";
CM_ SG_ 3221225472 EngExCrankcaseBlowbyPress "Differential crankcase blow-by pressure as measured through a tube with a venturi.";
CM_ SG_ 3221225472 EngFuelDeliveryPress "Gage pressure of fuel in system as delivered from supply pump to the injection pump.";
CM_ SG_ 3221225472 EngFuelTemp1 "Temperature of fuel (or gas) passing through the first fuel control system.";
CM_ SG_ 3221225472 EngIntercoolerThermostatOpening "The current position of the thermostat used to regulate the temperature of the engine intercooler.";
CM_ SG_ 3221225472 EngIntercoolerTemp "Temperature of liquid found in the intercooler located after the turbocharger.";
CM_ SG_ 3221225472 EngTurboOilTemp "Temperature of the turbocharger lubricant.";
CM_ SG_ 3221225472 EngOilTemp1 "Temperature of the engine lubricant.";
CM_ SG_ 3221225472 EngCoolantTemp "Temperature of liquid found in engine cooling system.";
CM_ SG_ 3221225472 CruiseCtrlLowSetLimitSpeed "Minimum vehicle velocity at which cruise can be set or minimum vehicle velocity for cruise operation before it will exit";
CM_ SG_ 3221225472 CruiseCtrlHighSetLimitSpeed "Maximum vehicle velocity at which cruise can be set.";
CM_ SG_ 3221225472 VehicleIdentificationNumber "Vehicle Identification Number";
CM_ SG_ 3221225472 CargoWeight_30 "The mass of freight carried.";
CM_ SG_ 3221225472 CargoWeight_20 "The mass of freight carried.";
CM_ SG_ 3221225472 CargoWeight_10 "The mass of freight carried.";
CM_ SG_ 3221225472 CargoWeight_00 "The mass of freight carried.";
CM_ SG_ 3221225472 TrailerWeight_30 "Total mass of freight-carrying vehicle designed to be pulled by truck, including the weight of the contents.";
CM_ SG_ 3221225472 TrailerWeight_20 "Total mass of freight-carrying vehicle designed to be pulled by truck, including the weight of the contents.";
CM_ SG_ 3221225472 TrailerWeight_10 "Total mass of freight-carrying vehicle designed to be pulled by truck, including the weight of the contents.";
CM_ SG_ 3221225472 TrailerWeight_00 "Total mass of freight-carrying vehicle designed to be pulled by truck, including the weight of the contents.";
CM_ SG_ 3221225472 AxleWeight_30 "Total mass imposed by the tires on the road surface at the specified axle.";
CM_ SG_ 3221225472 AxleWeight_20 "Total mass imposed by the tires on the road surface at the specified axle.";
CM_ SG_ 3221225472 AxleWeight_10 "Total mass imposed by the tires on the road surface at the specified axle.";
CM_ SG_ 3221225472 AxleWeight_00 "Total mass imposed by the tires on the road surface at the specified axle.";
CM_ SG_ 3221225472 EngTotalFuelUsed "Accumulated amount of fuel used during vehicle operation.";
CM_ SG_ 3221225472 EngTripFuel "Fuel consumed during all or part of a journey.";
CM_ SG_ 3221225472 Altitude "Altitude of the vehicle referenced to sea level at standard atmospheric pressure and temperature.";
CM_ SG_ 3221225472 Pitch "Pitch of the vehicle as calculated by the navigation device(s).";
CM_ SG_ 3221225472 NavigationBasedVehicleSpeed "Speed of the vehicle as calculated from a device such as a Global Positioning System (GPS).";
CM_ SG_ 3221225472 CompassBearing "Present compass bearing of vehicle.";
CM_ SG_ 3221225472 TotalPowerTakeoffHours "Accumulated time of operation of power takeoff device.";
CM_ SG_ 3221225472 TotalVehicleHours "Accumulated time of operation of vehicle.";
CM_ SG_ 3221225472 LocalHourOffset "The hour component of the offset between the UTC (Universal Time Coordinate) time and date and a local time zone time";
CM_ SG_ 3221225472 LocalMinuteOffset "The minute component of the offset between the UTC time and date and a local time zone time and date.";
CM_ SG_ 3221225472 Year "The year component of the current calendar date.";
CM_ SG_ 3221225472 Day "The day component of the current calendar date.";
CM_ SG_ 3221225472 Month "The month component of the current calendar date.";
CM_ SG_ 3221225472 Hours "The hour component of the current time of day.";
CM_ SG_ 3221225472 Minutes "The minutes component of the current time of day.";
CM_ SG_ 3221225472 Seconds "The seconds component of the current time of day.";
CM_ SG_ 3221225472 EngTotalRevolutions "Accumulated number of revolutions of engine crankshaft during its operation.";
CM_ SG_ 3221225472 EngTotalHoursOfOperation "Accumulated time of operation of engine.";
CM_ SG_ 3221225472 EngOverspeedTest "The engine overspeed test signal as measured by the reporting ECM.";
CM_ SG_ 3221225472 EngAirShutoffCmdStatus "State signal which indicates when the Air Shutoff driver output is being driven.";
CM_ SG_ 3221225472 EngAlarmOutputCmdStatus "State signal which indicates when the Alarm driver output is being driven.";
CM_ SG_ 3221225472 EngAlarmAcknowledge "The Engine Alarm Acknowledge Input signal as measured by the reporting ECM.";
CM_ SG_ 3221225472 EngProtectionSystemConfig "Parameter which indicates the configuration of the engine shutdown system.";
CM_ SG_ 3221225472 EngProtectionSystemTimerState "Status signal which indicates the current mode of the engine protection system timer system.";
CM_ SG_ 3221225472 EngPrtectionSystemTimerOverride "Status signal which indicates the status of the override feature of the engine protection system timer.";
CM_ SG_ 3221225472 EngPrtctnSystmApprchingShutdown "Status signal which indicates that engine shutdown is imminent.";
CM_ SG_ 3221225472 EngWaitToStartLamp "Lamp signal which indicates that the engine is too cold to start and the operator should wait until the signal becomes";
CM_ SG_ 3221225472 RefrigerantHighPressSwitch "Switch signal which indicates the position of the high pressure switch in the coolant circuit of an air conditioning system.";
CM_ SG_ 3221225472 RefrigerantLowPressSwitch "Switch signal which indicates the position of the low pressure switch in the coolant circuit of an air conditioning system.";
CM_ SG_ 3221225472 A_CHighPressFanSwitch "Switch signal which indicates that the pressure in the coolant circuit of an air conditioning system is high and the fan may";
CM_ SG_ 3221225472 EngIdleShutdownTimerFunction "Parameter which indicates the configuration of the idle shutdown timer system.";
CM_ SG_ 3221225472 EngIdleShutdownTimerState "Status signal which indicates the current mode of operation of the idle shutdown timer system.";
CM_ SG_ 3221225472 EngIdleShutdownTimerOverride "Status signal which indicates the status of the override feature of the idle shutdown timer system.";
CM_ SG_ 3221225472 EngIdleShutdownDriverAlertMode "Status signal which indicates the status of the driver alert mode of the idle shutdown timer system.";
CM_ SG_ 3221225472 PTOShutdownHasShutdownEng "Status signal which identifies whether or not the engine has been shutdown by the PTO shutdown system.";
CM_ SG_ 3221225472 EngPrtctnSystmHasShutdownEngine "Status signal which indicates whether or not the engine protection system has shutdown the engine.";
CM_ SG_ 3221225472 EngIdlShutdownHasShutdownEngine "Status signal which identifies whether or not the engine has been shutdown by the idle shutdown timer system.";
CM_ SG_ 3221225472 EngAirShutoffStatus "State signal which indicates the actual measured position of the Air Shutoff.";
CM_ SG_ 3221225472 EngAirIntakeTemp "Temperature of air entering vehicle air induction system.";
CM_ SG_ 3221225472 RoadSurfaceTemp "Indicated temperature of road surface over which vehicle is operating.";
CM_ SG_ 3221225472 AmbientAirTemp "Temperature of air surrounding vehicle.";
CM_ SG_ 3221225472 CabInteriorTemp "Temperature of air inside the part of the vehicle that encloses the driver and vehicle operating controls.";
CM_ SG_ 3221225472 BarometricPress "Absolute air pressure of the atmosphere.";
CM_ SG_ 3221225472 TirePressThresholdDetection_13 "Signal indicating the pressure level of the tire.";
CM_ SG_ 3221225472 TirePressThresholdDetection_12 "Signal indicating the pressure level of the tire.";
CM_ SG_ 3221225472 TirePressThresholdDetection_11 "Signal indicating the pressure level of the tire.";
CM_ SG_ 3221225472 TirePressThresholdDetection_10 "Signal indicating the pressure level of the tire.";
CM_ SG_ 3221225472 TirePressThresholdDetection_01 "Signal indicating the pressure level of the tire.";
CM_ SG_ 3221225472 TirePress_33 "Pressure at which air is contained in cavity formed by tire and rim.";
CM_ SG_ 3221225472 TirePress_32 "Pressure at which air is contained in cavity formed by tire and rim.";
CM_ SG_ 3221225472 TirePress_31 "Pressure at which air is contained in cavity formed by tire and rim.";
CM_ SG_ 3221225472 TirePress_30 "Pressure at which air is contained in cavity formed by tire and rim.";
CM_ SG_ 3221225472 TirePress_23 "Pressure at which air is contained in cavity formed by tire and rim.";
CM_ SG_ 3221225472 TirePress_22 "Pressure at which air is contained in cavity formed by tire and rim.";
CM_ SG_ 3221225472 TirePress_21 "Pressure at which air is contained in cavity formed by tire and rim.";
CM_ SG_ 3221225472 TirePress_20 "Pressure at which air is contained in cavity formed by tire and rim.";
CM_ SG_ 3221225472 TirePress_13 "Pressure at which air is contained in cavity formed by tire and rim.";
CM_ SG_ 3221225472 TirePress_12 "Pressure at which air is contained in cavity formed by tire and rim.";
CM_ SG_ 3221225472 TirePress_11 "Pressure at which air is contained in cavity formed by tire and rim.";
CM_ SG_ 3221225472 TirePress_10 "Pressure at which air is contained in cavity formed by tire and rim.";
CM_ SG_ 3221225472 TireAirLeakageRate_33 "The pressure loss rate of a tire.";
CM_ SG_ 3221225472 TireAirLeakageRate_32 "The pressure loss rate of a tire.";
CM_ SG_ 3221225472 TireAirLeakageRate_31 "The pressure loss rate of a tire.";
CM_ SG_ 3221225472 TireAirLeakageRate_30 "The pressure loss rate of a tire.";
CM_ SG_ 3221225472 TireAirLeakageRate_23 "The pressure loss rate of a tire.";
CM_ SG_ 3221225472 TireAirLeakageRate_22 "The pressure loss rate of a tire.";
CM_ SG_ 3221225472 TireAirLeakageRate_21 "The pressure loss rate of a tire.";
CM_ SG_ 3221225472 TireAirLeakageRate_20 "The pressure loss rate of a tire.";
CM_ SG_ 3221225472 TireAirLeakageRate_13 "The pressure loss rate of a tire.";
CM_ SG_ 3221225472 TireAirLeakageRate_12 "The pressure loss rate of a tire.";
CM_ SG_ 3221225472 TireAirLeakageRate_11 "The pressure loss rate of a tire.";
CM_ SG_ 3221225472 TireAirLeakageRate_10 "The pressure loss rate of a tire.";
CM_ SG_ 3221225472 TireAirLeakageRate_01 "The pressure loss rate of a tire.";
CM_ SG_ 3221225472 TireAirLeakageRate_00 "The pressure loss rate of a tire.";
CM_ SG_ 3221225472 CTIWheelSensorStatus_33 "Indicates whether the wheel is being monitored by the CTI controller.";
CM_ SG_ 3221225472 CTIWheelSensorStatus_32 "Indicates whether the wheel is being monitored by the CTI controller.";
CM_ SG_ 3221225472 CTIWheelSensorStatus_31 "Indicates whether the wheel is being monitored by the CTI controller.";
CM_ SG_ 3221225472 CTIWheelSensorStatus_30 "Indicates whether the wheel is being monitored by the CTI controller.";
CM_ SG_ 3221225472 CTIWheelSensorStatus_23 "Indicates whether the wheel is being monitored by the CTI controller.";
CM_ SG_ 3221225472 CTIWheelSensorStatus_22 "Indicates whether the wheel is being monitored by the CTI controller.";
CM_ SG_ 3221225472 CTIWheelSensorStatus_21 "Indicates whether the wheel is being monitored by the CTI controller.";
CM_ SG_ 3221225472 CTIWheelSensorStatus_20 "Indicates whether the wheel is being monitored by the CTI controller.";
CM_ SG_ 3221225472 CTIWheelSensorStatus_13 "Indicates whether the wheel is being monitored by the CTI controller.";
CM_ SG_ 3221225472 CTIWheelSensorStatus_12 "Indicates whether the wheel is being monitored by the CTI controller.";
CM_ SG_ 3221225472 CTIWheelSensorStatus_11 "Indicates whether the wheel is being monitored by the CTI controller.";
CM_ SG_ 3221225472 CTIWheelSensorStatus_10 "Indicates whether the wheel is being monitored by the CTI controller.";
CM_ SG_ 3221225472 CTIWheelSensorStatus_01 "Indicates whether the wheel is being monitored by the CTI controller.";
CM_ SG_ 3221225472 CTIWheelEndElectricalFault_33 "Indicates the status of electrical fault on CTI wheel interface.";
CM_ SG_ 3221225472 CTIWheelEndElectricalFault_32 "Indicates the status of electrical fault on CTI wheel interface.";
CM_ SG_ 3221225472 CTIWheelEndElectricalFault_31 "Indicates the status of electrical fault on CTI wheel interface.";
CM_ SG_ 3221225472 CTIWheelEndElectricalFault_30 "Indicates the status of electrical fault on CTI wheel interface.";
CM_ SG_ 3221225472 CTIWheelEndElectricalFault_23 "Indicates the status of electrical fault on CTI wheel interface.";
CM_ SG_ 3221225472 CTIWheelEndElectricalFault_22 "Indicates the status of electrical fault on CTI wheel interface.";
CM_ SG_ 3221225472 CTIWheelEndElectricalFault_21 "Indicates the status of electrical fault on CTI wheel interface.";
CM_ SG_ 3221225472 CTIWheelEndElectricalFault_20 "Indicates the status of electrical fault on CTI wheel interface.";
CM_ SG_ 3221225472 CTIWheelEndElectricalFault_13 "Indicates the status of electrical fault on CTI wheel interface.";
CM_ SG_ 3221225472 CTIWheelEndElectricalFault_12 "Indicates the status of electrical fault on CTI wheel interface.";
CM_ SG_ 3221225472 CTIWheelEndElectricalFault_11 "Indicates the status of electrical fault on CTI wheel interface.";
CM_ SG_ 3221225472 CTIWheelEndElectricalFault_10 "Indicates the status of electrical fault on CTI wheel interface.";
CM_ SG_ 3221225472 CTIWheelEndElectricalFault_01 "Indicates the status of electrical fault on CTI wheel interface.";
CM_ SG_ 3221225472 CTITireStatus_33 "Indicates the status of the tire.";
CM_ SG_ 3221225472 CTITireStatus_32 "Indicates the status of the tire.";
CM_ SG_ 3221225472 CTITireStatus_31 "Indicates the status of the tire.";
CM_ SG_ 3221225472 CTITireStatus_30 "Indicates the status of the tire.";
CM_ SG_ 3221225472 CTITireStatus_23 "Indicates the status of the tire.";
CM_ SG_ 3221225472 CTITireStatus_22 "Indicates the status of the tire.";
CM_ SG_ 3221225472 CTITireStatus_21 "Indicates the status of the tire.";
CM_ SG_ 3221225472 CTITireStatus_20 "Indicates the status of the tire.";
CM_ SG_ 3221225472 CTITireStatus_13 "Indicates the status of the tire.";
CM_ SG_ 3221225472 CTITireStatus_12 "Indicates the status of the tire.";
CM_ SG_ 3221225472 CTITireStatus_11 "Indicates the status of the tire.";
CM_ SG_ 3221225472 CTITireStatus_10 "Indicates the status of the tire.";
CM_ SG_ 3221225472 CTITireStatus_01 "Indicates the status of the tire.";
CM_ SG_ 3221225472 TireTemp_11 "Temperature at the surface of the tire sidewall.";
CM_ SG_ 3221225472 TireTemp_33 "Temperature at the surface of the tire sidewall.";
CM_ SG_ 3221225472 TireTemp_32 "Temperature at the surface of the tire sidewall.";
CM_ SG_ 3221225472 TireTemp_31 "Temperature at the surface of the tire sidewall.";
CM_ SG_ 3221225472 TireTemp_30 "Temperature at the surface of the tire sidewall.";
CM_ SG_ 3221225472 TireTemp_23 "Temperature at the surface of the tire sidewall.";
CM_ SG_ 3221225472 TireTemp_22 "Temperature at the surface of the tire sidewall.";
CM_ SG_ 3221225472 TireTemp_21 "Temperature at the surface of the tire sidewall.";
CM_ SG_ 3221225472 TireTemp_20 "Temperature at the surface of the tire sidewall.";
CM_ SG_ 3221225472 TireTemp_13 "Temperature at the surface of the tire sidewall.";
CM_ SG_ 3221225472 TireTemp_12 "Temperature at the surface of the tire sidewall.";
CM_ SG_ 3221225472 TireTemp_10 "Temperature at the surface of the tire sidewall.";
CM_ SG_ 3221225472 TireTemp_01 "Temperature at the surface of the tire sidewall.";
CM_ SG_ 3221225472 TireTemp_00 "Temperature at the surface of the tire sidewall.";
CM_ SG_ 3221225472 TirePressThresholdDetection_33 "Signal indicating the pressure level of the tire.";
CM_ SG_ 3221225472 TirePressThresholdDetection_32 "Signal indicating the pressure level of the tire.";
CM_ SG_ 3221225472 TirePressThresholdDetection_31 "Signal indicating the pressure level of the tire.";
CM_ SG_ 3221225472 TirePressThresholdDetection_30 "Signal indicating the pressure level of the tire.";
CM_ SG_ 3221225472 TirePressThresholdDetection_23 "Signal indicating the pressure level of the tire.";
CM_ SG_ 3221225472 TirePressThresholdDetection_22 "Signal indicating the pressure level of the tire.";
CM_ SG_ 3221225472 TirePressThresholdDetection_21 "Signal indicating the pressure level of the tire.";
CM_ SG_ 3221225472 TirePressThresholdDetection_20 "Signal indicating the pressure level of the tire.";
CM_ SG_ 3221225472 TirePressThresholdDetection_00 "Signal indicating the pressure level of the tire.";
CM_ SG_ 3221225472 TirePress_01 "Pressure at which air is contained in cavity formed by tire and rim.";
CM_ SG_ 3221225472 TirePress_00 "Pressure at which air is contained in cavity formed by tire and rim.";
CM_ SG_ 3221225472 CTIWheelSensorStatus_00 "Indicates whether the wheel is being monitored by the CTI controller.";
CM_ SG_ 3221225472 CTIWheelEndElectricalFault_00 "Indicates the status of electrical fault on CTI wheel interface.";
CM_ SG_ 3221225472 CTITireStatus_00 "Indicates the status of the tire.";
CM_ SG_ 3221225472 Longitude "Longitude position of the vehicle.";
CM_ SG_ 3221225472 Latitude "Latitude position of the vehicle.";
CM_ SG_ 3221225472 WaterInFuelIndicator "Signal which indicates the presence of water in the fuel.";
CM_ SG_ 3221225472 AuxPumpPress "Gage pressure of auxiliary water pump driven as a PTO device.";
CM_ SG_ 3221225472 EngBlowerBypassValvePos "Relative position of the blower bypass valve.";
CM_ SG_ 3221225472 EngGasSupplyPress "Gage pressure of gas supply to fuel metering device.";
CM_ SG_ 3221225472 FuelLevel2 "Ratio of volume of fuel to the total volume of fuel in the second or right-side storage container.";
CM_ SG_ 3221225472 FuelLevel1 "Ratio of volume of fuel to the total volume of fuel storage container.";
CM_ SG_ 3221225472 CargoAmbientTemp "Temperature of air inside vehicle container used to accommodate cargo.";
CM_ SG_ 3221225472 EngOilFilterDiffPress "Change in engine oil pressure, measured across the filter, due to the filter and any accumulation of solid or semisolid";
CM_ SG_ 3221225472 WasherFluidLevel "Ratio of volume of liquid to total container volume of fluid reservoir in windshield wash system.";
CM_ SG_ 3221225472 DrvlneRetarderOverheatIndicator "Signal from the driveline retarder indicating that its fluid temperature is above normal acceptable limits, and as a result,";
CM_ SG_ 3221225472 HydRetarderOilTemp "Temperature of oil found in a hydraulic retarder.";
CM_ SG_ 3221225472 HydRetarderPress "Gage pressure of oil in hydraulic retarder system.";
CM_ SG_ 3221225472 ParkingBrakeRedWarningSignal "This parameter commands the Parking Brake red optical warning signal.";
CM_ SG_ 3221225472 ParkBrakeReleaseInhibitStatus "This parameter provides reports on the status of the Park Brake Release Inhibit function.";
CM_ SG_ 3221225472 ParkingBrakeActuator "Signal which indicates the current state of the actuator(s) that control the parking brake (see also SPN 70).";
CM_ SG_ 3221225472 BrakeSecondPress "Gage pressure of air in the secondary, or service side, of the air brake system.";
CM_ SG_ 3221225472 BrakePrimaryPress "Gage pressure of air in the primary, or supply side, of the air brake system.";
CM_ SG_ 3221225472 BrakeAppPress "Gage pressure of compressed air or fluid in vehicle braking system measured at the brake chamber when brake shoe (or";
CM_ SG_ 3221225472 SteerAxleLubePress "The steering axle lubricant pressure.";
CM_ SG_ 3221225472 SteerAxleTemp "Temperature of lubricant in steering axle.";
CM_ SG_ 3221225472 DriveAxleLubePress "The drive axle lubricant pressure with location determined by Drive Axle Location (SPN 930).";
CM_ SG_ 3221225472 DriveAxleTemp "Temperature of axle lubricant in drive axle.";
CM_ SG_ 3221225472 DriveAxleLiftAirPress "Gage pressure of air in system that utilizes compressed air to provide force between axle and frame.";
CM_ SG_ 3221225472 DriveAxleLocation "To identify to which of several similar devices (such as tires or fuel tanks) the information applies.";
CM_ SG_ 3221225472 TransOilLevelMeasurementStatus "Indicates if conditions are acceptable to obtain a valid transmission oil level measurement as conveyed in SPN 124";
CM_ SG_ 3221225472 TransOilLevelCountdownTimer "Once all vehicle conditions (such as vehicle stopped, etc) are met, some transmissions may require a `settling time' to";
CM_ SG_ 3221225472 TransOilLevelHigh_Low "Amount of current volume of transmission sump oil compared to recommended volume.";
CM_ SG_ 3221225472 TransOilTemp "Temperature of the transmission lubricant.";
CM_ SG_ 3221225472 TransOilPress "Gage pressure of lubrication fluid in transmission, measured after pump.";
CM_ SG_ 3221225472 TransFilterDiffPress "Change in transmission fluid pressure, measured after the filter, due to accumulation of solid or semisolid material on or in";
CM_ SG_ 3221225472 TransOilLevel "Ratio of volume of transmission sump oil to recommended volume.";
CM_ SG_ 3221225472 ClutchPress "Gage pressure of oil within a wet clutch.";
CM_ SG_ 3221225472 ChargingSystemPotential "Electrical potential measured at the charging system output.";
CM_ SG_ 3221225472 AltCurrent "Measure of electrical current flow from the alternator.";
CM_ SG_ 3221225472 NetBatteryCurrent "Net flow of electrical current into/out of the battery or batteries.";
CM_ SG_ 3221225472 KeyswitchBatteryPotential "Battery potential measured at the input of the electronic control unit supplied through a keyswitch or similar switching";
CM_ SG_ 3221225472 BatteryPotential_PowerInput1 "This parameter measures the first source of battery potential as measured at the input of the ECM/actuator etc.";
CM_ BO_ 2566749438 "Diesel Particulate Filter Control 1";
CM_ SG_ 2566749438 DslPrtcltFltrActvRgnrtnFrcdStts "Indicates the forced execution status of diesel particulate filter regeneration.";
CM_ SG_ 2566749438 ExhaustSystemHighTempLampCmd "Command to control the exhaust system high temperature lamp.";
CM_ SG_ 2566749438 DslPrtcltFltrAtmtcActvRgnrtnIntt "Indicates the configuration of diesel particulate filter active regeneration automatic initiation.";
CM_ SG_ 2566749438 DslPrtcltFltrActvRgnrtnInhbtdDTV "Speed";
CM_ SG_ 2566749438 DslPrtcltFltrActvRgnrtnInhbtdDTE "Indicates the state of diesel particulate filter active regeneration inhibition due to the engine not being warmed up.";
CM_ SG_ 2566749438 DslPrtcltFltrActvRgnrtnInhbtdDTP "Indicates the state of diesel particulate filter active regeneration inhibition due to a permanent system lockout.";
CM_ SG_ 2566749438 DslPrtcltFltrActvRgnrtnInhbtdDTT "Indicates the state of diesel particulate filter active regeneration inhibition due to a temporary system lockout.";
CM_ SG_ 2566749438 DslPrtcltFltrActvRgnrtnInhbtdDTS "Indicates the state of diesel particulate filter active regeneration inhibition due to a system timeout.";
CM_ SG_ 2566749438 DslPrtcltFltrActvRgnrtnInhb_0000 "Indicates the state of diesel particulate filter active regeneration inhibition due to a system fault being active.";
CM_ SG_ 2566749438 DslPrtcltFltrActvRgnrtnInhbtdDTL "Indicates the state of diesel particulate filter active regeneration inhibition due to the exhaust gas temperature being too";
CM_ SG_ 2566749438 DslPrtcltFltrActvRgnrtnInhb_0001 "Indicates the state of diesel particulate filter active regeneration inhibition due to the parking brake being not set.";
CM_ SG_ 2566749438 DslPrtcltFltrActvRgnrtnInhb_0002 "Speed";
CM_ SG_ 2566749438 DslPrtcltFltrActvRgnrtnInhbtdDTO "Indicates the state of diesel particulate filter active regeneration inhibition due to the transmission being out of neutral.";
CM_ SG_ 2566749438 DslPrtcltFltrActvRgnrtnInhbtdDTA "Indicates the state of diesel particulate filter active regeneration inhibition due to the accelerator pedal being off idle.";
CM_ SG_ 2566749438 DslPrtcltFltrActvRgnrtnInhb_0003 "Indicates the state of diesel particulate filter active regeneration inhibition due to the PTO being active.";
CM_ SG_ 2566749438 DslPrtcltFltrActvRgnrtnInhb_0004 "Indicates the state of diesel particulate filter active regeneration inhibition due to the service brake being active.";
CM_ SG_ 2566749438 DslPrtcltFltrActvRgnrtnInhbtdDTC "Indicates the state of diesel particulate filter active regeneration inhibition due to the clutch being disengaged.";
CM_ SG_ 2566749438 DslPrtcltFltrActvRgnrtnInhbtdDTI "Indicates the state of diesel particulate filter active regeneration inhibition due to the Diesel Particulate Filter Regeneration";
CM_ SG_ 2566749438 DslPrtcltFltrActvRgnrtnInhbtdStt "Indicates the state of diesel particulate filter active regeneration inhibition.";
CM_ SG_ 2566749438 DieselParticulateFilterStatus "Indicates the state of the diesel particulate filter regeneration need and urgency.";
CM_ SG_ 2566749438 DslPrtcltFltrActvRgnrtionStatus "Indicates the state of diesel particulate filter active regeneration.";
CM_ SG_ 2566749438 DslPrtcltFltrPssvRgnrtionStatus "Indicates the state of diesel particulate filter passive regeneration.";
CM_ SG_ 2566749438 DieselParticulateFilterLampCmd "Command to control the diesel particulate filter lamp.";
CM_ BO_ 2566846206 "Intake/Exhaust Conditions 1";
CM_ SG_ 2566846206 EngCoolantFilterDiffPress "Change in coolant pressure, measured across the filter, due to the filter and any accumulation of solid or semisolid matter";
CM_ SG_ 2566846206 EngExhaustGasTemp "Temperature of combustion byproducts leaving the engine.";
CM_ SG_ 2566846206 EngAirFilter1DiffPress "Change in engine air system pressure, measured across the filter, due to the filter and any accumulation of solid foreign";
CM_ SG_ 2566846206 EngIntakeManifold1Temp "Temperature of pre-combustion air found in intake manifold of engine air supply system.";
CM_ SG_ 2566846206 EngIntakeManifold1Press "The gage pressure measurement of the air intake manifold.";
CM_ SG_ 2566846206 EngDslPrtclateFilterIntakePress "Exhaust back pressure as a result of particle accumulation on filter media placed in the exhaust stream.";
CM_ SG_ 2566846206 EngAirIntakePress "Absolute air pressure at input port to intake manifold or air box.";
CM_ BO_ 2566845182 "Fuel Economy (Liquid)";
CM_ SG_ 2566845182 EngAverageFuelEconomy "Average of instantaneous fuel economy for that segment of vehicle operation of interest.";
CM_ SG_ 2566845182 EngInstantaneousFuelEconomy "Current fuel economy at current vehicle velocity.";
CM_ SG_ 2566845182 EngFuelRate "Amount of fuel consumed by engine per unit of time.";
CM_ SG_ 2566845182 EngThrottleValve2Pos "The sensed position feedback of the valve, coming from a second electrical actuator for a second throttle plate, used to";
CM_ SG_ 2566845182 EngThrottleValve1Pos "The position of the valve used to regulate the supply of a fluid, usually air or fuel/air mixture, to an engine.";
CM_ BO_ 2633929470 "Engine Information";
CM_ SG_ 2633929470 EngFuelRackPos "Measured position of the engine fuel rack.";
CM_ SG_ 2633929470 EngGasMassFlowRate1 "Gas mass flow rate delivered to an engine through its first fuel control system.";
CM_ SG_ 2633929470 InstantaneousEstBrakePower "Estimate of the power developed by the engine.";
CM_ SG_ 2633929470 EngExhaustGasPress "Gage pressure of the exhaust gasses as measured at the turbine intake of the turbocharger.";
CM_ SG_ 2633929470 EngPrefilterOilPress "Gage pressure of the engine oil before the oil reaches the oil filter.";
CM_ BO_ 2364541694 "Engine Gas Flow Rate";
CM_ SG_ 2364541694 EngIntakeAirMassFlowRate "Mass flow rate of fresh air entering the engine air intake, before any EGR mixer, if used.";
CM_ SG_ 2364541694 EngExhstGsRcrclton2MassFlowRate "Flow rate of gas through the second EGR system.";
CM_ SG_ 2364541694 EngExhstGsRcrclton1MassFlowRate "Flow rate of gas through the EGR system.";
CM_ BO_ 2566840318 "Electronic Engine Controller 3";
CM_ SG_ 2566840318 EngsDsrdOprtngSpdAsymmtryAdjstmn "This byte is utilized in transmission gear selection routines and indicates the engine's preference of lower versus higher";
CM_ SG_ 2566840318 Aftrtratment1ExhaustGasMassFlow "Measured/calculated exhaust gas mass upstream of the aftertreatment system in exhaust bank 1 and 2.";
CM_ SG_ 2566840318 Aftertreatment2IntakeDewPoint "Indicates that the temperature on the intake side of the aftertreatment system has exceeded the dew point, as estimated";
CM_ SG_ 2566840318 Aftertreatment2ExhaustDewPoint "Indicates that the temperature on the exhaust side of the aftertreatment has exceeded the dew point, as estimated by the";
CM_ SG_ 2566840318 Aftertreatment1IntakeDewPoint "Indicates that the temperature on the intake side of the aftertreatment system has exceeded the dew point, as estimated";
CM_ SG_ 2566840318 Aftertreatment1ExhaustDewPoint "Indicates that the temperature on the exhaust side of the aftertreatment has exceeded the dew point, as estimated by the";
CM_ SG_ 2566840318 EstEngPrsticLossesPercentTorque "The calculated torque that indicates the estimated amount of torque loss due to engine parasitics, such as cooling fan, air";
CM_ SG_ 2566840318 EngsDesiredOperatingSpeed "An indication by the engine of the optimal operating speed of the engine for the current existing conditions.";
CM_ SG_ 2566840318 NominalFrictionPercentTorque "The calculated torque that indicates the amount of torque required by the basic engine itself added by the loss torque of";
CM_ BO_ 2364539902 "Electronic Engine Controller 2";
CM_ SG_ 2364539902 SCRThermalManagementActive "Indicates that the exhaust temperatures have been elevated for regeneration of the SCR aftertreatment system or in";
CM_ SG_ 2364539902 MmntryEngMaxPowerEnableFeedback "Momentarily requesting Engine Maximum Power Enable - feature support feedback";
CM_ SG_ 2364539902 EstPumpingPercentTorque "The calculated torque that indicates the estimated amount of torque loss due to the engine air handling system.";
CM_ SG_ 2364539902 DPFThermalManagementActive "Indicates that the exhaust temperatures have been elevated for regeneration of the diesel particulate filter aftertreatment";
CM_ SG_ 2364539902 ActlMxAvailableEngPercentTorque "This is the maximum amount of torque that the engine can immediately deliver as a percentage of the reference engine";
CM_ SG_ 2364539902 AccelPedalPos2 "The ratio of actual position of the second analog engine speed/torque request input device (such as an accelerator pedal";
CM_ SG_ 2364539902 VhclAccelerationRateLimitStatus "Status (active or not active) of the system used to limit maximum forward vehicle acceleration.";
CM_ SG_ 2364539902 EngPercentLoadAtCurrentSpeed "The ratio of actual engine percent torque (indicated) to maximum indicated torque available at the current engine speed,";
CM_ SG_ 2364539902 AccelPedal2LowIdleSwitch "Switch signal which indicates the state of the accelerator pedal 2 low idle switch.";
CM_ SG_ 2364539902 RoadSpeedLimitStatus "Status (active or not active) of the system used to limit maximum vehicle velocity.";
CM_ SG_ 2364539902 AccelPedalKickdownSwitch "Switch signal which indicates whether the accelerator pedal kickdown switch is opened or closed.";
CM_ SG_ 2364539902 AccelPedal1LowIdleSwitch "Switch signal which indicates the state of the accelerator pedal 1 low idle switch.";
CM_ SG_ 2364539902 RemoteAccelPedalPos "The ratio of actual position of the remote analog engine speed/torque request input device (such as an accelerator pedal";
CM_ SG_ 2364539902 AccelPedalPos1 "The ratio of actual position of the analog engine speed/torque request input device (such as an accelerator pedal or";
CM_ BO_ 2364540158 "Electronic Engine Controller 1";
CM_ SG_ 2364540158 SrcAddrssOfCtrllngDvcFrEngCntrl "The source address of the SAE J1939 device currently controlling the engine.";
CM_ SG_ 2364540158 ActlEngPrcntTrqueHighResolution "This parameter displays an additional torque in percent of the reference engine torque.";
CM_ SG_ 2364540158 EngDemandPercentTorque "The requested torque output of the engine by all dynamic internal inputs, including smoke control, noise control and low";
CM_ SG_ 2364540158 EngStarterMode "There are several phases in a starting action and different reasons why a start cannot take place.";
CM_ SG_ 2364540158 EngSpeed "Actual engine speed which is calculated over a minimum crankshaft angle of 720 degrees divided by the number of cylinders.";
CM_ SG_ 2364540158 ActualEngPercentTorque "The calculated output torque of the engine.";
CM_ SG_ 2364540158 DriversDemandEngPercentTorque "The requested torque output of the engine by the driver.";
CM_ SG_ 2364540158 EngTorqueMode "State signal which indicates which engine torque mode is currently generating, limiting, or controlling the torque.";
CM_ BO_ 2566841342 "Engine Configuration 1";
CM_ SG_ 2566841342 SupportTSC1CtrlPurposeGroup4 "This parameter indicates which TSC1 control purposes are supported in group 4 of 4.";
CM_ SG_ 2566841342 SupportTSC1CtrlPurposeGroup3 "This parameter indicates which TSC1 control purposes are supported in group 3 of 4.";
CM_ SG_ 2566841342 SupportTSC1CtrlPurposeGroup2 "This parameter indicates which TSC1 control purposes are supported in group 2 of 4.";
CM_ SG_ 2566841342 SupportTSC1CtrlPurposeGroup1 "This parameter indicates which TSC1 control purposes are supported in group 1 of 4.";
CM_ SG_ 2566841342 SupportVariableRateTSC1Message "This parameter indicates which TSC1 transmission rates are supported by the engine ECU in addition to the required";
CM_ SG_ 2566841342 EngDefaultTorqueLimit "Companion parameter to Transmission Torque Limit (SPN 1845).";
CM_ SG_ 2566841342 EngMomentOfInertia "Moment of inertia for the engine, including items driven full-time by the engine such as fuel, oil and cooling pumps.";
CM_ SG_ 2566841342 EngExRngRqdSpdCtrlRngUpperLimit "The maximum engine speed regardless of load that the engine will allow when operating in a speed control/limit mode,";
CM_ SG_ 2566841342 EngRqdTorqueCtrlRangeUpperLimit "The maximum engine torque that the engine will allow when operating in a torque control/limit mode.";
CM_ SG_ 2566841342 EngRqdTorqueCtrlRangeLowerLimit "The minimum engine torque that the engine will allow when operating in a torque control/limit mode.";
CM_ SG_ 2566841342 EngRqedSpeedCtrlRangeUpperLimit "The maximum engine speed regardless of load that the engine will allow when operating in a speed control/limit mode,";
CM_ SG_ 2566841342 EngRqedSpeedCtrlRangeLowerLimit "The minimum engine speed that the engine will allow when operating in a speed control/limit mode.";
CM_ SG_ 2566841342 EngMxMomentaryOverrideTimeLimit "The maximum time limit allowed to override the engine's high idle speed.";
CM_ SG_ 2566841342 EngMxMmntaryOverrideSpeedPoint7 "The maximum engine speed above high idle allowed by the engine control during a momentary high idle override.";
CM_ SG_ 2566841342 EngReferenceTorque "This parameter is the 100% reference value for all defined indicated engine torque parameters.";
CM_ SG_ 2566841342 EngSpeedAtHighIdlePoint6 "Engine speed of high idle (point 6) of the engine torque map (see PGN 65251 and supporting document).";
CM_ SG_ 2566841342 EngGainOfEndspeedGovernor "The endspeed governor is defined as a linear line with the following equations (Capital letters mean physical values, small";
CM_ SG_ 2566841342 EngPercentTorqueAtPoint5 "The torque limit that indicates the available engine torque which can be provided by the engine at point 3, 4, and 5 of the";
CM_ SG_ 2566841342 EngSpeedAtPoint5 "Engine speed of point 3, 4, and 5 of the engine torque map (see PGN 65251 and supporting document).";
CM_ SG_ 2566841342 EngPercentTorqueAtPoint4 "The torque limit that indicates the available engine torque which can be provided by the engine at point 3, 4, and 5 of the";
CM_ SG_ 2566841342 EngSpeedAtPoint4 "Engine speed of point 3, 4, and 5 of the engine torque map (see PGN 65251 and supporting document).";
CM_ SG_ 2566841342 EngPercentTorqueAtPoint3 "The torque limit that indicates the available engine torque which can be provided by the engine at point 3, 4, and 5 of the";
CM_ SG_ 2566841342 EngSpeedAtPoint3 "Engine speed of point 3, 4, and 5 of the engine torque map (see PGN 65251 and supporting document).";
CM_ SG_ 2566841342 EngPercentTorqueAtPoint2 "The torque limit that indicates the available engine torque which can be provided by the engine at point 2 of the engine";
CM_ SG_ 2566841342 EngSpeedAtPoint2 "Engine speed of point 2 of the engine torque map (see PGN 65251 and supporting document).";
CM_ SG_ 2566841342 EngPercentTorqueAtIdlePoint1 "The torque limit that indicates the available engine torque which can be provided by the engine at idle speed.";
CM_ SG_ 2566841342 EngSpeedAtIdlePoint1 "Stationary low idle speed of engine which includes influences due to engine temperature (after power up) and other";
CM_ BO_ 2566844926 "Cruise Control/Vehicle Speed";
CM_ SG_ 2566844926 ParkBrakeReleaseInhibitRq "Park Brake Release Inhibit Request signals the desire that an applied park brake remain applied and limit the ability of the";
CM_ SG_ 2566844926 PTOGovernorState "This parameter is used to indicate the current state or mode of operation by the power takeoff (PTO) governor.";
CM_ SG_ 2566844926 EngShutdownOverrideSwitch "Switch signal which indicates the position of the engine shutdown override switch.";
CM_ SG_ 2566844926 EngTestModeSwitch "Switch signal which indicates the position of the engine test mode switch.";
CM_ SG_ 2566844926 EngIdleDecrementSwitch "Switch signal which indicates the position of the idle decrement switch.";
CM_ SG_ 2566844926 EngIdleIncrementSwitch "Switch signal which indicates the position of the idle increment switch.";
CM_ SG_ 2566844926 CruiseCtrlStates "This parameter is used to indicate the current state, or mode, of operation by the cruise control device.";
CM_ SG_ 2566844926 CruiseCtrlSetSpeed "Value of set (chosen) velocity of velocity control system.";
CM_ SG_ 2566844926 CruiseCtrlAccelerateSwitch "Switch signal of the cruise control activator which indicates that the activator is in the position [accelerate.";
CM_ SG_ 2566844926 CruiseCtrlResumeSwitch "Switch signal of the cruise control activator which indicates that the activator is in the position [resume.";
CM_ SG_ 2566844926 CruiseCtrlCoastSwitch "Switch signal of the cruise control activator which indicates that the activator is in the position [coast (decelerate).";
CM_ SG_ 2566844926 CruiseCtrlSetSwitch "Switch signal of the cruise control activator which indicates that the activator is in the position [set.";
CM_ SG_ 2566844926 ClutchSwitch "Switch signal which indicates that the clutch pedal is being pressed.";
CM_ SG_ 2566844926 BrakeSwitch "Switch signal which indicates that the driver operated brake foot pedal is being pressed.";
CM_ SG_ 2566844926 CruiseCtrlEnableSwitch "Switch signal which indicates that it is possible to manage the cruise control function.";
CM_ SG_ 2566844926 CruiseCtrlActive "Cruise control is switched on.";
CM_ SG_ 2566844926 WheelBasedVehicleSpeed "Speed of the vehicle as calculated from wheel or tailshaft speed.";
CM_ SG_ 2566844926 CruiseCtrlPauseSwitch "Switch signal which indicates the position of the Cruise Control Pause Switch used on Remote Cruise Control applications.";
CM_ SG_ 2566844926 ParkingBrakeSwitch "Switch signal which indicates when the parking brake is set.";
CM_ SG_ 2566844926 TwoSpeedAxleSwitch "Switch signal which indicates the current axle range.";
CM_ BO_ 2566763774 "Aftertreatment 1 Intake Gas 2";
CM_ SG_ 2566763774 Aftrtrtmnt1DslPrtcltFltrIntkGsTm "Used to identify the applicable J1939-73 FMI detected in the diesel particulate filter intake gas temperature sensor by the";
CM_ SG_ 2566763774 Aftrtrtmnt1ExhstGsTmp1PrlmnryFMI "Used to identify the applicable J1939-73 FMI detected in the exhaust gas temperature 1 sensor by the manufacturer's";
CM_ SG_ 2566763774 Aftertreatment1ExhaustGasTemp1 "The reading from the exhaust gas temperature sensor located farthest upstream in the aftertreatment system in exhaust bank 1.";
CM_ SG_ 2566763774 Aftrtrtmnt1DslPrtcltFltrInt_0000 "Temperature of engine combustion byproducts entering the diesel particulate filter in exhaust bank 1.";
CM_ BO_ 2566763262 "Aftertreatment 1 Intermediate Gas";
CM_ SG_ 2566763262 Aftrtrtmnt1DslPrtcltFltrIntrmdtG "Used to identify the applicable J1939-73 FMI detected in the diesel particulate filter intermediate gas temperature sensor";
CM_ SG_ 2566763262 Aftrtrtmnt1DslPrtcltFltrInt_0001 "Temperature of engine combustion byproducts at a mid-point in the diesel particulate filter in exhaust bank 1.";
CM_ SG_ 2566763262 Aftrtrtmnt1DslPrtcltFltrDltPrssP "Used to identify the applicable J1939-73 FMI detected in the diesel particulate filter differential pressure sensor by the";
CM_ SG_ 2566763262 Aftrtrtmnt1DslPrtcltFltrDffPrss "Exhaust differential pressure measured between the intake and exhaust of a diesel particulate filter in exhaust bank 1.";
CM_ SG_ 2566763262 Aftrtrtmnt1ExhstGsTmp2PrlmnryFMI "Used to identify the applicable J1939-73 FMI detected in the exhaust gas temperature 2 sensor by the manufacturer's sensor";
CM_ SG_ 2566763262 Aftertreatment1ExhaustGasTemp2 "The reading from the exhaust gas temperature sensor located midstream of the other two temperature sensors in the";
CM_ BO_ 2566763518 "Aftertreatment 1 Outlet Gas 2";
CM_ SG_ 2566763518 Aftrtrtmnt1DslPrtcltFltrOtltGsTm "Temperature of engine combustion byproducts leaving the diesel particulate filter exhaust in exhaust bank 1.";
CM_ SG_ 2566763518 Aftrtrtmnt1DslPrtcltFltrOtltExhs "Used to identify the applicable J1939-73 FMI detected in the diesel particulate filter outlet gas temperature sensor by the";
CM_ SG_ 2566763518 Aftrtrtmnt1ExhstGsTmp3PrlmnryFMI "Used to identify the applicable J1939-73 FMI detected in the exhaust gas temperature 3 sensor by the manufacturer's";
CM_ SG_ 2566763518 Aftertreatment1ExhaustGasTemp3 "The reading from the exhaust gas temperature sensor located farthest downstream in the aftertreatment system in";
BA_DEF_ SG_  "SigType" ENUM  "Default","Range","RangeSigned","ASCII","Discrete","Control","ReferencePGN","DTC","StringDelimiter","StringLength","StringLengthControl";
BA_DEF_ SG_  "GenSigSendType" ENUM  "Cyclic","OnWrite","reserved","OnChange","reserved","reserved","reserved","NoSigSendType";
BA_DEF_ SG_  "GenSigILSupport" ENUM  "Yes","No";
BA_DEF_ SG_  "GenSigEVName" STRING ;
BA_DEF_ SG_  "SPN" INT 0 524287;
BA_DEF_ BO_  "GenMsgILSupport" ENUM  "Yes","No";
BA_DEF_ BO_  "GenMsgRequestable" INT 0 1;
BA_DEF_ BO_  "GenMsgSendType" ENUM  "cyclic","reserved","cyclicIfActive","reserved","reserved","reserved","reserved","reserved","noMsgSendType";
BA_DEF_ BO_  "VFrameFormat" ENUM  "StandardCAN","ExtendedCAN","reserved","J1939PG";
BA_DEF_ BO_  "GenMsgCycleTime" INT 0 3600000;
BA_DEF_ SG_  "SystemSignalLongSymbol" STRING ;
BA_DEF_DEF_  "SigType" "Default";
BA_DEF_DEF_  "GenSigSendType" "NoSigSendType";
BA_DEF_DEF_  "GenSigILSupport" "Yes";
BA_DEF_DEF_  "GenSigEVName" "Env@Nodename_@Signame";
BA_DEF_DEF_  "SPN" 0;
BA_DEF_DEF_  "GenMsgILSupport" "Yes";
BA_DEF_DEF_  "GenMsgRequestable" 1;
BA_DEF_DEF_  "GenMsgSendType" "noMsgSendType";
BA_DEF_DEF_  "VFrameFormat" "J1939PG";
BA_DEF_DEF_  "GenMsgCycleTime" 0;
BA_DEF_DEF_  "SystemSignalLongSymbol" "";
BA_ "SPN" SG_ 2566749438 DslPrtcltFltrActvRgnrtnFrcdStts 4175;
BA_ "SigType" SG_ 2566749438 DslPrtcltFltrActvRgnrtnFrcdStts 4;
BA_ "SPN" SG_ 2566749438 ExhaustSystemHighTempLampCmd 3698;
BA_ "SigType" SG_ 2566749438 ExhaustSystemHighTempLampCmd 4;
BA_ "SPN" SG_ 2566749438 DslPrtcltFltrAtmtcActvRgnrtnIntt 3718;
BA_ "SigType" SG_ 2566749438 DslPrtcltFltrAtmtcActvRgnrtnIntt 4;
BA_ "SystemSignalLongSymbol" SG_ 2566749438 DslPrtcltFltrAtmtcActvRgnrtnIntt "DslPrtcltFltrAtmtcActvRgnrtnInttnCnfg";
BA_ "SPN" SG_ 2566749438 DslPrtcltFltrActvRgnrtnInhbtdDTV 3717;
BA_ "SigType" SG_ 2566749438 DslPrtcltFltrActvRgnrtnInhbtdDTV 4;
BA_ "SystemSignalLongSymbol" SG_ 2566749438 DslPrtcltFltrActvRgnrtnInhbtdDTV "DslPrtcltFltrActvRgnrtnInhbtdDTVhclSpdBlwAllwd";
BA_ "SPN" SG_ 2566749438 DslPrtcltFltrActvRgnrtnInhbtdDTE 3716;
BA_ "SigType" SG_ 2566749438 DslPrtcltFltrActvRgnrtnInhbtdDTE 4;
BA_ "SystemSignalLongSymbol" SG_ 2566749438 DslPrtcltFltrActvRgnrtnInhbtdDTE "DslPrtcltFltrActvRgnrtnInhbtdDTEngNtWrmdUp";
BA_ "SPN" SG_ 2566749438 DslPrtcltFltrActvRgnrtnInhbtdDTP 3715;
BA_ "SigType" SG_ 2566749438 DslPrtcltFltrActvRgnrtnInhbtdDTP 4;
BA_ "SystemSignalLongSymbol" SG_ 2566749438 DslPrtcltFltrActvRgnrtnInhbtdDTP "DslPrtcltFltrActvRgnrtnInhbtdDTPrmnntSystmLckt";
BA_ "SPN" SG_ 2566749438 DslPrtcltFltrActvRgnrtnInhbtdDTT 3714;
BA_ "SigType" SG_ 2566749438 DslPrtcltFltrActvRgnrtnInhbtdDTT 4;
BA_ "SystemSignalLongSymbol" SG_ 2566749438 DslPrtcltFltrActvRgnrtnInhbtdDTT "DslPrtcltFltrActvRgnrtnInhbtdDTTmprrySystmLckt";
BA_ "SPN" SG_ 2566749438 DslPrtcltFltrActvRgnrtnInhbtdDTS 3713;
BA_ "SigType" SG_ 2566749438 DslPrtcltFltrActvRgnrtnInhbtdDTS 4;
BA_ "SystemSignalLongSymbol" SG_ 2566749438 DslPrtcltFltrActvRgnrtnInhbtdDTS "DslPrtcltFltrActvRgnrtnInhbtdDTSystmTmt";
BA_ "SPN" SG_ 2566749438 DslPrtcltFltrActvRgnrtnInhb_0000 3712;
BA_ "SigType" SG_ 2566749438 DslPrtcltFltrActvRgnrtnInhb_0000 4;
BA_ "SystemSignalLongSymbol" SG_ 2566749438 DslPrtcltFltrActvRgnrtnInhb_0000 "DslPrtcltFltrActvRgnrtnInhbtdDTSystmFltActv";
BA_ "SPN" SG_ 2566749438 DslPrtcltFltrActvRgnrtnInhbtdDTL 3711;
BA_ "SigType" SG_ 2566749438 DslPrtcltFltrActvRgnrtnInhbtdDTL 4;
BA_ "SystemSignalLongSymbol" SG_ 2566749438 DslPrtcltFltrActvRgnrtnInhbtdDTL "DslPrtcltFltrActvRgnrtnInhbtdDTLwExhstGsTmp";
BA_ "SPN" SG_ 2566749438 DslPrtcltFltrActvRgnrtnInhb_0001 3710;
BA_ "SigType" SG_ 2566749438 DslPrtcltFltrActvRgnrtnInhb_0001 4;
BA_ "SystemSignalLongSymbol" SG_ 2566749438 DslPrtcltFltrActvRgnrtnInhb_0001 "DslPrtcltFltrActvRgnrtnInhbtdDTPrkngBrkNtSt";
BA_ "SPN" SG_ 2566749438 DslPrtcltFltrActvRgnrtnInhb_0002 3709;
BA_ "SigType" SG_ 2566749438 DslPrtcltFltrActvRgnrtnInhb_0002 4;
BA_ "SystemSignalLongSymbol" SG_ 2566749438 DslPrtcltFltrActvRgnrtnInhb_0002 "DslPrtcltFltrActvRgnrtnInhbtdDTVhclSpdAbvAllwd";
BA_ "SPN" SG_ 2566749438 DslPrtcltFltrActvRgnrtnInhbtdDTO 3708;
BA_ "SigType" SG_ 2566749438 DslPrtcltFltrActvRgnrtnInhbtdDTO 4;
BA_ "SystemSignalLongSymbol" SG_ 2566749438 DslPrtcltFltrActvRgnrtnInhbtdDTO "DslPrtcltFltrActvRgnrtnInhbtdDTOtOfNtrl";
BA_ "SPN" SG_ 2566749438 DslPrtcltFltrActvRgnrtnInhbtdDTA 3707;
BA_ "SigType" SG_ 2566749438 DslPrtcltFltrActvRgnrtnInhbtdDTA 4;
BA_ "SystemSignalLongSymbol" SG_ 2566749438 DslPrtcltFltrActvRgnrtnInhbtdDTA "DslPrtcltFltrActvRgnrtnInhbtdDTAcclPdlOffIdl";
BA_ "SPN" SG_ 2566749438 DslPrtcltFltrActvRgnrtnInhb_0003 3706;
BA_ "SigType" SG_ 2566749438 DslPrtcltFltrActvRgnrtnInhb_0003 4;
BA_ "SystemSignalLongSymbol" SG_ 2566749438 DslPrtcltFltrActvRgnrtnInhb_0003 "DslPrtcltFltrActvRgnrtnInhbtdDTPTOActv";
BA_ "SPN" SG_ 2566749438 DslPrtcltFltrActvRgnrtnInhb_0004 3705;
BA_ "SigType" SG_ 2566749438 DslPrtcltFltrActvRgnrtnInhb_0004 4;
BA_ "SystemSignalLongSymbol" SG_ 2566749438 DslPrtcltFltrActvRgnrtnInhb_0004 "DslPrtcltFltrActvRgnrtnInhbtdDTSrvcBrkActv";
BA_ "SPN" SG_ 2566749438 DslPrtcltFltrActvRgnrtnInhbtdDTC 3704;
BA_ "SigType" SG_ 2566749438 DslPrtcltFltrActvRgnrtnInhbtdDTC 4;
BA_ "SystemSignalLongSymbol" SG_ 2566749438 DslPrtcltFltrActvRgnrtnInhbtdDTC "DslPrtcltFltrActvRgnrtnInhbtdDTCltchDsnggd";
BA_ "SPN" SG_ 2566749438 DslPrtcltFltrActvRgnrtnInhbtdDTI 3703;
BA_ "SigType" SG_ 2566749438 DslPrtcltFltrActvRgnrtnInhbtdDTI 4;
BA_ "SystemSignalLongSymbol" SG_ 2566749438 DslPrtcltFltrActvRgnrtnInhbtdDTI "DslPrtcltFltrActvRgnrtnInhbtdDTInhbtSwtch";
BA_ "SPN" SG_ 2566749438 DslPrtcltFltrActvRgnrtnInhbtdStt 3702;
BA_ "SigType" SG_ 2566749438 DslPrtcltFltrActvRgnrtnInhbtdStt 4;
BA_ "SystemSignalLongSymbol" SG_ 2566749438 DslPrtcltFltrActvRgnrtnInhbtdStt "DslPrtcltFltrActvRgnrtnInhbtdStts";
BA_ "SPN" SG_ 2566749438 DieselParticulateFilterStatus 3701;
BA_ "SigType" SG_ 2566749438 DieselParticulateFilterStatus 4;
BA_ "SPN" SG_ 2566749438 DslPrtcltFltrActvRgnrtionStatus 3700;
BA_ "SigType" SG_ 2566749438 DslPrtcltFltrActvRgnrtionStatus 4;
BA_ "SPN" SG_ 2566749438 DslPrtcltFltrPssvRgnrtionStatus 3699;
BA_ "SigType" SG_ 2566749438 DslPrtcltFltrPssvRgnrtionStatus 4;
BA_ "SPN" SG_ 2566749438 DieselParticulateFilterLampCmd 3697;
BA_ "SigType" SG_ 2566749438 DieselParticulateFilterLampCmd 4;
BA_ "GenMsgCycleTime" BO_ 2566846206 500;
BA_ "GenMsgSendType" BO_ 2566846206 0;
BA_ "SPN" SG_ 2566846206 EngCoolantFilterDiffPress 112;
BA_ "SigType" SG_ 2566846206 EngCoolantFilterDiffPress 1;
BA_ "SPN" SG_ 2566846206 EngExhaustGasTemp 173;
BA_ "SigType" SG_ 2566846206 EngExhaustGasTemp 1;
BA_ "SPN" SG_ 2566846206 EngAirFilter1DiffPress 107;
BA_ "SigType" SG_ 2566846206 EngAirFilter1DiffPress 1;
BA_ "SPN" SG_ 2566846206 EngIntakeManifold1Temp 105;
BA_ "SigType" SG_ 2566846206 EngIntakeManifold1Temp 1;
BA_ "SPN" SG_ 2566846206 EngIntakeManifold1Press 102;
BA_ "SigType" SG_ 2566846206 EngIntakeManifold1Press 1;
BA_ "SPN" SG_ 2566846206 EngDslPrtclateFilterIntakePress 81;
BA_ "SigType" SG_ 2566846206 EngDslPrtclateFilterIntakePress 1;
BA_ "SPN" SG_ 2566846206 EngAirIntakePress 106;
BA_ "SigType" SG_ 2566846206 EngAirIntakePress 1;
BA_ "GenMsgCycleTime" BO_ 2566845182 100;
BA_ "GenMsgSendType" BO_ 2566845182 0;
BA_ "SPN" SG_ 2566845182 EngAverageFuelEconomy 185;
BA_ "SigType" SG_ 2566845182 EngAverageFuelEconomy 1;
BA_ "SPN" SG_ 2566845182 EngInstantaneousFuelEconomy 184;
BA_ "SigType" SG_ 2566845182 EngInstantaneousFuelEconomy 1;
BA_ "SPN" SG_ 2566845182 EngFuelRate 183;
BA_ "SigType" SG_ 2566845182 EngFuelRate 1;
BA_ "SPN" SG_ 2566845182 EngThrottleValve2Pos 3673;
BA_ "SigType" SG_ 2566845182 EngThrottleValve2Pos 1;
BA_ "SPN" SG_ 2566845182 EngThrottleValve1Pos 51;
BA_ "SigType" SG_ 2566845182 EngThrottleValve1Pos 1;
BA_ "GenMsgCycleTime" BO_ 2633929470 100;
BA_ "GenMsgSendType" BO_ 2633929470 0;
BA_ "SPN" SG_ 2633929470 EngFuelRackPos 1210;
BA_ "SigType" SG_ 2633929470 EngFuelRackPos 1;
BA_ "SPN" SG_ 2633929470 EngGasMassFlowRate1 1241;
BA_ "SigType" SG_ 2633929470 EngGasMassFlowRate1 1;
BA_ "SPN" SG_ 2633929470 InstantaneousEstBrakePower 1242;
BA_ "SigType" SG_ 2633929470 InstantaneousEstBrakePower 1;
BA_ "SPN" SG_ 2633929470 EngExhaustGasPress 1209;
BA_ "SigType" SG_ 2633929470 EngExhaustGasPress 1;
BA_ "SPN" SG_ 2633929470 EngPrefilterOilPress 1208;
BA_ "SigType" SG_ 2633929470 EngPrefilterOilPress 1;
BA_ "GenMsgCycleTime" BO_ 2364541694 50;
BA_ "GenMsgSendType" BO_ 2364541694 0;
BA_ "SPN" SG_ 2364541694 EngIntakeAirMassFlowRate 132;
BA_ "SigType" SG_ 2364541694 EngIntakeAirMassFlowRate 1;
BA_ "SPN" SG_ 2364541694 EngExhstGsRcrclton2MassFlowRate 5257;
BA_ "SigType" SG_ 2364541694 EngExhstGsRcrclton2MassFlowRate 1;
BA_ "SPN" SG_ 2364541694 EngExhstGsRcrclton1MassFlowRate 2659;
BA_ "SigType" SG_ 2364541694 EngExhstGsRcrclton1MassFlowRate 1;
BA_ "GenMsgCycleTime" BO_ 2566840318 250;
BA_ "GenMsgSendType" BO_ 2566840318 0;
BA_ "SPN" SG_ 2566840318 EngsDsrdOprtngSpdAsymmtryAdjstmn 519;
BA_ "SigType" SG_ 2566840318 EngsDsrdOprtngSpdAsymmtryAdjstmn 1;
BA_ "SystemSignalLongSymbol" SG_ 2566840318 EngsDsrdOprtngSpdAsymmtryAdjstmn "EngsDsrdOprtngSpdAsymmtryAdjstmnt";
BA_ "SPN" SG_ 2566840318 Aftrtratment1ExhaustGasMassFlow 3236;
BA_ "SigType" SG_ 2566840318 Aftrtratment1ExhaustGasMassFlow 1;
BA_ "SPN" SG_ 2566840318 Aftertreatment2IntakeDewPoint 3239;
BA_ "SigType" SG_ 2566840318 Aftertreatment2IntakeDewPoint 4;
BA_ "SPN" SG_ 2566840318 Aftertreatment2ExhaustDewPoint 3240;
BA_ "SigType" SG_ 2566840318 Aftertreatment2ExhaustDewPoint 4;
BA_ "SPN" SG_ 2566840318 Aftertreatment1IntakeDewPoint 3237;
BA_ "SigType" SG_ 2566840318 Aftertreatment1IntakeDewPoint 4;
BA_ "SPN" SG_ 2566840318 Aftertreatment1ExhaustDewPoint 3238;
BA_ "SigType" SG_ 2566840318 Aftertreatment1ExhaustDewPoint 4;
BA_ "SPN" SG_ 2566840318 EstEngPrsticLossesPercentTorque 2978;
BA_ "SigType" SG_ 2566840318 EstEngPrsticLossesPercentTorque 1;
BA_ "SPN" SG_ 2566840318 EngsDesiredOperatingSpeed 515;
BA_ "SigType" SG_ 2566840318 EngsDesiredOperatingSpeed 1;
BA_ "SPN" SG_ 2566840318 NominalFrictionPercentTorque 514;
BA_ "SigType" SG_ 2566840318 NominalFrictionPercentTorque 1;
BA_ "GenMsgCycleTime" BO_ 2364539902 50;
BA_ "GenMsgSendType" BO_ 2364539902 0;
BA_ "SPN" SG_ 2364539902 SCRThermalManagementActive 5400;
BA_ "SigType" SG_ 2364539902 SCRThermalManagementActive 4;
BA_ "SPN" SG_ 2364539902 MmntryEngMaxPowerEnableFeedback 5021;
BA_ "SigType" SG_ 2364539902 MmntryEngMaxPowerEnableFeedback 4;
BA_ "SPN" SG_ 2364539902 EstPumpingPercentTorque 5398;
BA_ "SigType" SG_ 2364539902 EstPumpingPercentTorque 1;
BA_ "SPN" SG_ 2364539902 DPFThermalManagementActive 5399;
BA_ "SigType" SG_ 2364539902 DPFThermalManagementActive 4;
BA_ "SPN" SG_ 2364539902 ActlMxAvailableEngPercentTorque 3357;
BA_ "SigType" SG_ 2364539902 ActlMxAvailableEngPercentTorque 1;
BA_ "SPN" SG_ 2364539902 AccelPedalPos2 29;
BA_ "SigType" SG_ 2364539902 AccelPedalPos2 1;
BA_ "SPN" SG_ 2364539902 VhclAccelerationRateLimitStatus 2979;
BA_ "SigType" SG_ 2364539902 VhclAccelerationRateLimitStatus 4;
BA_ "SPN" SG_ 2364539902 EngPercentLoadAtCurrentSpeed 92;
BA_ "SigType" SG_ 2364539902 EngPercentLoadAtCurrentSpeed 1;
BA_ "SPN" SG_ 2364539902 AccelPedal2LowIdleSwitch 2970;
BA_ "SigType" SG_ 2364539902 AccelPedal2LowIdleSwitch 4;
BA_ "SPN" SG_ 2364539902 RoadSpeedLimitStatus 1437;
BA_ "SigType" SG_ 2364539902 RoadSpeedLimitStatus 4;
BA_ "SPN" SG_ 2364539902 AccelPedalKickdownSwitch 559;
BA_ "SigType" SG_ 2364539902 AccelPedalKickdownSwitch 4;
BA_ "SPN" SG_ 2364539902 AccelPedal1LowIdleSwitch 558;
BA_ "SigType" SG_ 2364539902 AccelPedal1LowIdleSwitch 4;
BA_ "SPN" SG_ 2364539902 RemoteAccelPedalPos 974;
BA_ "SigType" SG_ 2364539902 RemoteAccelPedalPos 1;
BA_ "SPN" SG_ 2364539902 AccelPedalPos1 91;
BA_ "SigType" SG_ 2364539902 AccelPedalPos1 1;
BA_ "GenMsgCycleTime" BO_ 2364540158 100;
BA_ "GenMsgSendType" BO_ 2364540158 0;
BA_ "SPN" SG_ 2364540158 SrcAddrssOfCtrllngDvcFrEngCntrl 1483;
BA_ "SigType" SG_ 2364540158 SrcAddrssOfCtrllngDvcFrEngCntrl 1;
BA_ "SPN" SG_ 2364540158 ActlEngPrcntTrqueHighResolution 4154;
BA_ "SigType" SG_ 2364540158 ActlEngPrcntTrqueHighResolution 1;
BA_ "SPN" SG_ 2364540158 EngDemandPercentTorque 2432;
BA_ "SigType" SG_ 2364540158 EngDemandPercentTorque 1;
BA_ "SPN" SG_ 2364540158 EngStarterMode 1675;
BA_ "SigType" SG_ 2364540158 EngStarterMode 4;
BA_ "SPN" SG_ 2364540158 EngSpeed 190;
BA_ "SigType" SG_ 2364540158 EngSpeed 1;
BA_ "SPN" SG_ 2364540158 ActualEngPercentTorque 513;
BA_ "SigType" SG_ 2364540158 ActualEngPercentTorque 1;
BA_ "SPN" SG_ 2364540158 DriversDemandEngPercentTorque 512;
BA_ "SigType" SG_ 2364540158 DriversDemandEngPercentTorque 1;
BA_ "SPN" SG_ 2364540158 EngTorqueMode 899;
BA_ "SigType" SG_ 2364540158 EngTorqueMode 4;
BA_ "SPN" SG_ 2566841342 SupportTSC1CtrlPurposeGroup4 3348;
BA_ "SigType" SG_ 2566841342 SupportTSC1CtrlPurposeGroup4 1;
BA_ "SPN" SG_ 2566841342 SupportTSC1CtrlPurposeGroup3 3347;
BA_ "SigType" SG_ 2566841342 SupportTSC1CtrlPurposeGroup3 1;
BA_ "SPN" SG_ 2566841342 SupportTSC1CtrlPurposeGroup2 3346;
BA_ "SigType" SG_ 2566841342 SupportTSC1CtrlPurposeGroup2 1;
BA_ "SPN" SG_ 2566841342 SupportTSC1CtrlPurposeGroup1 3345;
BA_ "SigType" SG_ 2566841342 SupportTSC1CtrlPurposeGroup1 1;
BA_ "SPN" SG_ 2566841342 SupportVariableRateTSC1Message 3344;
BA_ "SigType" SG_ 2566841342 SupportVariableRateTSC1Message 1;
BA_ "SPN" SG_ 2566841342 EngDefaultTorqueLimit 1846;
BA_ "SigType" SG_ 2566841342 EngDefaultTorqueLimit 1;
BA_ "SPN" SG_ 2566841342 EngMomentOfInertia 1794;
BA_ "SigType" SG_ 2566841342 EngMomentOfInertia 1;
BA_ "SPN" SG_ 2566841342 EngExRngRqdSpdCtrlRngUpperLimit 1712;
BA_ "SigType" SG_ 2566841342 EngExRngRqdSpdCtrlRngUpperLimit 1;
BA_ "SPN" SG_ 2566841342 EngRqdTorqueCtrlRangeUpperLimit 538;
BA_ "SigType" SG_ 2566841342 EngRqdTorqueCtrlRangeUpperLimit 1;
BA_ "SPN" SG_ 2566841342 EngRqdTorqueCtrlRangeLowerLimit 537;
BA_ "SigType" SG_ 2566841342 EngRqdTorqueCtrlRangeLowerLimit 1;
BA_ "SPN" SG_ 2566841342 EngRqedSpeedCtrlRangeUpperLimit 536;
BA_ "SigType" SG_ 2566841342 EngRqedSpeedCtrlRangeUpperLimit 1;
BA_ "SPN" SG_ 2566841342 EngRqedSpeedCtrlRangeLowerLimit 535;
BA_ "SigType" SG_ 2566841342 EngRqedSpeedCtrlRangeLowerLimit 1;
BA_ "SPN" SG_ 2566841342 EngMxMomentaryOverrideTimeLimit 534;
BA_ "SigType" SG_ 2566841342 EngMxMomentaryOverrideTimeLimit 1;
BA_ "SPN" SG_ 2566841342 EngMxMmntaryOverrideSpeedPoint7 533;
BA_ "SigType" SG_ 2566841342 EngMxMmntaryOverrideSpeedPoint7 1;
BA_ "SPN" SG_ 2566841342 EngReferenceTorque 544;
BA_ "SigType" SG_ 2566841342 EngReferenceTorque 1;
BA_ "SPN" SG_ 2566841342 EngSpeedAtHighIdlePoint6 532;
BA_ "SigType" SG_ 2566841342 EngSpeedAtHighIdlePoint6 1;
BA_ "SPN" SG_ 2566841342 EngGainOfEndspeedGovernor 545;
BA_ "SigType" SG_ 2566841342 EngGainOfEndspeedGovernor 1;
BA_ "SPN" SG_ 2566841342 EngPercentTorqueAtPoint5 543;
BA_ "SigType" SG_ 2566841342 EngPercentTorqueAtPoint5 1;
BA_ "SPN" SG_ 2566841342 EngSpeedAtPoint5 531;
BA_ "SigType" SG_ 2566841342 EngSpeedAtPoint5 1;
BA_ "SPN" SG_ 2566841342 EngPercentTorqueAtPoint4 542;
BA_ "SigType" SG_ 2566841342 EngPercentTorqueAtPoint4 1;
BA_ "SPN" SG_ 2566841342 EngSpeedAtPoint4 530;
BA_ "SigType" SG_ 2566841342 EngSpeedAtPoint4 1;
BA_ "SPN" SG_ 2566841342 EngPercentTorqueAtPoint3 541;
BA_ "SigType" SG_ 2566841342 EngPercentTorqueAtPoint3 1;
BA_ "SPN" SG_ 2566841342 EngSpeedAtPoint3 529;
BA_ "SigType" SG_ 2566841342 EngSpeedAtPoint3 1;
BA_ "SPN" SG_ 2566841342 EngPercentTorqueAtPoint2 540;
BA_ "SigType" SG_ 2566841342 EngPercentTorqueAtPoint2 1;
BA_ "SPN" SG_ 2566841342 EngSpeedAtPoint2 528;
BA_ "SigType" SG_ 2566841342 EngSpeedAtPoint2 1;
BA_ "SPN" SG_ 2566841342 EngPercentTorqueAtIdlePoint1 539;
BA_ "SigType" SG_ 2566841342 EngPercentTorqueAtIdlePoint1 1;
BA_ "SPN" SG_ 2566841342 EngSpeedAtIdlePoint1 188;
BA_ "SigType" SG_ 2566841342 EngSpeedAtIdlePoint1 1;
BA_ "GenMsgCycleTime" BO_ 2566844926 100;
BA_ "GenMsgSendType" BO_ 2566844926 0;
BA_ "SPN" SG_ 2566844926 ParkBrakeReleaseInhibitRq 3807;
BA_ "SigType" SG_ 2566844926 ParkBrakeReleaseInhibitRq 4;
BA_ "SPN" SG_ 2566844926 PTOGovernorState 976;
BA_ "SigType" SG_ 2566844926 PTOGovernorState 4;
BA_ "SPN" SG_ 2566844926 EngShutdownOverrideSwitch 1237;
BA_ "SigType" SG_ 2566844926 EngShutdownOverrideSwitch 4;
BA_ "SPN" SG_ 2566844926 EngTestModeSwitch 966;
BA_ "SigType" SG_ 2566844926 EngTestModeSwitch 4;
BA_ "SPN" SG_ 2566844926 EngIdleDecrementSwitch 967;
BA_ "SigType" SG_ 2566844926 EngIdleDecrementSwitch 4;
BA_ "SPN" SG_ 2566844926 EngIdleIncrementSwitch 968;
BA_ "SigType" SG_ 2566844926 EngIdleIncrementSwitch 4;
BA_ "SPN" SG_ 2566844926 CruiseCtrlStates 527;
BA_ "SPN" SG_ 2566844926 CruiseCtrlSetSpeed 86;
BA_ "SigType" SG_ 2566844926 CruiseCtrlSetSpeed 1;
BA_ "SPN" SG_ 2566844926 CruiseCtrlAccelerateSwitch 602;
BA_ "SigType" SG_ 2566844926 CruiseCtrlAccelerateSwitch 4;
BA_ "SPN" SG_ 2566844926 CruiseCtrlResumeSwitch 601;
BA_ "SigType" SG_ 2566844926 CruiseCtrlResumeSwitch 4;
BA_ "SPN" SG_ 2566844926 CruiseCtrlCoastSwitch 600;
BA_ "SigType" SG_ 2566844926 CruiseCtrlCoastSwitch 4;
BA_ "SPN" SG_ 2566844926 CruiseCtrlSetSwitch 599;
BA_ "SigType" SG_ 2566844926 CruiseCtrlSetSwitch 4;
BA_ "SPN" SG_ 2566844926 ClutchSwitch 598;
BA_ "SigType" SG_ 2566844926 ClutchSwitch 4;
BA_ "SPN" SG_ 2566844926 BrakeSwitch 597;
BA_ "SigType" SG_ 2566844926 BrakeSwitch 4;
BA_ "SPN" SG_ 2566844926 CruiseCtrlEnableSwitch 596;
BA_ "SigType" SG_ 2566844926 CruiseCtrlEnableSwitch 4;
BA_ "SPN" SG_ 2566844926 CruiseCtrlActive 595;
BA_ "SigType" SG_ 2566844926 CruiseCtrlActive 4;
BA_ "SPN" SG_ 2566844926 WheelBasedVehicleSpeed 84;
BA_ "SigType" SG_ 2566844926 WheelBasedVehicleSpeed 1;
BA_ "SPN" SG_ 2566844926 CruiseCtrlPauseSwitch 1633;
BA_ "SigType" SG_ 2566844926 CruiseCtrlPauseSwitch 4;
BA_ "SPN" SG_ 2566844926 ParkingBrakeSwitch 70;
BA_ "SigType" SG_ 2566844926 ParkingBrakeSwitch 4;
BA_ "SPN" SG_ 2566844926 TwoSpeedAxleSwitch 69;
BA_ "SigType" SG_ 2566844926 TwoSpeedAxleSwitch 4;
BA_ "GenMsgCycleTime" BO_ 2566763774 500;
BA_ "GenMsgSendType" BO_ 2566763774 0;
BA_ "SPN" SG_ 2566763774 Aftrtrtmnt1DslPrtcltFltrIntkGsTm 3244;
BA_ "SigType" SG_ 2566763774 Aftrtrtmnt1DslPrtcltFltrIntkGsTm 1;
BA_ "SystemSignalLongSymbol" SG_ 2566763774 Aftrtrtmnt1DslPrtcltFltrIntkGsTm "Aftrtrtmnt1DslPrtcltFltrIntkGsTmpPrlmnryFMI";
BA_ "SPN" SG_ 2566763774 Aftrtrtmnt1ExhstGsTmp1PrlmnryFMI 3243;
BA_ "SPN" SG_ 2566763774 Aftertreatment1ExhaustGasTemp1 3241;
BA_ "SigType" SG_ 2566763774 Aftertreatment1ExhaustGasTemp1 1;
BA_ "SPN" SG_ 2566763774 Aftrtrtmnt1DslPrtcltFltrInt_0000 3242;
BA_ "SigType" SG_ 2566763774 Aftrtrtmnt1DslPrtcltFltrInt_0000 1;
BA_ "SystemSignalLongSymbol" SG_ 2566763774 Aftrtrtmnt1DslPrtcltFltrInt_0000 "Aftrtrtmnt1DslPrtcltFltrIntkGsTmp";
BA_ "GenMsgCycleTime" BO_ 2566763262 500;
BA_ "GenMsgSendType" BO_ 2566763262 0;
BA_ "SPN" SG_ 2566763262 Aftrtrtmnt1DslPrtcltFltrIntrmdtG 3254;
BA_ "SigType" SG_ 2566763262 Aftrtrtmnt1DslPrtcltFltrIntrmdtG 1;
BA_ "SystemSignalLongSymbol" SG_ 2566763262 Aftrtrtmnt1DslPrtcltFltrIntrmdtG "Aftrtrtmnt1DslPrtcltFltrIntrmdtGsTmpPrlmnryFMI";
BA_ "SPN" SG_ 2566763262 Aftrtrtmnt1DslPrtcltFltrInt_0001 3250;
BA_ "SigType" SG_ 2566763262 Aftrtrtmnt1DslPrtcltFltrInt_0001 1;
BA_ "SystemSignalLongSymbol" SG_ 2566763262 Aftrtrtmnt1DslPrtcltFltrInt_0001 "Aftrtrtmnt1DslPrtcltFltrIntrmdtGsTmp";
BA_ "SPN" SG_ 2566763262 Aftrtrtmnt1DslPrtcltFltrDltPrssP 3253;
BA_ "SigType" SG_ 2566763262 Aftrtrtmnt1DslPrtcltFltrDltPrssP 1;
BA_ "SystemSignalLongSymbol" SG_ 2566763262 Aftrtrtmnt1DslPrtcltFltrDltPrssP "Aftrtrtmnt1DslPrtcltFltrDltPrssPrlmnryFMI";
BA_ "SPN" SG_ 2566763262 Aftrtrtmnt1DslPrtcltFltrDffPrss 3251;
BA_ "SigType" SG_ 2566763262 Aftrtrtmnt1DslPrtcltFltrDffPrss 1;
BA_ "SPN" SG_ 2566763262 Aftrtrtmnt1ExhstGsTmp2PrlmnryFMI 3252;
BA_ "SPN" SG_ 2566763262 Aftertreatment1ExhaustGasTemp2 3249;
BA_ "SigType" SG_ 2566763262 Aftertreatment1ExhaustGasTemp2 1;
BA_ "GenMsgCycleTime" BO_ 2566763518 500;
BA_ "GenMsgSendType" BO_ 2566763518 0;
BA_ "SPN" SG_ 2566763518 Aftrtrtmnt1DslPrtcltFltrOtltGsTm 3246;
BA_ "SigType" SG_ 2566763518 Aftrtrtmnt1DslPrtcltFltrOtltGsTm 1;
BA_ "SystemSignalLongSymbol" SG_ 2566763518 Aftrtrtmnt1DslPrtcltFltrOtltGsTm "Aftrtrtmnt1DslPrtcltFltrOtltGsTmp";
BA_ "SPN" SG_ 2566763518 Aftrtrtmnt1DslPrtcltFltrOtltExhs 3248;
BA_ "SigType" SG_ 2566763518 Aftrtrtmnt1DslPrtcltFltrOtltExhs 1;
BA_ "SystemSignalLongSymbol" SG_ 2566763518 Aftrtrtmnt1DslPrtcltFltrOtltExhs "Aftrtrtmnt1DslPrtcltFltrOtltExhstGsTmpPrlmnryFMI";
BA_ "SPN" SG_ 2566763518 Aftrtrtmnt1ExhstGsTmp3PrlmnryFMI 3247;
BA_ "SPN" SG_ 2566763518 Aftertreatment1ExhaustGasTemp3 3245;
BA_ "SigType" SG_ 2566763518 Aftertreatment1ExhaustGasTemp3 1;
BA_ "VFrameFormat" BO_ 256 0;
VAL_ 2566749438 DslPrtcltFltrActvRgnrtnFrcdStts 7 "notAvailable" 6 "ReservedForSAEAssignment" 2 "ActiveForcedByServiceTool" 1 "ActiveForcedBySwitch" 0 "NotActive" ;
VAL_ 2566749438 ExhaustSystemHighTempLampCmd 7 "notAvailable" 6 "reservedForSAEAssignment" 1 "OnSolid" 0 "Off" ;
VAL_ 2566749438 DslPrtcltFltrAtmtcActvRgnrtnIntt 3 "notAvailable" 2 "reservedForSAEAssignment" 1 "enabled" 0 "notEnabled" ;
VAL_ 2566749438 DslPrtcltFltrActvRgnrtnInhbtdDTV 3 "notAvailable" 2 "reservedForSAEAssignment" 1 "inhibited" 0 "notInhibited" ;
VAL_ 2566749438 DslPrtcltFltrActvRgnrtnInhbtdDTE 3 "notAvailable" 2 "reservedForSAEAssignment" 1 "inhibited" 0 "notInhibited" ;
VAL_ 2566749438 DslPrtcltFltrActvRgnrtnInhbtdDTP 3 "notAvailable" 2 "reservedForSAEAssignment" 1 "inhibited" 0 "notInhibited" ;
VAL_ 2566749438 DslPrtcltFltrActvRgnrtnInhbtdDTT 3 "notAvailable" 2 "reservedForSAEAssignment" 1 "inhibited" 0 "notInhibited" ;
VAL_ 2566749438 DslPrtcltFltrActvRgnrtnInhbtdDTS 3 "notAvailable" 2 "reservedForSAEAssignment" 1 "inhibited" 0 "notInhibited" ;
VAL_ 2566749438 DslPrtcltFltrActvRgnrtnInhb_0000 3 "notAvailable" 2 "reservedForSAEAssignment" 1 "inhibited" 0 "notInhibited" ;
VAL_ 2566749438 DslPrtcltFltrActvRgnrtnInhbtdDTL 3 "notAvailable" 2 "reservedForSAEAssignment" 1 "inhibited" 0 "notInhibited" ;
VAL_ 2566749438 DslPrtcltFltrActvRgnrtnInhb_0001 3 "notAvailable" 2 "reservedForSAEAssignment" 1 "inhibited" 0 "notInhibited" ;
VAL_ 2566749438 DslPrtcltFltrActvRgnrtnInhb_0002 3 "notAvailable" 2 "reservedForSAEAssignment" 1 "inhibited" 0 "notInhibited" ;
VAL_ 2566749438 DslPrtcltFltrActvRgnrtnInhbtdDTO 3 "notAvailable" 2 "reservedForSAEAssignment" 1 "inhibited" 0 "notInhibited" ;
VAL_ 2566749438 DslPrtcltFltrActvRgnrtnInhbtdDTA 3 "notAvailable" 2 "reservedForSAEAssignment" 1 "inhibited" 0 "notInhibited" ;
VAL_ 2566749438 DslPrtcltFltrActvRgnrtnInhb_0003 3 "notAvailable" 2 "reservedForSAEAssignment" 1 "inhibited" 0 "notInhibited" ;
VAL_ 2566749438 DslPrtcltFltrActvRgnrtnInhb_0004 3 "notAvailable" 2 "reservedForSAEAssignment" 1 "inhibited" 0 "notInhibited" ;
VAL_ 2566749438 DslPrtcltFltrActvRgnrtnInhbtdDTC 3 "notAvailable" 2 "reservedForSAEAssignment" 1 "inhibited" 0 "notInhibited" ;
VAL_ 2566749438 DslPrtcltFltrActvRgnrtnInhbtdDTI 3 "notAvailable" 2 "reservedForSAEAssignment" 1 "inhibited" 0 "notInhibited" ;
VAL_ 2566749438 DslPrtcltFltrActvRgnrtnInhbtdStt 3 "notAvailable" 2 "reservedForSAEAssignment" 1 "inhibited" 0 "notInhibited" ;
VAL_ 2566749438 DieselParticulateFilterStatus 7 "notAvailable" 6 "reservedForSAEAssignment" 3 "RegenerationNeededHighestLevel" 2 "RegenerationNeededModerateLevel" 1 "RegenerationNeededLowestLevel" 0 "RegenerationNotNeeded" ;
VAL_ 2566749438 DslPrtcltFltrActvRgnrtionStatus 3 "notAvailable" 2 "rgnrtnNddAtmtcllyInttdActvRgnrt" 1 "active" 0 "notActive" ;
VAL_ 2566749438 DslPrtcltFltrPssvRgnrtionStatus 3 "notAvailable" 2 "reservedForSAEAssignment" 1 "active" 0 "notActive" ;
VAL_ 2566749438 DieselParticulateFilterLampCmd 7 "notAvailable" 4 "OnFastBlink" 6 "reservedForSAEAssignment" 1 "OnSolid" 0 "Off" ;
VAL_ 2566840318 Aftertreatment2IntakeDewPoint 3 "NotAvailable" 2 "Error" 1 "ExceededDewPoint" 0 "NotExceededDewPoint" ;
VAL_ 2566840318 Aftertreatment2ExhaustDewPoint 3 "NotAvailable" 2 "Error" 1 "ExceededDewPoint" 0 "NotExceededDewPoint" ;
VAL_ 2566840318 Aftertreatment1IntakeDewPoint 3 "NotAvailable" 2 "Error" 1 "ExceededDewPoint" 0 "NotExceededDewPoint" ;
VAL_ 2566840318 Aftertreatment1ExhaustDewPoint 3 "NotAvailable" 2 "Error" 1 "ExceededDewPoint" 0 "NotExceededDewPoint" ;
VAL_ 2566840318 EstEngPrsticLossesPercentTorque 251 "LossesAreIncludedInSPN514" ;
VAL_ 2364539902 SCRThermalManagementActive 3 "DontCare" 2 "Reserved" 1 "SCRThermalManagementIsActive" 0 "SCRThermalManagementIsNotActive" ;
VAL_ 2364539902 MmntryEngMaxPowerEnableFeedback 3 "dontCare" 2 "reserved" 1 "supported" 0 "disabled" ;
VAL_ 2364539902 DPFThermalManagementActive 3 "DontCare" 2 "Reserved" 1 "DPFThermalManagementIsActive" 0 "DPFThermalManagementIsNotActive" ;
VAL_ 2364539902 VhclAccelerationRateLimitStatus 3 "NotAvailable" 2 "Reserved" 1 "LimitActive" 0 "LimitNotActive" ;
VAL_ 2364539902 AccelPedal2LowIdleSwitch 3 "NotAvailable" 2 "Error" 1 "AccelPedal2InLowIdleCondition" 0 "AcclPedal2NotInLowIdleCondition" ;
VAL_ 2364539902 RoadSpeedLimitStatus 3 "NotAvailable" 2 "Error" 1 "NotActive" 0 "Active" ;
VAL_ 2364539902 AccelPedalKickdownSwitch 3 "NotAvailable" 2 "Error" 1 "KickdownActive" 0 "KickdownPassive" ;
VAL_ 2364539902 AccelPedal1LowIdleSwitch 3 "NotAvailable" 2 "Error" 1 "AccelPedal1InLowIdleCondition" 0 "AcclPedal1NotInLowIdleCondition" ;
VAL_ 2364540158 ActlEngPrcntTrqueHighResolution 8 "1111NotAvailable" 7 "0875" 1 "0125" 0 "0000" ;
VAL_ 2364540158 EngStarterMode 15 "notAvailable" 14 "error" 12 "starterInhibitedReasonUnknown" 9 "1011Reserved" 8 "strtrInhbtdDueToStarterOvertemp" 7 "strtrInhbtdDToActiveImmobilizer" 6 "strtrInhbtdDTDrvlnEnggdOthrTrns" 5 "strtrInhbtdDTEngNtReadyForStart" 4 "strtrInhbtdDToEngAlreadyRunning" 3 "strtFnshdStrtrNtActvAftrHvngBnA" 2 "starterActiveGearEngaged" 1 "starterActiveGearNotEngaged" 0 "startNotRqed" ;
VAL_ 2364540158 EngTorqueMode 15 "Not available" 11 "Remote accelerator" 10 "Braking system" 9 "High speed governor" 8 "Torque limiting" 7 "ABS control" 6 "Transmission control" 5 "ASR control" 4 "Road speed governor" 3 "PTO governor" 2 "Cruise control" 1 "Accelerator pedal/operator selec" 0 "Low idle governor/no request (de" ;
VAL_ 2566841342 SupportTSC1CtrlPurposeGroup4 1 "P25ReservedForAssignmentBySAE" ;
VAL_ 2566841342 SupportTSC1CtrlPurposeGroup3 1 "P17ReservedForAssignmentBySAE" ;
VAL_ 2566841342 SupportTSC1CtrlPurposeGroup2 1 "P9ReservedForAssignmentBySAE" ;
VAL_ 2566841342 SupportTSC1CtrlPurposeGroup1 1 "P1AccelPedal_OperatorSelection" ;
VAL_ 2566841342 SupportVariableRateTSC1Message 1 "MsTransRate" ;
VAL_ 2566844926 ParkBrakeReleaseInhibitRq 3 "Unavailable" 2 "SAEReserved" 1 "ParkBrakeReleaseInhibitRqed" 0 "ParkBrakeReleaseInhibitNotRqed" ;
VAL_ 2566844926 PTOGovernorState 31 "NotAvailable" 20 "11110NotDefined" 19 "PTOSetSpeedMemory2" 18 "PTOSetSpeedMemory1" 17 "PreprogrammedSetSpeed8" 16 "PreprogrammedSetSpeed7" 15 "PreprogrammedSetSpeed6" 14 "PreprogrammedSetSpeed5" 13 "PreprogrammedSetSpeed4" 12 "PreprogrammedSetSpeed3" 11 "PreprogrammedSetSpeed2" 10 "PreprogrammedSetSpeed1" 9 "AccelOverride" 8 "Accelerate" 7 "Resume" 6 "Decelerate_Coast" 5 "Set" 4 "RemoteStandby" 3 "Standby" 2 "RemoteHold" 1 "Hold" 0 "Off_Disabled" ;
VAL_ 2566844926 EngShutdownOverrideSwitch 3 "NotAvailable" 2 "Error" 1 "On" 0 "Off" ;
VAL_ 2566844926 EngTestModeSwitch 3 "NotAvailable" 2 "Error" 1 "On" 0 "Off" ;
VAL_ 2566844926 EngIdleDecrementSwitch 3 "NotAvailable" 2 "Error" 1 "On" 0 "Off" ;
VAL_ 2566844926 EngIdleIncrementSwitch 3 "NotAvailable" 2 "Error" 1 "On" 0 "Off" ;
VAL_ 2566844926 CruiseCtrlStates 7 "NotAvailable" 6 "AccelOverride" 5 "Set" 4 "Resume" 3 "Decelerate" 2 "Accelerate" 1 "Hold" 0 "Off_Disabled" ;
VAL_ 2566844926 CruiseCtrlAccelerateSwitch 3 "NotAvailable" 2 "Error" 1 "CrsCtrlActivatorInPosAccelerate" 0 "CrsCtrlActvtrNotInPosAccelerate" ;
VAL_ 2566844926 CruiseCtrlResumeSwitch 3 "NotAvailable" 2 "Error" 1 "CruiseCtrlActivatorInPosResume" 0 "CrseCtrlActivatorNotInPosResume" ;
VAL_ 2566844926 CruiseCtrlCoastSwitch 3 "NotAvailable" 2 "Error" 1 "CruiseCtrlActivatorInPosCoast" 0 "CriseCtrlActivatorNotInPosCoast" ;
VAL_ 2566844926 CruiseCtrlSetSwitch 3 "NotAvailable" 2 "Error" 1 "CruiseCtrlActivatorInPosSet" 0 "CruiseCtrlActivatorNotInPosSet" ;
VAL_ 2566844926 ClutchSwitch 3 "NotAvailable" 2 "Error" 1 "ClutchPedalDepressed" 0 "ClutchPedalReleased" ;
VAL_ 2566844926 BrakeSwitch 3 "NotAvailable" 2 "Error" 1 "BrakePedalDepressed" 0 "BrakePedalReleased" ;
VAL_ 2566844926 CruiseCtrlEnableSwitch 3 "NotAvailable" 2 "Error" 1 "CruiseCtrlEnabled" 0 "CruiseCtrlDisabled" ;
VAL_ 2566844926 CruiseCtrlActive 3 "NotAvailable" 2 "Error" 1 "CruiseCtrlSwitchedOn" 0 "CruiseCtrlSwitchedOff" ;
VAL_ 2566844926 CruiseCtrlPauseSwitch 3 "TakeNoAction" 2 "ErrorIndicator" 1 "On" 0 "Off" ;
VAL_ 2566844926 ParkingBrakeSwitch 3 "NotAvailable" 2 "Error" 1 "ParkingBrakeSet" 0 "ParkingBrakeNotSet" ;
VAL_ 2566844926 TwoSpeedAxleSwitch 3 "NotAvailable" 2 "Error" 1 "HighSpeedRange" 0 "LowSpeedRange" ;
